[part 2 of 4: packages /BMW/SystemDescription/EcuInstances to /BMW/Boardnet/Clusters/CommunicationClusters]
AUTOSAR XML (schema 4-3-0)
package /BMW/SystemDescription/EcuInstances
  ecu instance EPS: associated-com-i-pdu-group=[EPS_IN_PduGroup, EPS_OUT_PduGroup, EPS_IN_PduGroup2, EPS_OUT_PduGroup2, EPS_IN_PduGroup3, EPS_IN_PduGroup4, EPS_IN_PduGroup5, EPS_IN_PduGroup6, EPS_IN_PduGroup7, EPS_IN_PduGroup8, EPS_IN_PduGroup9, EPS_OUT_PduGroup3, EPS_IN_PduGroup10], client-id-range={lower-limit=12288, upper-limit=12543}, diagnostic-address=48, sleep-mode-supported=false, wake-up-over-bus-supported=false  # Electrical Power - Assist - Steering | Achsparalleles EPS (electrical power-assist steering): System steuert unmittelbar Lenkschenkel an | MCV 0.94.5
    flexray communication controller contr_EPS_A_FlexRay:  # component: Electrical Power - Assist - Steering, bus: A-FlexRay / component: , bus: A-FlexRay
      accepted-startup-range=212
      allow-halt-due-to-clock=true
      allow-passive-to-active=0
      cluster-drift-damping=2
      decoding-correction=48
      delay-compensation-a=1
      delay-compensation-b=1
      extern-offset-correction=0
      extern-rate-correction=0
      key-slot-id=0
      key-slot-only-enabled=false
      key-slot-used-for-start-up=false
      key-slot-used-for-sync=false
      latest-tx=269
      listen-timeout=400242
      macro-initial-offset-a=3
      macro-initial-offset-b=3
      maximum-dynamic-payload-length=60
      micro-initial-offset-a=6
      micro-initial-offset-b=6
      micro-per-cycle=200000
      microtick-duration=2.5E-8
      offset-correction-out=126
      rate-correction-out=121
      samples-per-microtick=2
      wake-up-pattern=33
    flexray communication controller EPS_A_FlexRay:  # component: Electrical Power - Assist - Steering, bus: A-FlexRay / component: , bus: A-FlexRay
      accepted-startup-range=212
      allow-halt-due-to-clock=true
      allow-passive-to-active=0
      cluster-drift-damping=2
      decoding-correction=48
      delay-compensation-a=1
      delay-compensation-b=1
      extern-offset-correction=0
      extern-rate-correction=0
      key-slot-id=0
      key-slot-only-enabled=false
      key-slot-used-for-start-up=false
      key-slot-used-for-sync=false
      latest-tx=269
      listen-timeout=400242
      macro-initial-offset-a=3
      macro-initial-offset-b=3
      maximum-dynamic-payload-length=60
      micro-initial-offset-a=6
      micro-initial-offset-b=6
      micro-per-cycle=200000
      microtick-duration=2.5E-8
      offset-correction-out=126
      rate-correction-out=121
      samples-per-microtick=2
      wake-up-pattern=33
    flexray communication connector con_EPS_A_FlexRay: comm-controller=contr_EPS_A_FlexRay, wake-up-channel=true
    flexray communication connector con_EPS_FibexID_0b7e5e09c061465d913e8968ece3cded: comm-controller=EPS_A_FlexRay, wake-up-channel=true
package /BMW/SystemDescription/Units
  15 x unit:
    kilometer_per_hour: display-name=km/h
    meter_per_second_squared: display-name=m/s²
    kilonewton: display-name=kN
    kilowatt: display-name=kW
    degree_celsius: display-name=°C
    no_unit  # This unit fulfills the required AUTOSAR reference to a unit. No real unit is defined.
    radian_per_second: display-name=rad/s
    kilometer: display-name=km
    newton_meter: display-name=Nm
    liter: display-name=l
    ampere: display-name=A
    millisecond: display-name=ms
    percent: display-name=%
    degree_per_second: display-name=°/s
    second: display-name=s
package /BMW/SystemDescription/CompuMethods
  compu method TRANF_CC_EPS: phys=raw; unit s  # Sendeart_Checkcontrol_EPS / transmitting-form_check-control_EPS
  compu method AVL_PWR_EL: phys=raw*0.1-12; unit kW  # Ist_Leistung_Elektrisch / actual-value_power_electric
  compu method NO_VECH_1: identical  # Nummer_Fahrgestell_1 / number_vehicle-chassis_1
  compu method OFFS_QUAD_PINA_EPS: phys=raw-127  # Offset_Quadrant_Ritzelwinkel_EPS / offset_quadrant_pinion-angle_EPS
  compu method ST_UDP: 0=Kein Spannungseinbruch (ST_UDP_Kein_Spannungseinbruch) (kein Spannungseinbruch angekündigt oder aktiv), 1=Startspannungseinbruch bis maximal Spannungsschwelle 1 (ST_UDP_Startspannungseinbruch_bis_maximal_Spannungsschwelle_1) (Spannungseinbruch bis Schwelle 1 aktiv (z.B. Ankündigung vor Einbruch, bei Ansteuerung Startsystem, Nachlauf nach Abwurf Startsystem bis Normalisierung des BN-Niveaus) Siehe GS95024-2-1 (Kap. 4.11.2.2) Warmstart), 2=Startspannungseinbruch bis maximal Spannungsschwelle 2 (ST_UDP_Startspannungseinbruch_bis_maximal_Spannungsschwelle_2) (Spannungseinbruch bis Schwelle 2 aktiv (z.B. Ankündigung vor Einbruch, bei Ansteuerung Startsystem, Nachlauf nach Abwurf Startsystem bis Normalisierung des BN-Niveaus) Siehe GS95024-2-1 (Kap. 4.11.2.1) Kaltstart), 13=Funktionsschnittstelle_ist_nicht_verfuegbar (ST_UDP_Funktionsschnittstelle_ist_nicht_verfuegbar) (DME in der Initialisierung (z.B. nach Reset)), 14=Reserviert (ST_UDP_Reserviert) (Hinweis: Reserviert für funktionale Kennung Signal-Tag.), 15=Signal_unbefuellt (ST_UDP_Signal_unbefuellt) (Sendefunktion nicht in Betrieb)  # Status_Spannungseinbruch / status_voltage-drop
  compu method QU_FN_FDR: mask 3848: 512=Funktion verfügbar und bereit, nicht aktiv, Schlupfschwellen normal (QU_FN_FDR_Funktion_verfuegbar_und_bereit_nicht_aktiv_Schlupfschwellen_normal), mask 3848: 520=Funktion verfügbar und bereit, nicht aktiv, Schlupfschwellen aufgeweitet (QU_FN_FDR_Funktion_verfuegbar_und_bereit_nicht_aktiv_Schlupfschwellen_aufgeweitet), mask 3856: 2576=Funktion verfügbar und aktiv, FDR Regeleingriff VL (QU_FN_FDR_Funktion_verfuegbar_und_aktiv_FDR_Regeleingriff_VL), mask 3872: 2592=Funktion verfügbar und aktiv, FDR Regeleingriff VR (QU_FN_FDR_Funktion_verfuegbar_und_aktiv_FDR_Regeleingriff_VR), mask 3904: 2624=Funktion verfügbar und aktiv, FDR Regeleingriff HL (QU_FN_FDR_Funktion_verfuegbar_und_aktiv_FDR_Regeleingriff_HL), mask 3968: 2688=Funktion verfügbar und aktiv, FDR Regeleingriff HR (QU_FN_FDR_Funktion_verfuegbar_und_aktiv_FDR_Regeleingriff_HR), mask 3848: 2560=Funktion verfügbar und aktiv, Schlupfschwellen normal (QU_FN_FDR_Funktion_verfuegbar_und_aktiv_Schlupfschwellen_normal), mask 3848: 2568=Funktion verfügbar und aktiv, Schlupfschwellen aufgeweitet (QU_FN_FDR_Funktion_verfuegbar_und_aktiv_Schlupfschwellen_aufgeweitet), mask 3840: 1536=Funktion nicht verfügbar: Fehler (QU_FN_FDR_Funktion_nicht_verfuegbar_Fehler), mask 3840: 3584=Funktion nicht verfügbar: Ausgeschaltet (QU_FN_FDR_Funktion_nicht_verfuegbar_Ausgeschaltet) (Diese Codierung wird versendet wenn mind. eine dieser Bedingungen erfüllt ist: Initialisierungsphase des SG (Vorbefüllung), Zündung=aus, Motorstart, INITAusblendung aktiv, Funktion über DTC-Taster deaktiviert), mask 3840: 2048=reserviert (QU_FN_FDR_reserviert), mask 3840: 512=reserviert (QU_FN_FDR_reserviert_2), mask 3848: 768=reserviert (QU_FN_FDR_reserviert_3), mask 3848: 776=reserviert (QU_FN_FDR_reserviert_4), mask 4095: 4095=Signal ungültig (QU_FN_FDR_Signal_ungueltig) (Nutzung nur vom Gateway, nicht seitens Sender-SG)  # Qualifier_Funktion_FDR / Qualifier_function_FDR
  compu method TEMP_CPO_HET_MNG: phys=raw-48 for raw 0..252, 253=Reserviert (TEMP_CPO_HET_MNG_Reserviert) (Hinweis: Reserviert für funktionale Kennung Signal-Tag.), 254=Reserviert (TEMP_CPO_HET_MNG_Reserviert_2) (Hinweis: Reserviert für funktionale Kennung Signal-Tag.), 255=Signal_unbefuellt (TEMP_CPO_HET_MNG_Signal_unbefuellt) (Sendefunktion nicht in Betrieb); unit °C  # Temperatur_Komponente_Wärme_Management / temperature_component_heat_management
  compu method ST_ANO_MSA_ENG_STOP: 0=Kein Ankündigung (ST_ANO_MSA_ENG_STOP_Kein_Ankuendigung) (kein MSA-Motorstopp angekündigt oder aktiv), 1=Ankündigung MSA-Motorstopp (ST_ANO_MSA_ENG_STOP_Ankuendigung_MSA_Motorstopp) (MSA-Motorstopp angekündigt oder aktiv in Durchführung), 3=Signal ungültig (ST_ANO_MSA_ENG_STOP_Signal_ungueltig)  # Status_Ankündigung_MSA_Motor_Stop / status_announcement_MSA_engine_stop
  compu method STU_RESP: phys=raw  # Signatur_Response / signature_response
  compu method QU_ACLNY_COG: 8=Initialisierung (QU_ACLNY_COG_Initialisierung) (Tritt während der Initialisierungsphase auf bis Ist-Wert verfügbar (Vorbefüllung). Nutzsignal wird permanent mit Nutzwert 0 befüllt.), 1=Signalwert ist gültig und abgesichert und plausibilisiert (QU_ACLNY_COG_Signalwert_ist_gueltig_und_abgesichert_und_plausibilisiert) (Nutzsignal verfügbar, bereitgestellt aus zwei Sensoren (nur bei redundanter Sensorik) elektrische und Modellüberwachung i.O.), 9=Signalwert ist gültig und abgesichert, Zustand/Status temporär (QU_ACLNY_COG_Signalwert_ist_gueltig_und_abgesichert_Zustand_Status_temporaer) (Nutzsignal verfügbar; elektrische und Modellüberwachung i.O. Es liegt eine Signaltoleranz aufgrund nicht abgeschlossenen Offsetabgleichs an. FuSi : Bei sicherheitsrelevanten Funktionen ist die Fehleramplitude auszuwerten), 2=Signalwert ist gültig (QU_ACLNY_COG_Signalwert_ist_gueltig) (Nutzsignal verfügbar, bereitgestellt aus einem Sensor (Nur bei einfacher Sensorik) elektrische und Modellüberwachung i.O.), 10=Signalwert ist gültig, Zustand/Status temporär (QU_ACLNY_COG_Signalwert_ist_gueltig_Zustand_Status_temporaer) (Nutzsignal verfügbar, bereitgestellt aus einem Sensor elektrische und Modellüberwachung i.O. Es liegt eine Signaltoleranz aufgrund nicht abgeschlossenen Offsetabgleichs an. FuSi : Bei sicherheitsrelevanten Funktionen ist die Fehleramplitude auszuwerten), 3=Signalqualität bzw. Überwachung eingeschränkt (QU_ACLNY_COG_Signalqualitaet_bzw_Ueberwachung_eingeschraenkt) (keine Modellüberwachung, da Eingangsgrößen für Überwachung fehlen (zum Bsp. Gierrate), elektrische Überwachung i.O. Nutzsignal wird aus Sensorwert gebildet. FuSi: keine Verwendung für sicherheitsrelevante Funktionen), 11=Signalqualität bzw. Überwachung eingeschränkt, Zustand/Status temporär (QU_ACLNY_COG_Signalqualitaet_bzw_Ueberwachung_eingeschraenkt_Zustand_Status_temporaer) (keine Modellüberwachung, da Eingangsgrößen für Überwachung fehlen (zum Bsp. Gierrate), elektrische Überwachung i.O. Es liegt eine Signaltoleranz aufgrund nicht abgeschlossenen Offsetabgleichs an. Nutzsignal wird aus Sensorwert gebildet. FuSi: keine Verwendung für sicherheitsrelevante Funktionen), 4=Reserved (QU_ACLNY_COG_Reserved), 12=Ersatzwert ist im Nutzsignal gesetzt, Zustand/Status temporär (QU_ACLNY_COG_Ersatzwert_ist_im_Nutzsignal_gesetzt_Zustand_Status_temporaer) (elektrische Überwachung oder Modellüberwachung zeigt Fehler an, deshalb wird Ersatzwert aus Modell versendet FuSi: keine Verwendung für sicherheitsrelevante Funktionen), 6=Signalwert ist ungültig (QU_ACLNY_COG_Signalwert_ist_ungueltig) (Das zugehörige Nutzsignal wird permanent mit der Ungültigkeitskennung befüllt. elektrische Überwachung oder Modellüberwachung zeigt Fehler an, kein Ersatzwert verfügbar. Diese Codierung wird ab SP2015 nicht mehr bedient.), 14=Signalwert ist ungültig, Zustand/Status temporär (QU_ACLNY_COG_Signalwert_ist_ungueltig_Zustand_Status_temporaer) (Das zugehörige Nutzsignal wird permanent mit der Ungültigkeitskennung befüllt. elektrische Überwachung oder Modellüberwachung zeigt Fehler an, kein Ersatzwert verfügbar), 7=Reserved (QU_ACLNY_COG_Reserved_2), 15=Signal ungültig (QU_ACLNY_COG_Signal_ungueltig) (Kann nur vom Gateway gesetzt werden)  # Qualifier_Querbeschleunigung_Schwerpunkt / Qualifier_lateral-acceleration_centre-of-gravity
  compu method NO_CC_EPS: phys=raw  # Nummer_Checkcontrol_EPS / number_check-control_EPS
  compu method ID_FN_RQ_STG_EFAN: 1=AFS-Anforderung (ID_FN_RQ_STG_EFAN_AFS_Anforderung) (Diese Nachricht darf vom AFS ausschließlich zum Bauteilschutz im Notfall versandt werden! Anforderung wird vom E6x/PL2/PL4 AFS nicht mehr versendet.), 2=EPS-Anforderung (ID_FN_RQ_STG_EFAN_EPS_Anforderung) (Diese Nachricht darf vom EPS ausschließlich zum Bauteilschutz im Notfall versandt werden!), 3=DSC-Anforderung (ID_FN_RQ_STG_EFAN_DSC_Anforderung) (Diese Nachricht darf vom DSC ausschließlich zum Bauteilschutz im Notfall versandt werden!), 4=Servotronic-Anforderung (ID_FN_RQ_STG_EFAN_Servotronic_Anforderung) (Diese Kodierung wird _nicht_ in den Baureihen L1 bis L5 verwendet. Diese Nachricht darf ausschließlich zum Bauteilschutz im Notfall versandt werden!), 255=Signal ungültig (ID_FN_RQ_STG_EFAN_Signal_ungueltig)  # ID_Funktion_Anforderung_Stufe_Elektrolüfter / ID_function_request_stage_electric-fan
  compu method ST_CC_EPS: 0=Rücksetzen (ST_CC_EPS_Ruecksetzen) (Betreffende CC-message wird gelöscht), 1=Setzen (ST_CC_EPS_Setzen) (CC-message display), 3=Signal ungültig (ST_CC_EPS_Signal_ungueltig)  # Status_Checkcontrol_EPS / status_check-control_EPS
  compu method ST_DIAG_OBD_MUX_MAX: phys=raw  # Status_Diagnose_OBD_Multiplexer_Maximal / status_diagnosis_OBD_multiplexer_maximum
  compu method ALIV_COU_V: 0..14=Zählerstand 0..E (Nach dem Zählerstand 14 wird zyklisch bei 0 wieder begonnen. / After counter reading 14, the counter restarts at 0 again in cycles), 15=Signal ungültig (ALIV_COU_V_Signal_ungueltig)  # Alive_Zähler_Geschwindigkeit / alive_counter_speed
  compu method AVL_FORC_GRD: phys=raw*0.0084-17; unit kN  # Ist_Kraft_Zahnstange / actual-value_force_gear-rod
  compu method STMOM_QTA_DV: phys=raw*0.005-10; unit Nm  # Lenkmoment_Anteil_Fahrer / steering-moment_quota_driver
  compu method ALIV_4_BIT_UInt: phys=raw  # Alive_4_Bit_UInt / alive_4_bit_UInt
  compu method ST_DCSW: 0=Trennelement auf 24V (ST_DCSW_Trennelement_auf_24V) (Kein Fehler - Trennelement ist auf Position 24V. (bei 150W und 750W PCU)), 1=Trennelement wird auf 12V umgeschaltet werden (ST_DCSW_Trennelement_wird_auf_12V_umgeschaltet_werden) (Trennelement wird von Position 24V auf Position 12V umgeschaltet werden (bei 150W und 750W PCU)), 2=Trennelement auf 12V (ST_DCSW_Trennelement_auf_12V) (Trennelement ist auf Position 12V. (bei 150W und 750W PCU)), 3=Signal ungültig (ST_DCSW_Signal_ungueltig)  # Status_Trennschalter / status_disconnecting-switch
  compu method SECU_CHAL: phys=raw  # Sicher_Challenge / secure_challenge
  compu method STU_8_BYTE: phys=raw  # Signatur_8_Byte / signature_8_byte
  compu method ST_CULI_EST: 0=Keine_Strombegrenzung (ST_CULI_EST_Keine_Strombegrenzung) (Keine Strombegrenzung aktiv.), 1=Komfort_Strombegrenzung (ST_CULI_EST_Komfort_Strombegrenzung) (Strombegrenzung über ELMa aktiv.), 10=Maximale_Strombegrenzung (ST_CULI_EST_Maximale_Strombegrenzung) (Sicherheits-Strombegrenzung aktiv), 13=Reserviert_nicht_verfuegbar (ST_CULI_EST_Reserviert_nicht_verfuegbar) (Hinweis: Reserviert für funktionale Kennung Signal-Tag.), 14=Reserviert_Fehler (ST_CULI_EST_Reserviert_Fehler) (Hinweis: Reserviert für funktionale Kennung Signal-Tag.), 15=Signal_unbefuellt (ST_CULI_EST_Signal_unbefuellt) (Sendefunktion nicht in Betrieb)  # Status_Strombegrenzung_Elektrische-Lenkung / status_current-limitation_electrical-steering
  compu method FACT_CTRR_STMOM_FTAX: phys=raw/256+0.0078125  # Faktor_Zentrierung_Lenkmoment_Vorderachse / factor_centering_steering-moment_front-axle
  compu method DVCO_VEH: 0=Fahrzeug steht (DVCO_VEH_Fahrzeug_steht) (Siehe Signalbeschreibung / See above), 1=Fahrzeug fährt vorwärts (DVCO_VEH_Fahrzeug_faehrt_vorwaerts) (VL und VR vorwärts / FL and FR forwards), 2=Fahrzeug fährt rückwärts (DVCO_VEH_Fahrzeug_faehrt_rueckwaerts) (VL und VR rückwärts / FL and FR backwards), 3=Fahrzeug fährt (DVCO_VEH_Fahrzeug_faehrt) (Richtungserkennung noch nicht erfolgt oder nicht möglich z.B. Luftspalt zu groß / Direction recognition not possible, e.g. air gap too large), 4=Fahrzeug steht, Hinterachse auf Rollenprüfstand erkannt (DVCO_VEH_Fahrzeug_steht_Hinterachse_auf_Rollenpruefstand_erkannt) (Fahrzeug auf Hinterachs-Ein-Achs- Rollenprüfstand erkannt. Signalverhalten von Geschwindigkeit_Fahrzeug_Schwerpunkt siehe Signalbeschreibung DVCO_VEH), 5=Fahrzeug steht, Zwei-Achs-Rollenbetrieb gesetzt (DVCO_VEH_Fahrzeug_steht_Zwei_Achs_Rollenbetrieb_gesetzt) (Codierung wird beim CAS4 im F25 erst ab I400 richtig interpretiert. Signal Geschwindigkeit_Fahrzeug_Schwerpunkt entspricht der Rollengeschwindigkeit, Details siehe Signalbeschreibung), 6=Fahrzeug steht, Vorderachse auf Rollenprüfstand erkannt (DVCO_VEH_Fahrzeug_steht_Vorderachse_auf_Rollenpruefstand_erkannt) (Fahrzeug auf Vorderachs-Ein-Achs-Rollenprüfstand erkannt. (Bit kann erst ab SP2013 gesetzt werden) Signalverhalten von Geschwindigkeit_Fahrzeug_Schwerpunkt siehe Signalbeschreibung DVCO_VEH), 7=Signal ungültig (DVCO_VEH_Signal_ungueltig) (Wird beim Aufstarten gesetzt, solange kein gültiger Zustand ermittelt werden kann und beim Auftreten eines Kommunikationsfehlers.)  # Fahrzustand_Fahrzeug / driving-condition_vehicle
  compu method QU_TAR_FACT_STMOM_FTAX: 2=Sollwerte umsetzen (QU_TAR_FACT_STMOM_FTAX_Sollwerte_umsetzen) (Es wird ein Lenkmoment angefordert.), 7=Sollwerte nicht vorhanden (QU_TAR_FACT_STMOM_FTAX_Sollwerte_nicht_vorhanden) (Wird immer gesetzt wenn keine EPS verbaut ist.), 14=Standby: Sollwerte nicht umsetzen (QU_TAR_FACT_STMOM_FTAX_Standby_Sollwerte_nicht_umsetzen) (Es wird kein Moment angefordert. Wird auch im Fehlerfall gesetzt.), 15=Signal ungültig (QU_TAR_FACT_STMOM_FTAX_Signal_ungueltig) (Wird nicht aktiv gesetzt)  # Qualifier_Soll_Faktor_Lenkmoment_Vorderachse / Qualifier_target_factor_steering-moment_front-axle
  compu method VYAW_VEH: phys=raw*0.005-163.84; unit °/s  # Giergeschwindigkeit_Fahrzeug / yaw-velocity_vehicle
  compu method ALIV_4_BIT_Unsigned_Integer: phys=raw  # Alive_4_Bit_Unsigned_Integer / alive_4_bit_Unsigned_Integer
  compu method RQ_CULI: 0=Keine_Strombegrenzung (RQ_CULI_Keine_Strombegrenzung) (Keine Strombegrenzung angefordert.), 10=Maximale_Strombegrenzung (RQ_CULI_Maximale_Strombegrenzung) (Sicherheits-Strombegrenzung angefordert.), 13=Reserviert_nicht_verfuegbar (RQ_CULI_Reserviert_nicht_verfuegbar) (Hinweis: Reserviert für funktionale Kennung Signal-Tag.), 14=Reserviert_Fehler (RQ_CULI_Reserviert_Fehler) (Hinweis: Reserviert für funktionale Kennung Signal-Tag.), 15=Signal_unbefuellt (RQ_CULI_Signal_unbefuellt) (Sendefunktion nicht in Betrieb)  # Anforderung_Strombegrenzung / request_current-limitation
  compu method AVL_RPM_WHL: phys=raw/64-511.984375; unit rad/s  # Ist_Drehzahl_Rad / actual-value_RPM_wheel
  compu method MILE_KM: phys=raw; unit km  # Wegstrecke_Kilometer / mileage_kilometre
  compu method NO_VECH_7: identical  # Nummer_Fahrgestell_7 / number_vehicle-chassis_7
  compu method ST_MOT_DRV: 0=Kein E-Maschine verfügbar (ST_MOT_DRV_Kein_E_Maschine_verfuegbar) (Keine Traktions-E-Maschine verfügbar, oder Traktions-E-Maschine(n) nicht bereit, oder elektrische Fahrbereitschaft nicht zulässig.), 1=E-Maschine ist elektrisch fahrbereit oder bereits aktiv (ST_MOT_DRV_E_Maschine_ist_elektrisch_fahrbereit_oder_bereits_aktiv) (Hochvoltsystem ist aktiv, Traktions-E-Maschine(n) bereit und elektrische Fahrbereitschaft zulässig.), 3=Signal ungültig (ST_MOT_DRV_Signal_ungueltig)  # Status_E-Motor_Antrieb / status_motor_drive
  compu method ST_LDREL_GEN: 0=Keine Entlastungsfkt. Aktiv / Rücknahme (ST_LDREL_GEN_Keine_Entlastungsfkt_Aktiv_Ruecknahme), 1=iGR-High (ST_LDREL_GEN_iGR_High), 2=SULEV-Fkt (ST_LDREL_GEN_SULEV_Fkt), 3=Entlastung nach Motorstart (ST_LDREL_GEN_Entlastung_nach_Motorstart), 4=Rennstart mit oder ohne AGM Batterie (ST_LDREL_GEN_Rennstart_mit_oder_ohne_AGM_Batterie), 5=ELMOTENTL Hitze (ST_LDREL_GEN_ELMOTENTL_Hitze), 6=ELMOTENTL Kälte (ST_LDREL_GEN_ELMOTENTL_Kaelte), 7=Entlastung Anfahrschwäche wie P66,P85 (ST_LDREL_GEN_Entlastung_Anfahrschwaeche_wie_P66_P85), 8=Übertemperatur Generator (ST_LDREL_GEN_Uebertemperatur_Generator), 9=Entlastung aus Sicherheitsgründen (ST_LDREL_GEN_Entlastung_aus_Sicherheitsgruenden), 10=Entlastung Begrenzung Lagerkräfte (ST_LDREL_GEN_Entlastung_Begrenzung_Lagerkraefte), 11=Entlastung aus Komfortgründen (ST_LDREL_GEN_Entlastung_aus_Komfortgruenden), 12=Entlastung aus funktionalen Gründen (ST_LDREL_GEN_Entlastung_aus_funktionalen_Gruenden), 15=Signal ungültig (ST_LDREL_GEN_Signal_ungueltig)  # Status_Entlastung_Generator / status_load-relieving_generator
  compu method I_SPEC_ARS: phys=raw for raw 0..252, 253=Funktionsschnittstelle_ist_nicht_verfuegbar (I_SPEC_ARS_Funktionsschnittstelle_ist_nicht_verfuegbar) (Sendefunktion in Betrieb, Werte nicht verfügbar), 254=Funktion_meldet_Fehler (I_SPEC_ARS_Funktion_meldet_Fehler) (Nutzsignal kann nicht berechnet werden), 255=Signal_unbefuellt (I_SPEC_ARS_Signal_unbefuellt) (Sendefunktion nicht in Betrieb); unit A  # Strom_Vorgabe_ARS / current_specification_ARS
  compu method FACT_DMPNG_ADDON_STMOM_FTAX: phys=raw/64 for raw 0..128, 253=Reserviert (FACT_DMPNG_ADDON_STMOM_FTAX_Reserviert) (Hinweis: Reserviert für funktionale Kennung Signal-Tag.), 254=Reserviert (FACT_DMPNG_ADDON_STMOM_FTAX_Reserviert_2) (Hinweis: Reserviert für funktionale Kennung Signal-Tag.), 255=Signal_unbefuellt (FACT_DMPNG_ADDON_STMOM_FTAX_Signal_unbefuellt) (Sendefunktion nicht in Betrieb)  # Faktor_Dämpfung_Zusatz_Lenkmoment_Vorderachse / factor_damping_add-on_steering-moment_front-axle
  compu method ST_OBD_CYC: mask 9: 0=Warm-Up-Zyklus nicht aktiv (ST_OBD_CYC_Warm_Up_Zyklus_nicht_aktiv), mask 9: 1=Warm-Up-Zyklus aktiv (ST_OBD_CYC_Warm_Up_Zyklus_aktiv), mask 10: 0=Driving-Zyklus nicht aktiv (ST_OBD_CYC_Driving_Zyklus_nicht_aktiv), mask 10: 2=Driving-Zyklus aktiv (ST_OBD_CYC_Driving_Zyklus_aktiv), mask 44: 0=RBM-Zyklus nicht aktiv (ST_OBD_CYC_RBM_Zyklus_nicht_aktiv), mask 44: 4=RBM-Zyklus aktiv (ST_OBD_CYC_RBM_Zyklus_aktiv), mask 44: 32=RBM-Zyklus nicht erfüllbar (ST_OBD_CYC_RBM_Zyklus_nicht_erfuellbar), mask 24: 0=Kein PFC-Zyklus (ST_OBD_CYC_Kein_PFC_Zyklus), mask 24: 16=PFC-Zyklus erfüllt (ST_OBD_CYC_PFC_Zyklus_erfuellt), mask 63: 63=Signal ungültig (ST_OBD_CYC_Signal_ungueltig)  # Status_OBD_Zyklus / status_OBD_cycle
  compu method ACLNY_COG: phys=raw*0.002-65; unit m/s²  # Querbeschleunigung_Schwerpunkt / lateral-acceleration_centre-of-gravity
  compu method MIN_I_SPEC_ARS: phys=raw-252 for raw 0..252, 253=Funktionsschnittstelle_ist_nicht_verfuegbar (MIN_I_SPEC_ARS_Funktionsschnittstelle_ist_nicht_verfuegbar) (Sendefunktion in Betrieb, Werte nicht verfügbar), 254=Funktion_meldet_Fehler (MIN_I_SPEC_ARS_Funktion_meldet_Fehler) (Nutzsignal kann nicht berechnet werden), 255=Signal_unbefuellt (MIN_I_SPEC_ARS_Signal_unbefuellt) (Sendefunktion nicht in Betrieb); unit A  # Minimal_Strom_Vorgabe_ARS / minimum_current_specification_ARS
  compu method DBG_8Bit: phys=raw  # Debug_8Bit / debug_8Bit
  compu method UN_TOT_STR_EPS: 0=Ritzelschnittstelle (UN_TOT_STR_EPS_Ritzelschnittstelle) (Die Position wird in Grad übertragen), 1=Zahnstangenhubschnittstelle (UN_TOT_STR_EPS_Zahnstangenhubschnittstelle) (Die Position wird in Millimeter übertragen (Einheit: 0.2mm)), 3=Signal ungültig (UN_TOT_STR_EPS_Signal_ungueltig)  # Einheit_Gesamt_Lenkübersetzung_EPS / unit-of-measurement_total_steering-ratio_EPS
  compu method ALIV_COU_4: 0..14=Zählerstand 0..E (Nach dem Zählerstand 14 wird zyklisch bei 0 wieder begonnen. / After counter reading 14, the counter restarts at 0 again in cycles), 15=Signal ungültig (ALIV_COU_4_Signal_ungueltig)  # Alive_Zähler_4 / alive_counter_4
  compu method NO_VECH_6: identical  # Nummer_Fahrgestell_6 / number_vehicle-chassis_6
  compu method AVL_STEA_PNI_OFFS: phys=raw*0.021994-45 for raw 0..4092, 4093=Funktionsschnittstelle_ist_nicht_verfuegbar (AVL_STEA_PNI_OFFS_Funktionsschnittstelle_ist_nicht_verfuegbar) (Signal Tag - Schnittstelle ist nicht verfügbar), 4094=Funktion_meldet_Fehler (AVL_STEA_PNI_OFFS_Funktion_meldet_Fehler) (Signal Tag - Funktion meldet Fehler), 4095=Signal_unbefuellt (AVL_STEA_PNI_OFFS_Signal_unbefuellt) (Signal Tag - Signal ist unbefüllt)  # Ist_Lenkwinkel_Ritzel_Offset / actual-value_steering-angle_pinion_offset
  compu method ACTVN_FN_ESTP_VIRT_FTAX: 0=Funktion virtueller Endanschlag deaktivieren (ACTVN_FN_ESTP_VIRT_FTAX_Funktion_virtueller_Endanschlag_deaktivieren) (Funktion virtueller Endanschlag deaktivieren durch Fahrzeugführung), 1=Funktion virtueller Endanschlag aktivieren (ACTVN_FN_ESTP_VIRT_FTAX_Funktion_virtueller_Endanschlag_aktivieren) (Funktion virtueller Endanschlag aktivieren durch Fahrzeugführung), 13=Funktionsschnittstelle_ist_nicht_verfuegbar (ACTVN_FN_ESTP_VIRT_FTAX_Funktionsschnittstelle_ist_nicht_verfuegbar) (Sendefunktion in Betrieb, Werte nicht verfügbar), 14=Funktion_meldet_Fehler (ACTVN_FN_ESTP_VIRT_FTAX_Funktion_meldet_Fehler) (Sendefunktion in Betrieb, meldet Fehler), 15=Signal_unbefuellt (ACTVN_FN_ESTP_VIRT_FTAX_Signal_unbefuellt) (Sendefunktion nicht in Betrieb)  # Aktivierung_Funktion_Endanschlag_Virtuell_Vorderachse / activation_function_end-stop_virtual_front-axle
  compu method VYAW_VEH_ERR_AMP: phys=raw*0.0125; unit °/s  # Giergeschwindigkeit_Fahrzeug_Fehler_Amplitude / yaw-velocity_vehicle_error_amplidue
  compu method QU_TAR_STMOM_DV_ACT: 2=Sollwerte umsetzen (QU_TAR_STMOM_DV_ACT_Sollwerte_umsetzen) (Es wird ein Lenkmoment angefordert.), 7=Sollwerte nicht vorhanden (QU_TAR_STMOM_DV_ACT_Sollwerte_nicht_vorhanden) (Wird immer gesetzt wenn keine EPS verbaut ist), 14=Standby: Sollwerte nicht umsetzen (QU_TAR_STMOM_DV_ACT_Standby_Sollwerte_nicht_umsetzen) (Es wird kein Moment angefordert. Wird auch im Fehlerfall gesetzt.), 15=Signal ungültig (QU_TAR_STMOM_DV_ACT_Signal_ungueltig) (Wird nicht aktiv gesetzt)  # Qualifier_Soll_Lenkmoment_Fahrer_Stellglied / Qualifier_target_steering-moment_driver_actuator
  compu method RQ_CULI_EST_SFY: 0=Keine_Strombegrenzung (RQ_CULI_EST_SFY_Keine_Strombegrenzung) (Keine Strombegrenzung angefordert.), 1=Komfort_Strombegrenzung (RQ_CULI_EST_SFY_Komfort_Strombegrenzung) (Strombegrenzung über ELMa angefordert.), 10=Maximale_Strombegrenzung (RQ_CULI_EST_SFY_Maximale_Strombegrenzung) (Sicherheits-Strombegrenzung angefordert.), 13=Reserviert_nicht_verfuegbar (RQ_CULI_EST_SFY_Reserviert_nicht_verfuegbar) (Hinweis: Reserviert für funktionale Kennung Signal-Tag.), 14=Reserviert_Fehler (RQ_CULI_EST_SFY_Reserviert_Fehler) (Hinweis: Reserviert für funktionale Kennung Signal-Tag.), 15=Signal_unbefuellt (RQ_CULI_EST_SFY_Signal_unbefuellt) (Sendefunktion nicht in Betrieb)  # Anforderung_Strombegrenzung_Elektrische-Lenkung_Sicherheit / request_current-limitation_electrical-steering_safety
  compu method OFFS_GRD_MID_EPS: phys=raw*0.0439453125-89.95605469  # Offset_Zahnstange_Mitte_EPS / offset_gear-rod_middle_EPS
  compu method QU_SER_STMOM_STMOM_DV_ACT: 128=Schnittstelle wird initialisiert (QU_SER_STMOM_STMOM_DV_ACT_Schnittstelle_wird_initialisiert) (Wird beim Hochfahren des Steuergerätes gesetzt (Vorbefüllung).), 32=Schnittstelle verfügbar / funktionsbereit ohne Zusatzdämpfung (QU_SER_STMOM_STMOM_DV_ACT_Schnittstelle_verfuegbar_funktionsbereit_ohne_Zusatzdaempfung) (Schnittsstelle verfügbar/funktionsbereit.), 34=Schnittstelle verfügbar / funktionsbereit mit Zusatzdämpfung (QU_SER_STMOM_STMOM_DV_ACT_Schnittstelle_verfuegbar_funktionsbereit_mit_Zusatzdaempfung) (Wird bei EPS mit Dämpfungfunktion versendet.), 33=Schnittstelle aktiv - Zusatzdämpfung nicht verfügbar (QU_SER_STMOM_STMOM_DV_ACT_Schnittstelle_aktiv_Zusatzdaempfung_nicht_verfuegbar) (Schnittstelle aktiv (ohne Zusatzdämpfung)), 35=Schnittstelle aktiv - Zusatzdämpfung verfügbar (QU_SER_STMOM_STMOM_DV_ACT_Schnittstelle_aktiv_Zusatzdaempfung_verfuegbar) (Wird bei EPS mit Dämpfungfunktion versendet.), 96=Service nicht verfügbar - Fehler (QU_SER_STMOM_STMOM_DV_ACT_Service_nicht_verfuegbar_Fehler) (EPS Zustand = Fehler.), 224=Service nicht verfügbar - Standby - PMA (QU_SER_STMOM_STMOM_DV_ACT_Service_nicht_verfuegbar_Standby_PMA) (PMA aktiv deshalb Fahrdynamik Schnittstelle inaktiv.), 225=Service nicht verfügbar - Standby - EPS Status (QU_SER_STMOM_STMOM_DV_ACT_Service_nicht_verfuegbar_Standby_EPS_Status) (Wird verwendet für alle andere EPS Zustände als: -Verfügbar -Fehler Fahrdynamik Schnittstelle inaktiv.), 255=Signal ungültig (QU_SER_STMOM_STMOM_DV_ACT_Signal_ungueltig) (Wird Funktional nicht versendet.)  # Qualifier_Service_Lenkmoment_Lenkmoment_Fahrer_Stellglied / Qualifier_service_steering-moment_steering-moment_driver_actuator
  compu method ST_DIAG_OBD_MUX_IMME: phys=raw for raw 4..60, 1=Cal-ID (software calibration identification) (ST_DIAG_OBD_MUX_IMME_Cal_ID_software_calibration_identification_), 2=CVN (software calibration verification number) (ST_DIAG_OBD_MUX_IMME_CVN_software_calibration_verification_number_), 63=Ungültig (ST_DIAG_OBD_MUX_IMME_Ungueltig) (Wird funktional nicht bedient.)  # Status_Diagnose_OBD_Multiplexer_Aktuell / status_diagnosis_OBD_multiplexer_immediate
  compu method QU_VYAW_VEH: 8=Initialisierung (QU_VYAW_VEH_Initialisierung) (Tritt während der Initialisierungsphase auf bis Ist-Wert verfügbar (Vorbefüllung). Nutzsignal wird permanent mit Nutzwert 0 befüllt.), 1=Signalwert ist gültig und abgesichert und plausibilisiert (QU_VYAW_VEH_Signalwert_ist_gueltig_und_abgesichert_und_plausibilisiert) (Nutzsignal verfügbar, bereitgestellt aus zwei Sensoren (nur bei redundanter Sensorik) elektrische und Modellüberwachung i.O.), 9=Signalwert ist gültig und abgesichert, Zustand/Status temporär (QU_VYAW_VEH_Signalwert_ist_gueltig_und_abgesichert_Zustand_Status_temporaer) (Nutzsignal verfügbar, bereitgestellt aus zwei Sensoren (nur bei redundanter Sensorik) elektrische und Modellüberwachung i.O. Es liegt eine Signaltoleranz aufgrund nicht abgeschlossenen Offsetabgleichs an. FuSi : Bei sicherheitsrelevanten Funktionen ist die Fehleramplitude auszuwerten), 2=Signalwert ist gültig (QU_VYAW_VEH_Signalwert_ist_gueltig) (Nutzsignal verfügbar, bereitgestellt aus einem Sensor elektrische und Modellüberwachung i.O.), 10=Signalwert ist gültig, Zustand/Status temporär (QU_VYAW_VEH_Signalwert_ist_gueltig_Zustand_Status_temporaer) (Nutzsignal verfügbar, bereitgestellt aus einem Sensor elektrische und Modellüberwachung i.O. Es liegt eine Signaltoleranz aufgrund nicht abgeschlossenen Offsetabgleichs an. FuSi : Bei sicherheitsrelevanten Funktionen ist die Fehleramplitude auszuwerten.), 3=Signalqualität bzw. Überwachung eingeschränkt (QU_VYAW_VEH_Signalqualitaet_bzw_Ueberwachung_eingeschraenkt) (keine Modellüberwachung, da Eingangsgrößen für Überwachung fehlen (zum Bsp. Querbeschleunigung, Lenkwinkel, ...), elektrische Überwachung i.O Nutzsignal wird aus Sensorwert gebildet. FuSi: keine Verwendung für sicherheitsrelevante Funktionen), 11=Signalqualität bzw. Überwachung eingeschränkt, Zustand/Status temporär (QU_VYAW_VEH_Signalqualitaet_bzw_Ueberwachung_eingeschraenkt_Zustand_Status_temporaer) (keine Modellüberwachung, da Eingangsgrößen für Überwachung fehlen (zum Bsp. Querbeschleunigung, Lenkwinkel, ...), elektrische Überwachung i.O Es liegt eine Signaltoleranz aufgrund nicht abgeschlossenen Offsetabgleichs an. Nutzsignal wird aus Sensorwert gebildet. FuSi : Bei sicherheitsrelevanten Funktionen ist die Fehleramplitude auszuwerten), 4=Reserved (QU_VYAW_VEH_Reserved), 12=Ersatzwert: Abgleichwert ist im Nutzsignal gesetzt, Zustand/Status temporär (QU_VYAW_VEH_Ersatzwert_Abgleichwert_ist_im_Nutzsignal_gesetzt_Zustand_Status_temporaer) (elektrische Überwachung oder Modellüberwachung zeigt Fehler an, deshalb wird Ersatzwert aus Modell (Lenkwinkel) versendet FuSi: keine Verwendung für sicherheitsrelevante Funktionen), 6=Signalwert ist ungültig (QU_VYAW_VEH_Signalwert_ist_ungueltig) (elektrische Überwachung oder Modellüberwachung zeigt Fehler an, kein Ersatzwert verfügbar (Steuergerät interner Fehler). Das zugehörige Nutzsignal wird permanent mit der Ungültigkeitskennung befüllt. Diese Codierung wird ab SP2015 nicht mehr bedient.), 14=Signalwert ist ungültig, Zustand/Status temporär (QU_VYAW_VEH_Signalwert_ist_ungueltig_Zustand_Status_temporaer) (elektrische Überwachung oder Modellüberwachung zeigt Fehler an, kein Ersatzwert verfügbar (Eingangssignale Fehler). Das zugehörige Nutzsignal wird permanent mit der Ungültigkeitskennung befüllt.), 7=Reserved (QU_VYAW_VEH_Reserved_2), 15=Signal ungültig (QU_VYAW_VEH_Signal_ungueltig) (Kann nur vom Gateway gesetzt werden)  # Qualifier_Giergeschwindigkeit_Fahrzeug / Qualifier_yaw-velocity_vehicle
  compu method ST_ILK_ERRM_FZM: 0=Fehlerspeicherfreigabe (ST_ILK_ERRM_FZM_Fehlerspeicherfreigabe) (Eintrag von Fehlern uneingeschränkt), 1=Fehlerspeichersperre (ST_ILK_ERRM_FZM_Fehlerspeichersperre) (Bereich Netzwerkfehler ist zu sperren), 2=Reserve (ST_ILK_ERRM_FZM_Reserve) (reserviert für zukünftige Erweiterungen), 3=Signal ungültig (ST_ILK_ERRM_FZM_Signal_ungueltig)  # Status_Sperre_Fehlerspeicher_FZM / status_interlock_error-memory_FZM
  compu method CRC_V_VEH: phys=raw  # CRC_Geschwindigkeit_Fahrzeug / CRC_speed_vehicle
  compu method QU_FN_VIB_EPS: 1=Funktion_verfuegbar_nicht_aktiv (QU_FN_VIB_EPS_Funktion_verfuegbar_nicht_aktiv) (Funktion EPS-Lenkradvibration ist verfügbar, Vibration ist aber nicht aktiv.), 9=Funktion_verfuegbar_aktiv (QU_FN_VIB_EPS_Funktion_verfuegbar_aktiv) (Funktion EPS-Lenkradvibration ist verfügbar und Vibration ist aktiv), 14=Funktion_nicht_verfuegbar (QU_FN_VIB_EPS_Funktion_nicht_verfuegbar) (Funktion EPS-Lenkradvibration ist temporär nicht verfügbar Dieser Zustand stellt sich dann ein, wenn die Funktion aufgrund eines EPS-internen Fehlers oder einer Degradation vorübergehend nicht zur Verfügung gestellt werden kann.), 6=Fehler (QU_FN_VIB_EPS_Fehler) (Funktion EPS-Lenkradvibration ist dauerhaft nicht verfügbar Dieser Zustand stellt sich dann ein, wenn die Funktion aufgrund eines EPS-internen Fehlers oder einer Degradation in dem aktuellen Klemme15-Zyklus nicht mehr zur Verfügung gestellt werden kann.), 15=Signal_unbefuellt (QU_FN_VIB_EPS_Signal_unbefuellt) (Sendefunktion nicht in Betrieb)  # Qualifier_Funktion_Vibration_EPS / Qualifier_function_vibration_EPS
  compu method QU_AVL_STMOM_DV_ACT: 8=Initialisierung (QU_AVL_STMOM_DV_ACT_Initialisierung) (Tritt während der Initialisierungsphase auf (Vorbefüllung). Nutzsignal wird permanent mit Nutzwert 0 befüllt.), 1=Signalwert ist gültig und abgesichert und plausibilisiert (QU_AVL_STMOM_DV_ACT_Signalwert_ist_gueltig_und_abgesichert_und_plausibilisiert) (The TSU works properly and the two torque signals are close enough to be plausible), 14=Signalwert ist ungültig, Zustand/Status temporär (QU_AVL_STMOM_DV_ACT_Signalwert_ist_ungueltig_Zustand_Status_temporaer) (Das zugehörige Nutzsignal wird permanent mit der Ungültigkeitskennung befüllt. The communication with the TSU or the TSU itself is wrong or because of some other reason the TSU signals are not good Wird in der L6 nicht verwendet), 6=Signalwert ist ungültig (QU_AVL_STMOM_DV_ACT_Signalwert_ist_ungueltig) (Wird in der L6 verwendet für die Ungültigkeitskennung des Signalwert Das zugehörige Nutzsignal wird permanent mit der Ungültigkeitskennung befüllt.), 15=Signal ungültig (QU_AVL_STMOM_DV_ACT_Signal_ungueltig) (Wird funktional nicht versendet)  # Qualifier_Ist_Lenkmoment_Fahrer_Stellglied / Qualifier_actual-value_steering-moment_driver_actuator
  compu method FACT_MO_STE_SO_DXP: phys=raw*0.02 for raw 0..250, 253=Funktionsschnittstelle_ist_nicht_verfuegbar (FACT_MO_STE_SO_DXP_Funktionsschnittstelle_ist_nicht_verfuegbar) (Sendefunktion in Betrieb, Werte nicht verfügbar), 254=Funktion_meldet_Fehler (FACT_MO_STE_SO_DXP_Funktion_meldet_Fehler) (Sendefunktion in Betrieb, meldet Fehler), 255=Signal_unbefuellt (FACT_MO_STE_SO_DXP_Signal_unbefuellt) (Sendefunktion nicht in Betrieb)  # Faktor_Modifikation_Lenkung_Servo_Fahrerlebnis / factor_modification_steering_servo_driving-experience
  compu method CTR_BS_PRTNT: 0=Keine Kommunikation (CTR_BS_PRTNT_Keine_Kommunikation), 1=Kom_Parken_BN_niO (CTR_BS_PRTNT_Kom_Parken_BN_niO), 2=Kom_Parken_BN_iO (CTR_BS_PRTNT_Kom_Parken_BN_iO), 3=Kom_Standfunktionen_Kunde_nicht_im_FZG (CTR_BS_PRTNT_Kom_Standfunktionen_Kunde_nicht_im_FZG), 4=reserviert (CTR_BS_PRTNT_reserviert), 5=Kom_Wohnen (CTR_BS_PRTNT_Kom_Wohnen), 6=reserviert (CTR_BS_PRTNT_reserviert_2), 7=Kom_Pruefen_Analyse_Diagnose (CTR_BS_PRTNT_Kom_Pruefen_Analyse_Diagnose), 8=Kom_Fahrbereitschaft_herstellen (CTR_BS_PRTNT_Kom_Fahrbereitschaft_herstellen), 9=reserviert (CTR_BS_PRTNT_reserviert_3), 10=Kom_Fahren (CTR_BS_PRTNT_Kom_Fahren), 11=reserviert (CTR_BS_PRTNT_reserviert_4), 12=Kom_Fahrbereitschaft_beenden (CTR_BS_PRTNT_Kom_Fahrbereitschaft_beenden), 13=reserviert (CTR_BS_PRTNT_reserviert_5) (Hinweis: Reserviert für funktionale Kennung Signal-Tag.), 14=reserviert (CTR_BS_PRTNT_reserviert_6) (Hinweis: Reserviert für funktionale Kennung Signal-Tag.), 15=Signal_unbefuellt (CTR_BS_PRTNT_Signal_unbefuellt)  # Steuerung_Basis_Teilnetze / control_base_partial-networks
  compu method ST_ENERG_FZM: 0=ENSTATE_GOOD (ST_ENERG_FZM_ENSTATE_GOOD), 1=ENSTATE_OK (ST_ENERG_FZM_ENSTATE_OK), 2=ENSTATE_SHORTAGE (ST_ENERG_FZM_ENSTATE_SHORTAGE), 3=ENSTATE_SEVERE_SHORTAGE (ST_ENERG_FZM_ENSTATE_SEVERE_SHORTAGE), 15=Signal ungültig (ST_ENERG_FZM_Signal_ungueltig)  # Status_Energie_FZM / status_Energy_FZM
  compu method CTR_ERRM_BN_U: mask 33: 0=Keine Unterspannung Normalbetrieb (CTR_ERRM_BN_U_Keine_Unterspannung_Normalbetrieb) (Unterspannungsschwelle für Normalbetrieb nicht erreicht.), mask 33: 1=Unterspannung Normalbetrieb (CTR_ERRM_BN_U_Unterspannung_Normalbetrieb) (Unterspannungsschwelle für Normalbetrieb unterschritten.), mask 34: 0=Keine Unterspannung MSA-Start (CTR_ERRM_BN_U_Keine_Unterspannung_MSA_Start) (Unterspannungsschwelle für MSA-Start Festigkeit nicht erreicht.), mask 34: 2=Unterspannung MSA-Start (CTR_ERRM_BN_U_Unterspannung_MSA_Start) (Unterspannungsschwelle für MSA-Start Festigkeit unterschritten.), mask 36: 0=Keine Überspannung (CTR_ERRM_BN_U_Keine_Ueberspannung) (Überspannungsschwelle nicht erreicht.), mask 36: 4=Überspannung (CTR_ERRM_BN_U_Ueberspannung) (Überspannungsschwelle überschritten.), mask 63: 61=Funktionsschnittstelle_ist_nicht_verfuegbar (CTR_ERRM_BN_U_Funktionsschnittstelle_ist_nicht_verfuegbar) (Sendefunktion in Betrieb, Werte nicht verfügbar), mask 63: 62=Funktion_meldet_Fehler (CTR_ERRM_BN_U_Funktion_meldet_Fehler) (Sendefunktion in Betrieb, meldet Fehler), mask 63: 63=Signal_unbefuellt (CTR_ERRM_BN_U_Signal_unbefuellt) (Sendefunktion nicht in Betrieb)  # Steuerung_Fehlerspeicher_Bordnetz_Spannung / control_error-memory_Bordnetz_voltage
  compu method TAR_STMOM_DV_ACT: phys=raw*0.006-12; unit Nm  # Soll_Lenkmoment_Fahrer_Stellglied / target_steering-moment_driver_actuator
  compu method ENERG_AVAI_ARS: phys=raw for raw 0..100, 253=Funktionsschnittstelle_ist_nicht_verfuegbar (ENERG_AVAI_ARS_Funktionsschnittstelle_ist_nicht_verfuegbar) (Sendefunktion in Betrieb, Werte nicht verfügbar), 254=Funktion_meldet_Fehler (ENERG_AVAI_ARS_Funktion_meldet_Fehler) (Nutzsignal kann nicht berechnet werden), 255=Signal_unbefuellt (ENERG_AVAI_ARS_Signal_unbefuellt) (Sendefunktion nicht in Betrieb); unit %  # Energie_Verfügbarkeit_ARS / Energy_availibility_ARS
  compu method UN_PO_EPS: 0=Ritzelschnittstelle (UN_PO_EPS_Ritzelschnittstelle) (Die Position wird in Grad übertragen.), 1=Zahnstangenhubschnittstelle (UN_PO_EPS_Zahnstangenhubschnittstelle) (Die Position wird in Millimeter übertragen (Einheit=0.2mm).), 3=Signal ungültig (UN_PO_EPS_Signal_ungueltig)  # Einheit_Position_EPS / unit-of-measurement_position_EPS
  compu method ST_CENG_DRV: 0=Motor steht (ST_CENG_DRV_Motor_steht) (Motorstillstand anhand interner Bedingungen erkannt (z.B. Kurbelwellendrehzahl < Schwelle für bestimmte Zeit)), 1=Motor startet (ST_CENG_DRV_Motor_startet) (Startroutinen aktiv, Motor in Vorsteuerung), 2=Motor läuft (ST_CENG_DRV_Motor_laeuft) (Motor im geregelten Betrieb, Motorlauf ohne Startsystemeingriff gewährleistet), 3=Motor im Auslauf (ST_CENG_DRV_Motor_im_Auslauf) (Anforderung zum Motorabstellen (z.B. über MSA-Anforderung, Anforderung Fahrbereitschaft beenden, etc.)), 13=Funktionsschnittstelle_ist_nicht_verfuegbar (ST_CENG_DRV_Funktionsschnittstelle_ist_nicht_verfuegbar) (DME in der Initialisierung (z.B. nach Reset)), 14=Reserviert (ST_CENG_DRV_Reserviert) (Hinweis: Reserviert für funktionale Kennung Signal-Tag.), 15=Signal_unbefuellt (ST_CENG_DRV_Signal_unbefuellt) (Sendefunktion nicht in Betrieb)  # Status_Verbrennungsmotor_Antrieb / status_combustion-engine_drive
  compu method ACLNY_COG_ERR_AMP: phys=raw*0.005; unit m/s²  # Querbeschleunigung_Schwerpunkt_Fehler_Amplitude / lateral-acceleration_centre-of-gravity_error_amplidue
  compu method QU_SUM_AVL_I_DRDY_SFY: 1=Wert_gueltig_abgesichert (QU_SUM_AVL_I_DRDY_SFY_Wert_gueltig_abgesichert) (Stromwert gueltig und abgesichert), 3=Wert_gueltig_eingeschraenkt (QU_SUM_AVL_I_DRDY_SFY_Wert_gueltig_eingeschraenkt) (Stromwert nicht abgesichert), 6=Wert_nicht_verfuegbar_Fehler (QU_SUM_AVL_I_DRDY_SFY_Wert_nicht_verfuegbar_Fehler) (Sendefunktion in Betrieb, Werte nicht verfügbar), 14=Wert_nicht_verfuegbar (QU_SUM_AVL_I_DRDY_SFY_Wert_nicht_verfuegbar) (Sendefunktion in Betrieb, meldet Fehler), 15=Signal_unbefuellt (QU_SUM_AVL_I_DRDY_SFY_Signal_unbefuellt) (Sendefunktion nicht in Betrieb)  # Qualifier_Summe_Ist_Strom_Fahrdynamik_Sicherheit / Qualifier_sum_actual-value_current_driving-dynamics_safety
  compu method TOT_STR_EPS: phys=raw*0.012213  # Gesamt_Lenkübersetzung_EPS / total_steering-ratio_EPS
  compu method NO_VECH_3: identical  # Nummer_Fahrgestell_3 / number_vehicle-chassis_3
  compu method QU_ST_CON_VEH: 2=Signalwert gültig (QU_ST_CON_VEH_Signalwert_gueltig), 3=Signalwert eingeschränkt gültig (QU_ST_CON_VEH_Signalwert_eingeschraenkt_gueltig), 6=Reserviert für die nicht umgesetzte Kennung "Fehler" (QU_ST_CON_VEH_Reserviert_fuer_die_nicht_umgesetzte_Kennung_Fehler_) (Codierung wird nicht befüllt), 14=Wert_nicht_verfuegbar (QU_ST_CON_VEH_Wert_nicht_verfuegbar) (Siehe Signalbeschreibung), 15=Signal unbefüllt (QU_ST_CON_VEH_Signal_unbefuellt)  # Qualifier_Status_Zustand_Fahrzeug / Qualifier_status_condition_vehicle
  compu method QU_FN_ENSU_SFY: mask 240: 144=Sichere_Energieversorgung_aktiv (QU_FN_ENSU_SFY_Sichere_Energieversorgung_aktiv) (Zustand der sicheren Energieversorgung: Die sichere Energieversorgung ist aktiv, es liegt kein Fehler oder Vorwarnung vor.), mask 240: 176=Sichere_Energieversorgung_aktiv_Vorwarnung (QU_FN_ENSU_SFY_Sichere_Energieversorgung_aktiv_Vorwarnung) (Zustand der sicheren Energieversorgung: Die sichere Energieversorgung ist aktiv, es liegt eine Vorwarnung vor. Der Zustand kann wieder in _aktiv zurückwechseln oder in _nicht_verfügbar_Fehler wechseln.), mask 15: 0=Sichere_Energieversorgung_Klasse_0 (QU_FN_ENSU_SFY_Sichere_Energieversorgung_Klasse_0) (Zusätzlich zum Zustand die Klasse der sicheren Energieversorgung: Es ist keine spezielle Ausprägung der sicheren Energieversorgung angefordert und umgesetzt. Die Klassen sind weder pauschal disjunkt noch pauschal überschneidend oder pauschal inkludierend.), mask 15: 1=Sichere_Energieversorgung_Klasse_1 (QU_FN_ENSU_SFY_Sichere_Energieversorgung_Klasse_1) (Zusätzlich zum Zustand die Klasse der sicheren Energieversorgung: Es ist eine spezielle Ausprägung der sicheren Energieversorgung angefordert und umgesetzt. Die Klassen sind weder pauschal disjunkt noch pauschal überschneidend oder pauschal inkludierend.), mask 15: 2=Sichere_Energieversorgung_Klasse_2 (QU_FN_ENSU_SFY_Sichere_Energieversorgung_Klasse_2) (Zusätzlich zum Zustand die Klasse der sicheren Energieversorgung: Es ist eine spezielle Ausprägung der sicheren Energieversorgung angefordert und umgesetzt. Die Klassen sind weder pauschal disjunkt noch pauschal überschneidend oder pauschal inkludierend.), mask 15: 3=Sichere_Energieversorgung_Klasse_3 (QU_FN_ENSU_SFY_Sichere_Energieversorgung_Klasse_3) (Zusätzlich zum Zustand die Klasse der sicheren Energieversorgung: Es ist eine spezielle Ausprägung der sicheren Energieversorgung angefordert und umgesetzt. Die Klassen sind weder pauschal disjunkt noch pauschal überschneidend oder pauschal inkludierend.), mask 15: 4=Sichere_Energieversorgung_Klasse_4 (QU_FN_ENSU_SFY_Sichere_Energieversorgung_Klasse_4) (Zusätzlich zum Zustand die Klasse der sicheren Energieversorgung: Es ist eine spezielle Ausprägung der sicheren Energieversorgung angefordert und umgesetzt. Die Klassen sind weder pauschal disjunkt noch pauschal überschneidend oder pauschal inkludierend.), mask 15: 5=Sichere_Energieversorgung_Klasse_5 (QU_FN_ENSU_SFY_Sichere_Energieversorgung_Klasse_5) (Zusätzlich zum Zustand die Klasse der sicheren Energieversorgung: Es ist eine spezielle Ausprägung der sicheren Energieversorgung angefordert und umgesetzt. Die Klassen sind weder pauschal disjunkt noch pauschal überschneidend oder pauschal inkludierend.), mask 240: 96=Sichere_Energieversorgung_nicht_verfuegbar_Fehler (QU_FN_ENSU_SFY_Sichere_Energieversorgung_nicht_verfuegbar_Fehler) (Zustand der sicheren Energieversorgung: Die sichere Energieversorgung ist nicht verfügbar, weil ein Fehler vorliegt.), mask 255: 254=Funktion_meldet_Fehler (QU_FN_ENSU_SFY_Funktion_meldet_Fehler) (Sendefunktion in Betrieb, meldet Fehler), mask 255: 255=Signal_unbefuellt (QU_FN_ENSU_SFY_Signal_unbefuellt) (Sendefunktion nicht in Betrieb)  # Qualifier_Funktion_Energieversorgung_Sicherheit / Qualifier_function_energy-supply_safety
  compu method NO_VECH_2: identical  # Nummer_Fahrgestell_2 / number_vehicle-chassis_2
  compu method SSS_IDENT: 0=ZGW VIN (SSS_IDENT_ZGW_VIN), 255=Signal ungültig (SSS_IDENT_Signal_ungueltig)  # SSS_Identifikation / SSS_identification
  compu method QU_AVL_RPM_WHL: 8=Initialisierung (QU_AVL_RPM_WHL_Initialisierung) (Wird gelegt solange aufgrund des Aufstartvorgangs (und der dazu gehörenden Sensorprüfung) für den zugehörigen Raddrehzahlsensor kein Wert ermittelt werden kann. Nutzsignal wird permanent mit der Ungültigkeitskennung befüllt.), 1=Signalwert ist gültig und abgesichert und plausibilisiert (QU_AVL_RPM_WHL_Signalwert_ist_gueltig_und_abgesichert_und_plausibilisiert) (Ist der zugehörige Raddrehzahlsensor i.O. geprüft, so wird der Qualifier auf diesem Zustand gesetzt.), 9=Reserved (QU_AVL_RPM_WHL_Reserved), 2=Reserved (QU_AVL_RPM_WHL_Reserved_2), 10=Reserved (QU_AVL_RPM_WHL_Reserved_3), 3=Reserved (QU_AVL_RPM_WHL_Reserved_4), 11=Signalqualität bzw. Überwachung eingeschränkt, Zustand/Status temporär (QU_AVL_RPM_WHL_Signalqualitaet_bzw_Ueberwachung_eingeschraenkt_Zustand_Status_temporaer) (Implementierungsinfo des DSC-8 Bosch-Systems: Wird gelegt, wenn bei gesetzter Rollenerkennung des ICM-Q/L die Anfahrüberwachung des DSC zuschlägt.), 4=Ersatzwert ist im Nutzsignal gesetzt (QU_AVL_RPM_WHL_Ersatzwert_ist_im_Nutzsignal_gesetzt) (Wird gelegt, solange keine gültige Drehrichtung erkannt wurde. (z.B. Stillstand) Kann nur bei Sensoren mit Drehrichtungserkennung gesetzt werden.), 12=Ersatzwert ist im Nutzsignal gesetzt Zustand / Status Temporär (QU_AVL_RPM_WHL_Ersatzwert_ist_im_Nutzsignal_gesetzt_Zustand_Status_Temporaer) (Nutzsignal liefert das aktuelle Rohsignal mit eingeschränkter Qualität (es kann zu Abweichungen kommen). Der Übergang zum "Signalwert ist gültig" (0001) erfolgt über eine Einschwingphase (ca. 300ms) Kann auftreten während bzw. nach Unterspannung am Raddrehzahlsensor (DSC) In der PL6 wird dieser Code nicht verwendet.), 6=Wert_nicht_verfuegbar_Fehler_elektrisch (QU_AVL_RPM_WHL_Wert_nicht_verfuegbar_Fehler_elektrisch) (Im Fehlerfall wird abhängig von der Ursache entweder 0110 (Schwerpunkt: elektrische Fehler mit Reparaturbedarf) oder 1110 (Schwerpunkt: Plausibilitätsfehler ohne Reparaturbedarf) gesendet. Die Umsetzung ist produktlinienspezifisch unterschiedlich. Nutzsignal wird permanent mit der Ungültigkeitskennung befüllt.), 14=Wert_nicht_verfuegbar_Plausibilitaetsfehler (QU_AVL_RPM_WHL_Wert_nicht_verfuegbar_Plausibilitaetsfehler) (Im Fehlerfall wird abhängig von der Ursache entweder 0110 (Schwerpunkt: elektrische Fehler mit Reparaturbedarf) oder 1110 (Schwerpunkt: Plausibilitätsfehler ohne Reparaturbedarf) gesendet. Die Umsetzung ist produktlinienspezifisch unterschiedlich. Nutzsignal wird permanent mit der Ungültigkeitskennung befüllt.), 7=Reserved (QU_AVL_RPM_WHL_Reserved_5), 15=Signal ungültig (QU_AVL_RPM_WHL_Signal_ungueltig) (Kann nur vom Gateway gesetzt werden)  # Qualifier_Ist_Drehzahl_Rad / Qualifier_actual-value_RPM_wheel
  compu method FACT_ASS_STMOM_FTAX: phys=raw/256+1  # Faktor_Unterstützung_Lenkmoment_Vorderachse / factor_assistance_steering-moment_front-axle
  compu method QU_AVL_PINA_EPS: 8=Initialisierung (QU_AVL_PINA_EPS_Initialisierung) (Nach jedem Reset und Aufstarten des EPS-Steuergeräts. Nutzsignal wird permanent mit Nutzwert 0 befüllt.), 1=Signalwert ist gültig und abgesichert und plausibilisiert (QU_AVL_PINA_EPS_Signalwert_ist_gueltig_und_abgesichert_und_plausibilisiert) (Position ist aufgesetzt und offsetkompensiert. Sensorwert gültig und elektrische Überwachung i.O. und EPS intern plausibilisiert), 2=Signalwert ist gültig (QU_AVL_PINA_EPS_Signalwert_ist_gueltig) (Position ist aufgesetzt und offsetkompensiert Sensorwert gültig und elektrische Überwachung i.O.), 4=Ersatzwert ist im Nutzsignal gesetzt (QU_AVL_PINA_EPS_Ersatzwert_ist_im_Nutzsignal_gesetzt) (Signalwert rein aus dem Sensor, d.h. die Position ist aufintegriert (Relativ) Sensorwert gültig und elektrische Überwachung i.O. FUSI: keine Verwendung für sicherheitsrelevante Funktionen.), 9=Signalwert ist gültig, Zustand/Status temporär (mittlere Signalqualität) (QU_AVL_PINA_EPS_Signalwert_ist_gueltig_Zustand_Status_temporaer_mittlere_Signalqualitaet_) (Wird erst ab SP2015 unterstützt: Position ist aufgesetzt. Die minimale Signaltoleranz ist allerdings noch nicht erreicht. Sensorwert gültig und elektrische Überwachung i.O.), 10=Signalwert ist gültig, Zustand/Status temporär (geringe Signalqualität) (QU_AVL_PINA_EPS_Signalwert_ist_gueltig_Zustand_Status_temporaer_geringe_Signalqualitaet_) (Position ist aufgesetzt, es liegt aber noch eine Signaltoleranz bis etwa 30° Lenkradwinkel vor. Sensorwert gültig und elektrische Überwachung i.O. Wird erst ab SP2013 (außer F15-F16, 444) unterstützt.), 12=Abgleichwert ist im Nutzsignal gesetzt, Zustand/Status temporär (QU_AVL_PINA_EPS_Abgleichwert_ist_im_Nutzsignal_gesetzt_Zustand_Status_temporaer) (Nicht vertrauenswürdige aufgesetzte und offsetkompensierte Position, die in diesem Zustand korrigiert wird (durch Aufsetzalgorithmus im ICM). Dieser Zustand bleibt mindestens 50ms bestehen. FUSI: keine Verwendung für sicherheitsrelevante Funktionen.), 14=Signalwert ist ungültig, Zustand/Status temporär (QU_AVL_PINA_EPS_Signalwert_ist_ungueltig_Zustand_Status_temporaer) (Das zugehörige Nutzsignal wird permanent mit der Ungültigkeitskennung befüllt. Wird gesetzt bei internen EPS Fehler (Sensor Fehler, Interner Kommunikationsfehler,...) Dieser Zustand bleibt mindestens 20ms bestehen.), 15=Signal ungültig (QU_AVL_PINA_EPS_Signal_ungueltig)  # Qualifier_Ist_Ritzelwinkel_EPS / Qualifier_actual-value_pinion-angle_EPS
  compu method QU_V_VEH_COG: 8=Initialisierung (QU_V_VEH_COG_Initialisierung) (Tritt während der Initialisierungsphase auf bis Ist-Wert verfügbar (Vorbefüllung). Nutzsignal wird permanent mit Nutzwert 0 befüllt.), 1=Signalwert ist gültig und abgesichert und plausibilisiert (QU_V_VEH_COG_Signalwert_ist_gueltig_und_abgesichert_und_plausibilisiert), 9=Reserved (QU_V_VEH_COG_Reserved), 2=Reserved (QU_V_VEH_COG_Reserved_2), 10=Signalwert ist gültig, Zustand/Status temporär (QU_V_VEH_COG_Signalwert_ist_gueltig_Zustand_Status_temporaer) (FUSI: Eine für die Berechnung der Geschwindigkeit notwendige Größe fehlt (z.B. Längsbeschleunigung, Raddrehzahl,...). Signalqualität bei instabiler Fahrt eingeschränkt. (Für sicherheitsrelevante Funktionen Anwendbarkeit des Signals prüfen.)), 3=Reserved (QU_V_VEH_COG_Reserved_3), 11=Signalqualität bzw. Überwachung eingeschränkt, Zustand/Status temporär (QU_V_VEH_COG_Signalqualitaet_bzw_Ueberwachung_eingeschraenkt_Zustand_Status_temporaer) (FUSI: Mehr als eine für die Berechnung der Geschwindigkeit notwendige Größe fehlt (z.B. Längsbeschleunigung, Raddrehzahl,...). Signalqualität bei instabiler Fahrt eingeschränkt. (Für sicherheitsrelevante Funktionen Anwendbarkeit des Signals prüfen.)), 4=Reserved (QU_V_VEH_COG_Reserved_4), 12=Reserved (QU_V_VEH_COG_Reserved_5), 6=Reserved (QU_V_VEH_COG_Reserved_6), 14=Signalwert ist ungültig, Zustand/Status temporär (QU_V_VEH_COG_Signalwert_ist_ungueltig_Zustand_Status_temporaer) (Keine Raddrehzahlen verfügbar, Berechnung der Geschwindigkeit nicht möglich. Das zugehörige Nutzsignal wird permanent mit der Ungültigkeitskennung befüllt.), 7=Reserved (QU_V_VEH_COG_Reserved_7), 15=Signal ungültig (QU_V_VEH_COG_Signal_ungueltig) (Kann nur vom Gateway gesetzt werden)  # Qualifier_Geschwindigkeit_Fahrzeug_Schwerpunkt / Qualifier_speed_vehicle_centre-of-gravity
  compu method CTR_DEAC_EPS_FNS: mask 15: 0=Keine_Deaktivierung_EPS_Funktionen (CTR_DEAC_EPS_FNS_Keine_Deaktivierung_EPS_Funktionen) (Es besteht keine Anforderung zur Deaktivierung von Funktionen auf der EPS.), mask 9: 1=Deaktivierung_EPS_Funktionen_ Funktionsgruppe_1 (CTR_DEAC_EPS_FNS_Deaktivierung_EPS_Funktionen_Funktionsgruppe_1) (Anforderung zur Deaktivierung einer spezifizierten Funktionsgruppe 1 auf der EPS. Die detaillierte Spezifikation der Funktionsgruppe 1 erfolgt im Entwicklungsprozess mit den Lieferanten.), mask 10: 2=Deaktivierung_EPS_Funktionen_ Funktionsgruppe_2 (CTR_DEAC_EPS_FNS_Deaktivierung_EPS_Funktionen_Funktionsgruppe_2) (Anforderung zur Deaktivierung einer spezifizierten Funktionsgruppe 2 auf der EPS. Die detaillierte Spezifikation der Funktionsgruppe 2 erfolgt im Entwicklungsprozess mit den Lieferanten.), mask 15: 13=Funktionsschnittstelle_ist_nicht_verfuegbar (CTR_DEAC_EPS_FNS_Funktionsschnittstelle_ist_nicht_verfuegbar) (Sendefunktion in Betrieb, Werte nicht verfügbar), mask 15: 14=Funktion_meldet_Fehler (CTR_DEAC_EPS_FNS_Funktion_meldet_Fehler) (Sendefunktion in Betrieb, meldet Fehler), mask 15: 15=Signal_unbefuellt (CTR_DEAC_EPS_FNS_Signal_unbefuellt) (Wird nicht aktiv gesetzt)  # Steuerung_Deaktivierung_EPS_Funktionen / control_deactivation_EPS_functions
  compu method QU_DGR_AISP_ENERG: 0=Degradationsstufe 0 (QU_DGR_AISP_ENERG_Degradationsstufe_0) (Keine Anlaufverzögerung oder Anlaufunterbrechung des Kompressors Incl. Default- und Aufstartwert), 1=Degradationsstufe 1 (QU_DGR_AISP_ENERG_Degradationsstufe_1) (Geringe Anlaufverzögerung (Geringe Aufweitung der Anregelschwellen, keine Anlaufsperre oder -unterbrechung)), 2=Degradationsstufe 2 (QU_DGR_AISP_ENERG_Degradationsstufe_2) (Mittlere Anlaufverzögerung (Mittlere Aufweitung der Anregelschwellen, keine Anlaufsperre oder -unterbrechung)), 3=Degradationsstufe 3 (QU_DGR_AISP_ENERG_Degradationsstufe_3) (Maximale Anlaufverzögerung (Maximale Aufweitung der Anregelschwellen, keine Anlaufsperre oder -unterbrechung)), 4=Degradationsstufe 4 (QU_DGR_AISP_ENERG_Degradationsstufe_4) (Anlaufsperre für definierte Zeitspanne oder Anlaufunterbrechung), 15=Signal ungültig (QU_DGR_AISP_ENERG_Signal_ungueltig)  # Qualifier_Degradation_Luftfeder_Energie / Qualifier_degradation_air-spring_Energy
  compu method TRGG_ENGTORQ_EPS: phys=raw*0.01-10 for raw 0..2000, 4093=Funktionsschnittstelle_ist_nicht_verfuegbar (TRGG_ENGTORQ_EPS_Funktionsschnittstelle_ist_nicht_verfuegbar) (Sendefunktion in Betrieb, Werte nicht verfügbar), 4094=Funktion_meldet_Fehler (TRGG_ENGTORQ_EPS_Funktion_meldet_Fehler) (Sendefunktion in Betrieb, meldet Fehler), 4095=Signal_unbefuellt (TRGG_ENGTORQ_EPS_Signal_unbefuellt) (Sendefunktion nicht in Betrieb); unit Nm  # Ansteuerung_Motormoment_EPS / triggering_engine-torque_EPS
  compu method IDX_TORQ_SEN: 0=Initialisierung (IDX_TORQ_SEN_Initialisierung), 1=Keine Index Flanke (IDX_TORQ_SEN_Keine_Index_Flanke) (FUSI: Verwendung im Funktionsrahmen zu prüfen.), 2=Index Flanke (IDX_TORQ_SEN_Index_Flanke) (Gilt für steigende und fallende Flanken FUSI: Verwendung im Funktionsrahmen zu prüfen.), 3=Signal ungültig (IDX_TORQ_SEN_Signal_ungueltig)  # Index_Drehmoment_Sensor / index_torque_sensor
  compu method CTR_WARN_DIR_VIB_EPS: 0=Keine_Richtung (CTR_WARN_DIR_VIB_EPS_Keine_Richtung) (Ungerichteter Impuls Diese Codierung wird auch versendet, wenn keine haptische Warnung erfolgt.), 1=Richtung_links (CTR_WARN_DIR_VIB_EPS_Richtung_links) (Impuls Richtung links), 2=Richtung_rechts (CTR_WARN_DIR_VIB_EPS_Richtung_rechts) (Impuls Richtung rechts), 3=Signal_unbefuellt (CTR_WARN_DIR_VIB_EPS_Signal_unbefuellt) (Sendefunktion nicht in Betrieb)  # Steuerung_Warnung_Richtung_Vibration_EPS / control_warning_direction_vibration_EPS
  compu method COU_BS_RESP: phys=raw  # Zähler_Basis_Response / counter_base_response
  compu method V_VEH_COG: phys=raw/64; unit km/h  # Geschwindigkeit_Fahrzeug_Schwerpunkt / speed_vehicle_centre-of-gravity
  compu method SSV_IDENT: 0=REF_BAC4CAN_VIN (SSV_IDENT_REF_BAC4CAN_VIN), 1=DME1 VIN (SSV_IDENT_DME1_VIN), 2=DME2 VIN (SSV_IDENT_DME2_VIN), 3=RSE VIN (SSV_IDENT_RSE_VIN) (Vorhalt), 4=KAFAS, VIN (SSV_IDENT_KAFAS_VIN) (Vorhalt), 5=DSC_Modul VIN (SSV_IDENT_DSC_Modul_VIN) (Vorhalt), 6=VDP VIN (SSV_IDENT_VDP_VIN) (Vorhalt), 7=SAS VIN (SSV_IDENT_SAS_VIN) (Vorhalt), 8=NiVi VIN (SSV_IDENT_NiVi_VIN) (Vorhalt), 9=HU_VIN (SSV_IDENT_HU_VIN) (Alle HUs), 10=EPS_VIN (SSV_IDENT_EPS_VIN) (Vorhalt), 11=REF_BAC4_FR_VIN (SSV_IDENT_REF_BAC4_FR_VIN), 19=MRR_VIN (SSV_IDENT_MRR_VIN), 20=ATM2_VIN (SSV_IDENT_ATM2_VIN), 21=Kombi_VIN (SSV_IDENT_Kombi_VIN), 255=Signal ungültig (SSV_IDENT_Signal_ungueltig)  # SSV_Identifikation / SSV_identification
  compu method ST_ENERG_SUPY: mask 255: 0=Kein Spannungseinbruch (ST_ENERG_SUPY_Kein_Spannungseinbruch), mask 129: 1=Startspannungseinbruch auf Versorgungszweig 1 (ST_ENERG_SUPY_Startspannungseinbruch_auf_Versorgungszweig_1) (Auf Versorgungszweig 1 ist bei MSA2.3 der Starter. Bei MSA2.5 kann beim Kaltstart Versorgungszweig 1 und Versorgungszweig 2 über ein Relais verbunden werden.), mask 130: 2=Startspannungseinbruch auf Versorgungszweig 2 (ST_ENERG_SUPY_Startspannungseinbruch_auf_Versorgungszweig_2) (Auf Versorgungszweig 2 ist bei MSA2.5 der Starter. Bei den Hybriden ist die Zustarteinrichtung ebenfalls auf Versorgungszweig 2.), mask 132: 4=Spannungsversorgung 48 Volt (ST_ENERG_SUPY_Spannungsversorgung_48_Volt), mask 255: 253=Reserviert (ST_ENERG_SUPY_Reserviert) (Hinweis: Reserviert für funktionale Kennung Signal-Tag), mask 255: 254=Reserviert (ST_ENERG_SUPY_Reserviert_2) (Hinweis: Reserviert für funktionale Kennung Signal-Tag), mask 255: 255=Signal_unbefuellt (ST_ENERG_SUPY_Signal_unbefuellt) (Sendefunktion nicht in Betrieb)  # Status_Energie_Versorgung / status_Energy_supply
  compu method ST_V_VEH_NSS: 12=Fahrzeug im stillstandsnahen Bereich (ST_V_VEH_NSS_Fahrzeug_im_stillstandsnahen_Bereich) (Dieser Zustand wird eingenommen wenn sowohl die Fahrzeuggeschwindigkeit (V_VEH_COG) als auch die 4 Einzelradgeschwindigkeit 10 kmh unterschreiten.), 13=Fahrzeug nicht im stillstandsnahen Bereich (ST_V_VEH_NSS_Fahrzeug_nicht_im_stillstandsnahen_Bereich) (Dieser Zustand wird eingenommen wenn das Fahrzeug sich nicht sicher im stillstandsnahen Bereich befindet. Mindestens eine der 5 Geschwindigkeiten, Fahrzeuggeschwindigkeit (V_VEH_COG) oder Einzelradgeschwindigkeiten, überschreitet die Schwelle von 10 kmh. Das heißt das Fahrzeug kann eine beliebige Geschwindigkeit aufweisen, auch unter 10 kmh. Es bedeutet nicht zwangsläufig dass das Fahrzeug schneller als 10kmh fährt.), 15=Signal ungültig (ST_V_VEH_NSS_Signal_ungueltig) (Dieser Zustand wird beim Aufstarten des Steuergeräts gesetzt bis ein gültiger Wert bereit gestellt werden kann. Während des laufenden Betriebs kann dieser Zustand eingenommen werden, wenn die Raddrehzahlen nicht zur Verfügung stehen.)  # Status_Geschwindigkeit_Fahrzeug_Stillstandsnah / status_speed_vehicle_near-standstill
  compu method QU_FN_EST: 128=Initialisierung (QU_FN_EST_Initialisierung) (EPS Initialisierungszustand), 160=Funktion verfügbar - Aktiv, 12V EPS (QU_FN_EST_Funktion_verfuegbar_Aktiv_12V_EPS) (12V EPS / EPS im Normalzustand), 164=Funktion verfügbar - Aktiv, 12V EAS (QU_FN_EST_Funktion_verfuegbar_Aktiv_12V_EAS) (12V EAS / EPS im Normalzustand.), 168=Funktion verfügbar - Aktiv, 24V EAS (QU_FN_EST_Funktion_verfuegbar_Aktiv_24V_EAS) (24V EAS / EPS im Normalzustand), 162=Funktion verfügbar - Aktiv, Notfallfunktion Umwelteinflüsse - Aktiv (QU_FN_EST_Funktion_verfuegbar_Aktiv_Notfallfunktion_Umwelteinfluesse_Aktiv) (Diese Codierung wird ab SP2015 verwendet: Notfallfunktion zur Reduzierung Liegenbleiber aufgrund von Umwelteinflüssen aktiv), 49=Funktion in Rückfallebene (QU_FN_EST_Funktion_in_Rueckfallebene) (24V EAS / Kl.30 Abfall von 24V -> 12V Ritzelwinkelschnittstelle soll nicht zur Verfügung stehen => Service nicht verfügbar, Fahrdynamikschnittstelle verfügbar Heilung im aktuellen Zündungszyklus nicht möglich), 51=Funktion in Rückfallebene, Notfallfunktion Umwelteinflüsse- Aktiv (QU_FN_EST_Funktion_in_Rueckfallebene_Notfallfunktion_Umwelteinfluesse_Aktiv) (Diese Codierung wird ab SP2015 verwendet: 24V EAS / Kl.30 Abfall von 24V -> 12V Zusätzlich ist die Notfallfunktion zur Reduzierung Liegenbleiber aufgrund von Umwelteinflüssen aktiv. Ritzelwinkelschnittstelle soll nicht zur Verfügung stehen => Service nicht verfügbar, Fahrdynamikschnittstelle verfügbar Heilung im aktuellen Zündungszyklus nicht möglich), 176=Funktion temporär in Rückfallebene (QU_FN_EST_Funktion_temporaer_in_Rueckfallebene) (Unterstützungslevel < Schwellwert (z.B. 70%) Heilung im aktuellen Zündungszyklus möglich), 178=Funktion temporär in Rückfallebene, Notfallfunktion Umwelteinflüsse- Aktiv (QU_FN_EST_Funktion_temporaer_in_Rueckfallebene_Notfallfunktion_Umwelteinfluesse_Aktiv) (Diese Codierung wird ab SP2015 verwendet: Unterstützungslevel < Schwellwert (z.B. 70%) Zusätzlich ist die Notfallfunktion zur Reduzierung Liegenbleiber aufgrund von Umwelteinflüssen aktiv. Heilung im aktuellen Zündungszyklus möglich), 96=Funktion nicht verfügbar - Fehler (QU_FN_EST_Funktion_nicht_verfuegbar_Fehler) (EPS Zustand = Fehler Heilung im aktuellen Zündungszyklus nicht möglich), 224=Funktion nicht verfügbar - ausgeschaltet (QU_FN_EST_Funktion_nicht_verfuegbar_ausgeschaltet) (Wird gesetzt zum Beispiel kurzfristig nach dem Zustand "Initialisierung", im KL.15N Nachlauf, im Werkmodus,...), 255=Signal ungültig (QU_FN_EST_Signal_ungueltig) (Wird Funktional nicht versendet.)  # Qualifier_Funktion_Elektrische-Lenkung / Qualifier_function_electrical-steering
  compu method AVL_PINA_IDX_ICM: phys=raw*0.0439453125-1439.956055  # Ist_Ritzelwinkel_Index_ICM / actual-value_pinion-angle_index_ICM
  compu method CTR_WARN_PTRN_VIB_EPS: 0=Keine_haptische_Warnung (CTR_WARN_PTRN_VIB_EPS_Keine_haptische_Warnung), 1=Muster_1 (CTR_WARN_PTRN_VIB_EPS_Muster_1), 2=Muster_2 (CTR_WARN_PTRN_VIB_EPS_Muster_2), 3=Muster_3 (CTR_WARN_PTRN_VIB_EPS_Muster_3), 4=Muster_4 (CTR_WARN_PTRN_VIB_EPS_Muster_4), 5=Muster_5 (CTR_WARN_PTRN_VIB_EPS_Muster_5), 6=Muster_6 (CTR_WARN_PTRN_VIB_EPS_Muster_6), 7=Muster_7 (CTR_WARN_PTRN_VIB_EPS_Muster_7), 8=Muster_8 (CTR_WARN_PTRN_VIB_EPS_Muster_8), 9=Muster_9 (CTR_WARN_PTRN_VIB_EPS_Muster_9), 10=Muster_10 (CTR_WARN_PTRN_VIB_EPS_Muster_10), 13=Funktionsschnittstelle_ist_nicht_verfuegbar (CTR_WARN_PTRN_VIB_EPS_Funktionsschnittstelle_ist_nicht_verfuegbar) (Sendefunktion in Betrieb, Werte nicht verfügbar), 14=Funktion_meldet_Fehler (CTR_WARN_PTRN_VIB_EPS_Funktion_meldet_Fehler) (Sendefunktion in Betrieb, meldet Fehler), 15=Signal_unbefuellt (CTR_WARN_PTRN_VIB_EPS_Signal_unbefuellt) (Sendefunktion nicht in Betrieb)  # Steuerung_Warnung_Muster_Vibration_EPS / control_warning_pattern_vibration_EPS
  compu method QU_TAR_QTA_STMOM_DV: 2=Sollwerte umsetzen (QU_TAR_QTA_STMOM_DV_Sollwerte_umsetzen) (Es wird ein Lenkmoment angefordert.), 7=Sollwerte nicht vorhanden (QU_TAR_QTA_STMOM_DV_Sollwerte_nicht_vorhanden) (Wird gesendet, wenn die Funktion auscodiert ist. Wird immer gesetzt wenn keine EPS verbaut ist.), 14=Sollwerte nicht umsetzen - Standby (QU_TAR_QTA_STMOM_DV_Sollwerte_nicht_umsetzen_Standby) (Es wird kein Moment angefordert.), 15=Signal ungültig (QU_TAR_QTA_STMOM_DV_Signal_ungueltig) (Wird nicht aktiv gesetzt)  # Qualifier_Soll_Anteil_Lenkmoment_Fahrer / Qualifier_target_quota_steering-moment_driver
  compu method ID_FN_INQY: 41216=Bedienung Tasten Entertainment (ID_FN_INQY_Bedienung_Tasten_Entertainment), 62976=Steuerung Außenspiegel (ID_FN_INQY_Steuerung_Aussenspiegel), 57857=Sicher Fahrgestellnummer (ID_FN_INQY_Sicher_Fahrgestellnummer), 9730=Regensensor-Wischergeschwindigkeit (ID_FN_INQY_Regensensor_Wischergeschwindigkeit), 14850=Status Funkschlüssel (ID_FN_INQY_Status_Funkschluessel), 26370=Bedienung Tastgeber Bedienelement Front (ID_FN_INQY_Bedienung_Tastgeber_Bedienelement_Front), 32258=Status Verdeck Cabrio (ID_FN_INQY_Status_Verdeck_Cabrio) (Wird ab BN2020 nur noch von HMI verwendet), 36866=Status Schlüssel Suche (ID_FN_INQY_Status_Schluessel_Suche), 58882=Status Klima Luftverteilung FA (ID_FN_INQY_Status_Klima_Luftverteilung_FA), 59906=Status Klima Luftverteilung BF (ID_FN_INQY_Status_Klima_Luftverteilung_BF), 60418=Status Klima SH/ZH Zusatzwasserpumpe (ID_FN_INQY_Status_Klima_SH_ZH_Zusatzwasserpumpe), 60930=Status Klima Zusatzprogramme (ID_FN_INQY_Status_Klima_Zusatzprogramme) (Wird ab BN2020 nur noch von HMI verwendet), 61442=Status Klima Standfunktionen (ID_FN_INQY_Status_Klima_Standfunktionen), 63234=Einheiten BN2020 (ID_FN_INQY_Einheiten_BN2020), 63490=Uhrzeit/Datum (ID_FN_INQY_Uhrzeit_Datum), 3843=Status Service Call TeleX (ID_FN_INQY_Status_Service_Call_TeleX), 4867=Status Service Call Teleservice (ID_FN_INQY_Status_Service_Call_Teleservice), 12803=Verbrauch Information Daten (ID_FN_INQY_Verbrauch_Information_Daten), 13827=Anzeige Checkcontrol-Meldung (Rolle) (ID_FN_INQY_Anzeige_Checkcontrol_Meldung_Rolle_), 14851=Status Monitor Front (ID_FN_INQY_Status_Monitor_Front) ((E60, RR01) Wird ab BN2020 nur noch von HMI verwendet / (E60, RR01)), 16643=Status Kartendaten (ID_FN_INQY_Status_Kartendaten), 23555=Status Bordcomputer BN2020 (ID_FN_INQY_Status_Bordcomputer_BN2020) ((E60)), 24579=Daten Bordcomputer (Fahrtbeginn) (ID_FN_INQY_Daten_Bordcomputer_Fahrtbeginn_) ((E60)), 32771=Fahrgestellnummer (ID_FN_INQY_Fahrgestellnummer), 33027=Elektronischer Motorölmessstab (ID_FN_INQY_Elektronischer_Motoroelmessstab), 34819=Fahrzeugtyp (ID_FN_INQY_Fahrzeugtyp), 38147=Codierung Powermanagement (ID_FN_INQY_Codierung_Powermanagement), 40451=Bedienung_Uhrzeit_Datum (ID_FN_INQY_Bedienung_Uhrzeit_Datum), 43523=Bedienung_Uhrzeit_Datum_UTC (ID_FN_INQY_Bedienung_Uhrzeit_Datum_UTC), 43779=Bedienung_Datum_Winterzeit_Sommerzeit (ID_FN_INQY_Bedienung_Datum_Winterzeit_Sommerzeit), 46595=Position Fensterheber FAT (ID_FN_INQY_Position_Fensterheber_FAT) (ACHTUNG: Hier wird der CAN-Identifier der Nachricht angegeben, auch wenn die Nachricht beim E60 vom SI-Bus kommt. Die E60-Türelektronik FAT am SI-Bus müssen auf diese Codierung reagieren und die Nachricht Position Fensterheber FAT auf Anfrage raussenden. / ATTENTION:The CAN identifier of the message cannot be given here, even if the message comes from the SI bus with E60. The E60 door electronics DRD on the SI bus must react to this coding and send out the position of window regulator DRD message on request.), 46851=Position Fensterheber FATH (ID_FN_INQY_Position_Fensterheber_FATH), 47107=Position Fensterheber BFT (ID_FN_INQY_Position_Fensterheber_BFT) (ACHTUNG: Hier wird der CAN-Identifier der Nachricht angegeben, auch wenn die Nachricht beim E60 vom SI-Bus kommt. Die E60-Türelektronik BFT am SI-Bus müssen auf diese Codierung reagieren und die Nachricht Position Fensterheber BFT auf Anfrage raussenden. / ATTENTION:The CAN identifier of the message is given here, even if the message comes from the SI bus with E60. The E60 door electronics PSD on the SI bus must react to this coding and send out the position of electric windows PSD message on request.), 47363=Position Fensterheber BFTH (ID_FN_INQY_Position_Fensterheber_BFTH), 47619=Position SHD (ID_FN_INQY_Position_SHD), 48131=Position Fensterheber Sicherheitsfahrzeug (ID_FN_INQY_Position_Fensterheber_Sicherheitsfahrzeug), 48899=Position Fensterheber Heckscheibe (ID_FN_INQY_Position_Fensterheber_Heckscheibe), 49155=Konfiguration FAS (ID_FN_INQY_Konfiguration_FAS), 49411=Konfiguration BFS (ID_FN_INQY_Konfiguration_BFS), 49667=Konfiguration FASH (ID_FN_INQY_Konfiguration_FASH), 49923=Konfiguration BFSH (ID_FN_INQY_Konfiguration_BFSH), 53251=Status Spurverlassenswarnsystem CKM (ID_FN_INQY_Status_Spurverlassenswarnsystem_CKM), 54531=Status Zentralverriegelung CKM (ID_FN_INQY_Status_Zentralverriegelung_CKM), 55043=Status DWA CKM (ID_FN_INQY_Status_DWA_CKM), 56067=Status Memorypositionen CKM (ID_FN_INQY_Status_Memorypositionen_CKM), 56579=Status Licht CKM (ID_FN_INQY_Status_Licht_CKM), 57603=Status ALC CKM (ID_FN_INQY_Status_ALC_CKM), 58115=Status Heckklappe CKM (ID_FN_INQY_Status_Heckklappe_CKM), 60163=Grenzwerte Schwenk Links (ID_FN_INQY_Grenzwerte_Schwenk_Links), 60419=Grenzwerte Schwenk Rechts (ID_FN_INQY_Grenzwerte_Schwenk_Rechts), 61699=Status Licht Erweitert CKM (ID_FN_INQY_Status_Licht_Erweitert_CKM), 9731=Wirkungsgrad Information Data (ID_FN_INQY_Wirkungsgrad_Information_Data), 10243=Relativzeit BN2020 (ID_FN_INQY_Relativzeit_BN2020), 3588=GPS_Datum_CAN (ID_FN_INQY_GPS_Datum_CAN), 3844=GPS_Uhrzeit_CAN (ID_FN_INQY_GPS_Uhrzeit_CAN), 6660=Status Konfiguration Kombi 4 (ID_FN_INQY_Status_Konfiguration_Kombi_4), 9220=Status Konfiguration Kombi (ID_FN_INQY_Status_Konfiguration_Kombi), 9988=Konfiguration DSC (ID_FN_INQY_Konfiguration_DSC), 11780=Status M-Drive 2 (ID_FN_INQY_Status_M_Drive_2), 13316=Konfiguration EPS (ID_FN_INQY_Konfiguration_EPS), 13572=Messung Motoröl (ID_FN_INQY_Messung_Motoroel), 16132=Identifikationsnummer Sensorcluster (ID_FN_INQY_Identifikationsnummer_Sensorcluster), 16642=Status_Hindernis_Tuer (ID_FN_INQY_Status_Hindernis_Tuer), 65535=Signal_unbefuellt (ID_FN_INQY_Signal_unbefuellt), 65533=Reserviert_nicht_verfuegbar (ID_FN_INQY_Reserviert_nicht_verfuegbar) (Hinweis: Reserviert für funktionale Kennung Signal-Tag "Funktionsschnittstelle_ist_nicht_verfuegbar"), 65534=Reserviert_Fehler (ID_FN_INQY_Reserviert_Fehler) (Hinweis: Reserviert für funktionale Kennung Signal-Tag "Funktion_meldet_Fehler")  # ID_Funktion_Anfrage / ID_function_inquiry
  compu method NO_VECH_5: identical  # Nummer_Fahrgestell_5 / number_vehicle-chassis_5
  compu method ST_IDC_CC_EPS: 0=Kein Blinken (ST_IDC_CC_EPS_Kein_Blinken), 1=Langsames Blinken (ST_IDC_CC_EPS_Langsames_Blinken) (Langsamer Takt = 1 Hz), 2=Schnelles Blinken (ST_IDC_CC_EPS_Schnelles_Blinken) (Schneller Takt = 3 Hz), 3=Signal ungültig (ST_IDC_CC_EPS_Signal_ungueltig)  # Status_Blinken_Checkcontrol_EPS / status_indicate-direction_check-control_EPS
  compu method QU_TAR_DMPNG_ADDON_STMOM_FTAX: 1=Sollwert Zusatzdämpfung nicht umsetzen (QU_TAR_DMPNG_ADDON_STMOM_FTAX_Sollwert_Zusatzdaempfung_nicht_umsetzen), 2=Sollwert Zusatzdämpfung umsetzen (QU_TAR_DMPNG_ADDON_STMOM_FTAX_Sollwert_Zusatzdaempfung_umsetzen), 15=Signal unbefüllt (QU_TAR_DMPNG_ADDON_STMOM_FTAX_Signal_unbefuellt) (Wird nicht aktiv gesetzt)  # Qualifier_Soll_Dämpfung_Zusatz_Lenkmoment_Vorderachse / Qualifier_target_damping_add-on_steering-moment_front-axle
  compu method ST_CON_VEH: 0=reserviert (ST_CON_VEH_reserviert), 1=Parken_BN_niO (ST_CON_VEH_Parken_BN_niO), 2=Parken_BN_iO (ST_CON_VEH_Parken_BN_iO), 3=Standfunktionen_Kunde_nicht_im_FZG (ST_CON_VEH_Standfunktionen_Kunde_nicht_im_FZG), 5=Wohnen (ST_CON_VEH_Wohnen), 7=Pruefen_Analyse_Diagnose (ST_CON_VEH_Pruefen_Analyse_Diagnose), 8=Fahrbereitschaft_herstellen (ST_CON_VEH_Fahrbereitschaft_herstellen), 10=Fahren (ST_CON_VEH_Fahren), 12=Fahrbereitschaft_beenden (ST_CON_VEH_Fahrbereitschaft_beenden), 13=reserviert (ST_CON_VEH_reserviert_2) (Hinweis: Reserviert für funktionale Kennung Signal-Tag.), 14=reserviert (ST_CON_VEH_reserviert_3) (Hinweis: Reserviert für funktionale Kennung Signal-Tag.), 15=Signal_unbefuellt (ST_CON_VEH_Signal_unbefuellt)  # Status_Zustand_Fahrzeug / status_condition_vehicle
  compu method FKTN_PRTNT: mask 2147483649: 0=Konfiguration aus (FKTN_PRTNT_Konfiguration_aus), mask 2147483649: 1=Konfiguration ein (FKTN_PRTNT_Konfiguration_ein), mask 2147483650: 0=Ethernet Infrastruktur aus (FKTN_PRTNT_Ethernet_Infrastruktur_aus), mask 2147483650: 2=Ethernet Infrastruktur ein (FKTN_PRTNT_Ethernet_Infrastruktur_ein), mask 2147483652: 0=Datenkommunikation_aus (FKTN_PRTNT_Datenkommunikation_aus) (Gilt ab SP2018), mask 2147483652: 4=Datenkommunikation_ein (FKTN_PRTNT_Datenkommunikation_ein) (Gilt ab SP2018), mask 2147483904: 0=Klimabetrieb aus (FKTN_PRTNT_Klimabetrieb_aus), mask 2147483904: 256=Klimabetrieb ein (FKTN_PRTNT_Klimabetrieb_ein), mask 2147484160: 0=Entertainmentbetrieb aus (FKTN_PRTNT_Entertainmentbetrieb_aus), mask 2147484160: 512=Entertainmentbetrieb ein (FKTN_PRTNT_Entertainmentbetrieb_ein), mask 2147484672: 0=Externe_Kommunikation aus (FKTN_PRTNT_Externe_Kommunikation_aus), mask 2147484672: 1024=Externe_Kommunikation ein (FKTN_PRTNT_Externe_Kommunikation_ein), mask 2147485696: 0=Entertainmentbetrieb_Fond_aus (FKTN_PRTNT_Entertainmentbetrieb_Fond_aus) (Gilt ab SP2018), mask 2147485696: 2048=Entertainmentbetrieb_Fond_ein (FKTN_PRTNT_Entertainmentbetrieb_Fond_ein) (Gilt ab SP2018), mask 2147487744: 0=Assistenz_Parken_high aus (FKTN_PRTNT_Assistenz_Parken_high_aus), mask 2147487744: 4096=Assistenz_Parken_high ein (FKTN_PRTNT_Assistenz_Parken_high_ein), mask 2147516416: 0=Laden aus (FKTN_PRTNT_Laden_aus), mask 2147516416: 32768=Laden ein (FKTN_PRTNT_Laden_ein), mask 2147549184: 0=Fahrzeug Infrastruktur aus (FKTN_PRTNT_Fahrzeug_Infrastruktur_aus), mask 2147549184: 65536=Fahrzeug Infrastruktur ein (FKTN_PRTNT_Fahrzeug_Infrastruktur_ein), mask 2148007936: 0=Licht_aus (FKTN_PRTNT_Licht_aus) (Gilt ab SP2018), mask 2148007936: 524288=Licht_ein (FKTN_PRTNT_Licht_ein) (Gilt ab SP2018), mask 2148532224: 0=TN_48V_aus (FKTN_PRTNT_TN_48V_aus), mask 2148532224: 1048576=TN_48V_ein (FKTN_PRTNT_TN_48V_ein), mask 4294967295: 4294967295=Signal_unbefuellt (FKTN_PRTNT_Signal_unbefuellt)  # Funktionale_Teilnetze / functional_partial-networks
  compu method DIAG_ST_OBD: identical  # Diagnose_Status_OBD / diagnosis_status_OBD
  compu method UI_8_noIniVal_noDflVal_255_0_50s_MI_40_noEnc_hasRng: phys=raw*0.5-40; unit °C  # UI_8_noIniVal_noDflVal_255_0.50s_Minus_40_noEnc_hasRng / UI_8_noIniVal_noDflVal_255_0.50s_minus_40_noEnc_hasRng
  compu method NO_VECH_4: identical  # Nummer_Fahrgestell_4 / number_vehicle-chassis_4
  compu method ST_OFFS_QUAD_PINA_EPS: 0=Algorithmus (Funktion) im Sleep-Modus (ST_OFFS_QUAD_PINA_EPS_Algorithmus_Funktion_im_Sleep_Modus) (Die Funktion ist bereit aber zur Zeit nicht aktiv), 1=Offset wird ermittelt (ST_OFFS_QUAD_PINA_EPS_Offset_wird_ermittelt), 2=Offset übernehmen, Aufsetzen über Index (ST_OFFS_QUAD_PINA_EPS_Offset_uebernehmen_Aufsetzen_ueber_Index) (Kann nur gesendet werden wenn Qualifier_Ist_Position_EPS = Ersatzwert oder ab SP2013 (außer F15-F16, 444) "Signalwert ist gültig, Zustand/Status temporär"), 3=Offset übernehmen, Aufsetzen über Modelvergleich (ST_OFFS_QUAD_PINA_EPS_Offset_uebernehmen_Aufsetzen_ueber_Modelvergleich) (Kann nur gesendet werden wenn Qualifier_Ist_Position_EPS = Ersatzwert oder ab SP2013 (außer F15-F16, 444) "Signalwert ist gültig, Zustand/Status temporär"), 4=Offset übernehmen, Aufsetzen über Anschlag-Anschlag (ST_OFFS_QUAD_PINA_EPS_Offset_uebernehmen_Aufsetzen_ueber_Anschlag_Anschlag) (Kann nur gesendet werden wenn Qualifier_Ist_Position_EPS = Ersatzwert oder ab SP2013 (außer F15-F16, 444) "Signalwert ist gültig, Zustand/Status temporär"), 5=Offset übernehmen, Aufsetzen über Summenlenkwinkel (im AFS-Fall) (ST_OFFS_QUAD_PINA_EPS_Offset_uebernehmen_Aufsetzen_ueber_Summenlenkwinkel_im_AFS_Fall_) (Kann nur gesendet werden wenn Qualifier_Ist_Position_EPS = Ersatzwert oder ab SP2013 (außer F15-F16, 444) "Signalwert ist gültig, Zustand/Status temporär" Wird zurzeit nicht verwendet.), 6=Offset in Prüfung (ST_OFFS_QUAD_PINA_EPS_Offset_in_Pruefung) (Wird gesetzt nach Offset übernehmen (nicht nach Groboffset!) bzw. sofern die EPS sich selbst aufsetzen konnte und nach Offset korrigieren, während der Bestätigungsphase.), 7=Offset korrigieren (ST_OFFS_QUAD_PINA_EPS_Offset_korrigieren) (Kann nur gesendet werden wenn Qualifier_Ist_Position_EPS = "Gültig" oder "Gültig und Abgesichert"), 8=Initialisierung (ST_OFFS_QUAD_PINA_EPS_Initialisierung) (wird im aller ersten Rechenzyklus gesetzt (10ms)), 9=Restoffset wird ermittelt (ST_OFFS_QUAD_PINA_EPS_Restoffset_wird_ermittelt) (Wird gesetzt, nachdem im Zustand "Offset wird ermittelt" erstmals nur ein Groboffset bestimmt und an die EPS gesendet werden konnte. Wird erst ab SP2013 (außer F15-F16, 444) unterstützt.), 11=Offset übernehmen, Groboffset über Modell (ST_OFFS_QUAD_PINA_EPS_Offset_uebernehmen_Groboffset_ueber_Modell) (Kann nur gesendet werden wenn Qualifier_Ist_Position_EPS = Ersatzwert Wird erst ab SP2013 (außer F15-F16, 444) unterstützt.), 15=Signal ungültig (ST_OFFS_QUAD_PINA_EPS_Signal_ungueltig) (Kann Funktional nicht gesetzt werden)  # Status_Offset_Quadrant_Ritzelwinkel_EPS / status_offset_quadrant_pinion-angle_EPS
  compu method QU_AVL_FORC_GRD: 8=Initialisierung (QU_AVL_FORC_GRD_Initialisierung) (At the startup of the TSU driver. Nutzsignal wird permanent mit 0,0016 befüllt.), 2=Signalwert ist gültig (QU_AVL_FORC_GRD_Signalwert_ist_gueltig) (The signal is valid since every input signal is valid FUSI: Do not use for safety critical functions), 14=Signalwert ist ungültig, Zustand/Status temporär (QU_AVL_FORC_GRD_Signalwert_ist_ungueltig_Zustand_Status_temporaer) (The signal is invalid since one of the input signals is invalid. Das zugehörige Nutzsignal wird permanent mit der Ungültigkeitskennung befüllt.), 15=Signal ungültig (QU_AVL_FORC_GRD_Signal_ungueltig) (Kann Funktional nicht gesetzt werden)  # Qualifier_Ist_Kraft_Zahnstange / Qualifier_actual-value_force_gear-rod
  compu method RQ_RST_OBD_DIAG: 0=Keine Anforderung Reset OBD_Diagnose (RQ_RST_OBD_DIAG_Keine_Anforderung_Reset_OBD_Diagnose), 2=Anforderung Reset OBD_Diagnose (RQ_RST_OBD_DIAG_Anforderung_Reset_OBD_Diagnose), 3=Signal ungültig (RQ_RST_OBD_DIAG_Signal_ungueltig)  # Anforderung_Reset_OBD_Diagnose / request_reset_OBD_diagnosis
  compu method CTR_WARN_ILVL_VIB_EPS: 0=Intensitaetsstufe_0 (CTR_WARN_ILVL_VIB_EPS_Intensitaetsstufe_0) (Diese Codierung wird auch verwendet, wenn keine haptische Warnung erfolgt.), 1=Intensitaetsstufe_1 (CTR_WARN_ILVL_VIB_EPS_Intensitaetsstufe_1), 2=Intensitaetsstufe_2 (CTR_WARN_ILVL_VIB_EPS_Intensitaetsstufe_2), 3=Intensitaetsstufe_3 (CTR_WARN_ILVL_VIB_EPS_Intensitaetsstufe_3), 4=Intensitaetsstufe_4 (CTR_WARN_ILVL_VIB_EPS_Intensitaetsstufe_4), 5=Intensitaetsstufe_5 (CTR_WARN_ILVL_VIB_EPS_Intensitaetsstufe_5), 6=Intensitaetsstufe_6 (CTR_WARN_ILVL_VIB_EPS_Intensitaetsstufe_6), 7=Intensitaetsstufe_7 (CTR_WARN_ILVL_VIB_EPS_Intensitaetsstufe_7), 8=Intensitaetsstufe_8 (CTR_WARN_ILVL_VIB_EPS_Intensitaetsstufe_8), 9=Intensitaetsstufe_9 (CTR_WARN_ILVL_VIB_EPS_Intensitaetsstufe_9), 10=Intensitaetsstufe_10 (CTR_WARN_ILVL_VIB_EPS_Intensitaetsstufe_10), 11=Intensitaetsstufe_11 (CTR_WARN_ILVL_VIB_EPS_Intensitaetsstufe_11), 12=Intensitaetsstufe_12 (CTR_WARN_ILVL_VIB_EPS_Intensitaetsstufe_12), 13=Reserviert (CTR_WARN_ILVL_VIB_EPS_Reserviert) (Hinweis: Reserviert für funktionale Kennung Signal-Tag.), 14=Reserviert (CTR_WARN_ILVL_VIB_EPS_Reserviert_2) (Hinweis: Reserviert für funktionale Kennung Signal-Tag.), 15=Signal_unbefuellt (CTR_WARN_ILVL_VIB_EPS_Signal_unbefuellt) (Sendefunktion nicht in Betrieb)  # Steuerung_Warnung_Intensitätsstufe_Vibration_EPS / control_warning_intensity-level_vibration_EPS
  compu method SU_CLU_STMOM_SFE_DXP: 1=Ultrahart (SU_CLU_STMOM_SFE_DXP_Ultrahart), 2=Sportlich ausgewogen (SU_CLU_STMOM_SFE_DXP_Sportlich_ausgewogen), 3=Ausgewogen (SU_CLU_STMOM_SFE_DXP_Ausgewogen), 4=Weich (SU_CLU_STMOM_SFE_DXP_Weich), 13=Funktionsschnittstelle_ist_nicht_verfuegbar (SU_CLU_STMOM_SFE_DXP_Funktionsschnittstelle_ist_nicht_verfuegbar) (Sendefunktion in Betrieb, Werte nicht verfügbar), 14=Funktion_meldet_Fehler (SU_CLU_STMOM_SFE_DXP_Funktion_meldet_Fehler) (Sendefunktion in Betrieb, meldet Fehler), 15=Signal_unbefuellt (SU_CLU_STMOM_SFE_DXP_Signal_unbefuellt) (Sendefunktion nicht in Betrieb)  # Konfiguration_Cluster_Lenkmoment_Lenkgefühl_Fahrerlebnis / setup_cluster_steering-moment_steering-feel_driving-experience
  compu method RQ_STG_EFAN: 0=AUS (RQ_STG_EFAN_AUS), 1..14=Stufe, 15=Signal ungültig (RQ_STG_EFAN_Signal_ungueltig)  # Anforderung_Stufe_Elektrolüfter / request_stage_electric-fan
  compu method AVL_PINA_EPS: phys=raw*0.0439453125-1439.956055  # Ist_Ritzelwinkel_EPS / actual-value_pinion-angle_EPS
  compu method ID_TEMP_CPO_HET_MNG: 1=EPS-Motortemperatur (ID_TEMP_CPO_HET_MNG_EPS_Motortemperatur), 13=Reserviert (ID_TEMP_CPO_HET_MNG_Reserviert) (Hinweis: Reserviert für funktionale Kennung Signal-Tag.), 14=Reserviert (ID_TEMP_CPO_HET_MNG_Reserviert_2) (Hinweis: Reserviert für funktionale Kennung Signal-Tag.), 15=Signal_unbefuellt (ID_TEMP_CPO_HET_MNG_Signal_unbefuellt) (Sendefunktion nicht in Betrieb)  # ID_Temperatur_Komponente_Wärme_Management / ID_temperature_component_heat_management
package /BMW/SystemDescription/DataConstrs
  data constr TRANF_CC_EPS: data-constr-rule{phys-constrs={lower-limit=0, upper-limit=14, unit=s}, internal-constrs={lower-limit=0, upper-limit=15, scale-constr{lower-limit=15, upper-limit=15}}}  # Sendeart_Checkcontrol_EPS / transmitting-form_check-control_EPS
  data constr AVL_PWR_EL: data-constr-rule{phys-constrs={lower-limit=-12, upper-limit=12, unit=kW}, internal-constrs={lower-limit=0, upper-limit=255, scale-constr{lower-limit=255, upper-limit=255}}}  # Ist_Leistung_Elektrisch / actual-value_power_electric
  data constr NO_VECH_1: data-constr-rule=internal-constrs={lower-limit=0, upper-limit=255, scale-constr{lower-limit=255, upper-limit=255}}  # Nummer_Fahrgestell_1 / number_vehicle-chassis_1
  data constr OFFS_QUAD_PINA_EPS: data-constr-rule{phys-constrs={lower-limit=-127, upper-limit=127, unit=no_unit}, internal-constrs={lower-limit=0, upper-limit=255, scale-constr{lower-limit=255, upper-limit=255}}}  # Offset_Quadrant_Ritzelwinkel_EPS / offset_quadrant_pinion-angle_EPS
  data constr ST_UDP: data-constr-rule=internal-constrs={lower-limit=0, upper-limit=15, scale-constr{lower-limit=15, upper-limit=15}}  # Status_Spannungseinbruch / status_voltage-drop
  data constr QU_FN_FDR: data-constr-rule=internal-constrs={lower-limit=0, upper-limit=4095, scale-constr{lower-limit=4095, upper-limit=4095}}  # Qualifier_Funktion_FDR / Qualifier_function_FDR
  data constr TEMP_CPO_HET_MNG: data-constr-rule{phys-constrs={lower-limit=-48, upper-limit=204, unit=°C}, internal-constrs={lower-limit=0, upper-limit=255, scale-constr{lower-limit=255, upper-limit=255}}}  # Temperatur_Komponente_Wärme_Management / temperature_component_heat_management
  data constr ST_ANO_MSA_ENG_STOP: data-constr-rule=internal-constrs={lower-limit=0, upper-limit=3, scale-constr{lower-limit=3, upper-limit=3}}  # Status_Ankündigung_MSA_Motor_Stop / status_announcement_MSA_engine_stop
  data constr STU_RESP: data-constr-rule=internal-constrs={lower-limit=0, upper-limit=16777215, scale-constr{lower-limit=16777215, upper-limit=16777215}}  # Signatur_Response / signature_response
  data constr QU_ACLNY_COG: data-constr-rule=internal-constrs={lower-limit=0, upper-limit=15, scale-constr{lower-limit=15, upper-limit=15}}  # Qualifier_Querbeschleunigung_Schwerpunkt / Qualifier_lateral-acceleration_centre-of-gravity
  data constr NO_CC_EPS: data-constr-rule{phys-constrs={lower-limit=0, upper-limit=65534, unit=no_unit}, internal-constrs={lower-limit=0, upper-limit=65535, scale-constr{lower-limit=65535, upper-limit=65535}}}  # Nummer_Checkcontrol_EPS / number_check-control_EPS
  data constr CHL_4_UInt: data-constr-rule{phys-constrs={lower-limit=0, upper-limit=14, unit=no_unit}, internal-constrs={lower-limit=0, upper-limit=15, scale-constr{lower-limit=15, upper-limit=15}}}
  data constr ID_FN_RQ_STG_EFAN: data-constr-rule=internal-constrs={lower-limit=0, upper-limit=255, scale-constr{lower-limit=255, upper-limit=255}}  # ID_Funktion_Anforderung_Stufe_Elektrolüfter / ID_function_request_stage_electric-fan
  data constr ST_CC_EPS: data-constr-rule=internal-constrs={lower-limit=0, upper-limit=3, scale-constr{lower-limit=3, upper-limit=3}}  # Status_Checkcontrol_EPS / status_check-control_EPS
  data constr ST_DIAG_OBD_MUX_MAX: data-constr-rule{phys-constrs={lower-limit=4, upper-limit=60, unit=no_unit}, internal-constrs={lower-limit=0, upper-limit=63, scale-constr{lower-limit=63, upper-limit=63}}}  # Status_Diagnose_OBD_Multiplexer_Maximal / status_diagnosis_OBD_multiplexer_maximum
  data constr ALIV_COU_V: data-constr-rule=internal-constrs={lower-limit=0, upper-limit=15, scale-constr{lower-limit=15, upper-limit=15}}  # Alive_Zähler_Geschwindigkeit / alive_counter_speed
  data constr AVL_FORC_GRD: data-constr-rule{phys-constrs={lower-limit=-17, upper-limit=17, unit=kN}, internal-constrs={lower-limit=0, upper-limit=4095, scale-constr{lower-limit=4095, upper-limit=4095}}}  # Ist_Kraft_Zahnstange / actual-value_force_gear-rod
  data constr STMOM_QTA_DV: data-constr-rule{phys-constrs={lower-limit=-10, upper-limit=10, unit=Nm}, internal-constrs={lower-limit=0, upper-limit=4095, scale-constr{lower-limit=4095, upper-limit=4095}}}  # Lenkmoment_Anteil_Fahrer / steering-moment_quota_driver
  data constr ALIV_4_BIT_UInt: data-constr-rule{phys-constrs={lower-limit=0, upper-limit=14, unit=no_unit}, internal-constrs={lower-limit=0, upper-limit=15, scale-constr{lower-limit=15, upper-limit=15}}}  # Alive_4_Bit_UInt / alive_4_bit_UInt
  data constr ST_DCSW: data-constr-rule=internal-constrs={lower-limit=0, upper-limit=3, scale-constr{lower-limit=3, upper-limit=3}}  # Status_Trennschalter / status_disconnecting-switch
  data constr SECU_CHAL: data-constr-rule=internal-constrs={lower-limit=0, upper-limit=1099511627775, scale-constr{lower-limit=1099511627775, upper-limit=1099511627775}}  # Sicher_Challenge / secure_challenge
  data constr STU_8_BYTE: data-constr-rule=internal-constrs={lower-limit=0, upper-limit=18446744073709551615, scale-constr{lower-limit=18446744073709551615, upper-limit=18446744073709551615}}  # Signatur_8_Byte / signature_8_byte
  data constr ST_CULI_EST: data-constr-rule=internal-constrs={lower-limit=0, upper-limit=15, scale-constr{lower-limit=15, upper-limit=15}}  # Status_Strombegrenzung_Elektrische-Lenkung / status_current-limitation_electrical-steering
  data constr FACT_CTRR_STMOM_FTAX: data-constr-rule{phys-constrs={lower-limit=0.0078125, upper-limit=1, unit=no_unit}, internal-constrs={lower-limit=0, upper-limit=255, scale-constr{lower-limit=255, upper-limit=255}}}  # Faktor_Zentrierung_Lenkmoment_Vorderachse / factor_centering_steering-moment_front-axle
  data constr DVCO_VEH: data-constr-rule=internal-constrs={lower-limit=0, upper-limit=7, scale-constr{lower-limit=7, upper-limit=7}}  # Fahrzustand_Fahrzeug / driving-condition_vehicle
  data constr QU_TAR_FACT_STMOM_FTAX: data-constr-rule=internal-constrs={lower-limit=0, upper-limit=15, scale-constr{lower-limit=15, upper-limit=15}}  # Qualifier_Soll_Faktor_Lenkmoment_Vorderachse / Qualifier_target_factor_steering-moment_front-axle
  data constr VYAW_VEH: data-constr-rule{phys-constrs={lower-limit=-163.84, upper-limit=163.83, unit=°/s}, internal-constrs={lower-limit=0, upper-limit=65535, scale-constr{lower-limit=65535, upper-limit=65535}}}  # Giergeschwindigkeit_Fahrzeug / yaw-velocity_vehicle
  data constr ALIV_4_BIT_Unsigned_Integer: data-constr-rule{phys-constrs={lower-limit=0, upper-limit=14, unit=no_unit}, internal-constrs={lower-limit=0, upper-limit=15, scale-constr{lower-limit=15, upper-limit=15}}}  # Alive_4_Bit_Unsigned_Integer / alive_4_bit_Unsigned_Integer
  data constr RQ_CULI: data-constr-rule=internal-constrs={lower-limit=0, upper-limit=15, scale-constr{lower-limit=15, upper-limit=15}}  # Anforderung_Strombegrenzung / request_current-limitation
  data constr AVL_RPM_WHL: data-constr-rule{phys-constrs={lower-limit=-400.0, upper-limit=400.0, unit=rad/s}, internal-constrs={lower-limit=0, upper-limit=65535, scale-constr{lower-limit=65535, upper-limit=65535}}}  # Ist_Drehzahl_Rad / actual-value_RPM_wheel
  data constr MILE_KM: data-constr-rule{phys-constrs={lower-limit=0, upper-limit=16777214, unit=km}, internal-constrs={lower-limit=0, upper-limit=16777215, scale-constr{lower-limit=16777215, upper-limit=16777215}}}  # Wegstrecke_Kilometer / mileage_kilometre
  data constr NO_VECH_7: data-constr-rule=internal-constrs={lower-limit=0, upper-limit=255, scale-constr{lower-limit=255, upper-limit=255}}  # Nummer_Fahrgestell_7 / number_vehicle-chassis_7
  data constr ST_MOT_DRV: data-constr-rule=internal-constrs={lower-limit=0, upper-limit=3, scale-constr{lower-limit=3, upper-limit=3}}  # Status_E-Motor_Antrieb / status_motor_drive
  data constr ST_LDREL_GEN: data-constr-rule=internal-constrs={lower-limit=0, upper-limit=15, scale-constr{lower-limit=15, upper-limit=15}}  # Status_Entlastung_Generator / status_load-relieving_generator
  data constr I_SPEC_ARS: data-constr-rule{phys-constrs={lower-limit=0, upper-limit=252, unit=A}, internal-constrs={lower-limit=0, upper-limit=255, scale-constr{lower-limit=255, upper-limit=255}}}  # Strom_Vorgabe_ARS / current_specification_ARS
  data constr FACT_DMPNG_ADDON_STMOM_FTAX: data-constr-rule{phys-constrs={lower-limit=0, upper-limit=2, unit=no_unit}, internal-constrs={lower-limit=0, upper-limit=255, scale-constr{lower-limit=255, upper-limit=255}}}  # Faktor_Dämpfung_Zusatz_Lenkmoment_Vorderachse / factor_damping_add-on_steering-moment_front-axle
  data constr ST_OBD_CYC: data-constr-rule=internal-constrs={lower-limit=0, upper-limit=63, scale-constr{lower-limit=63, upper-limit=63}}  # Status_OBD_Zyklus / status_OBD_cycle
  data constr ACLNY_COG: data-constr-rule{phys-constrs={lower-limit=-65, upper-limit=65, unit=m/s²}, internal-constrs={lower-limit=0, upper-limit=65535, scale-constr{lower-limit=65535, upper-limit=65535}}}  # Querbeschleunigung_Schwerpunkt / lateral-acceleration_centre-of-gravity
  data constr MIN_I_SPEC_ARS: data-constr-rule{phys-constrs={lower-limit=-252, upper-limit=0, unit=A}, internal-constrs={lower-limit=0, upper-limit=255, scale-constr{lower-limit=255, upper-limit=255}}}  # Minimal_Strom_Vorgabe_ARS / minimum_current_specification_ARS
  range DBG_8Bit: raw 0..255  # Debug_8Bit / debug_8Bit
  data constr UN_TOT_STR_EPS: data-constr-rule=internal-constrs={lower-limit=0, upper-limit=3, scale-constr{lower-limit=3, upper-limit=3}}  # Einheit_Gesamt_Lenkübersetzung_EPS / unit-of-measurement_total_steering-ratio_EPS
  data constr ALIV_COU_4: data-constr-rule=internal-constrs={lower-limit=0, upper-limit=15, scale-constr{lower-limit=15, upper-limit=15}}  # Alive_Zähler_4 / alive_counter_4
  data constr NO_VECH_6: data-constr-rule=internal-constrs={lower-limit=0, upper-limit=255, scale-constr{lower-limit=255, upper-limit=255}}  # Nummer_Fahrgestell_6 / number_vehicle-chassis_6
  data constr AVL_STEA_PNI_OFFS: data-constr-rule{phys-constrs={lower-limit=-45, upper-limit=45, unit=no_unit}, internal-constrs={lower-limit=0, upper-limit=4095, scale-constr{lower-limit=4095, upper-limit=4095}}}  # Ist_Lenkwinkel_Ritzel_Offset / actual-value_steering-angle_pinion_offset
  data constr ACTVN_FN_ESTP_VIRT_FTAX: data-constr-rule=internal-constrs={lower-limit=0, upper-limit=15, scale-constr{lower-limit=15, upper-limit=15}}  # Aktivierung_Funktion_Endanschlag_Virtuell_Vorderachse / activation_function_end-stop_virtual_front-axle
  data constr VYAW_VEH_ERR_AMP: data-constr-rule{phys-constrs={lower-limit=0, upper-limit=50, unit=°/s}, internal-constrs={lower-limit=0, upper-limit=4095, scale-constr{lower-limit=4095, upper-limit=4095}}}  # Giergeschwindigkeit_Fahrzeug_Fehler_Amplitude / yaw-velocity_vehicle_error_amplidue
  data constr QU_TAR_STMOM_DV_ACT: data-constr-rule=internal-constrs={lower-limit=0, upper-limit=15, scale-constr{lower-limit=15, upper-limit=15}}  # Qualifier_Soll_Lenkmoment_Fahrer_Stellglied / Qualifier_target_steering-moment_driver_actuator
  data constr RQ_CULI_EST_SFY: data-constr-rule=internal-constrs={lower-limit=0, upper-limit=15, scale-constr{lower-limit=15, upper-limit=15}}  # Anforderung_Strombegrenzung_Elektrische-Lenkung_Sicherheit / request_current-limitation_electrical-steering_safety
  data constr OFFS_GRD_MID_EPS: data-constr-rule{phys-constrs={lower-limit=-89.9560546875, upper-limit=89.9560546875, unit=no_unit}, internal-constrs={lower-limit=0, upper-limit=4095, scale-constr{lower-limit=4095, upper-limit=4095}}}  # Offset_Zahnstange_Mitte_EPS / offset_gear-rod_middle_EPS
  data constr QU_SER_STMOM_STMOM_DV_ACT: data-constr-rule=internal-constrs={lower-limit=0, upper-limit=255, scale-constr{lower-limit=255, upper-limit=255}}  # Qualifier_Service_Lenkmoment_Lenkmoment_Fahrer_Stellglied / Qualifier_service_steering-moment_steering-moment_driver_actuator
  data constr ST_DIAG_OBD_MUX_IMME: data-constr-rule{phys-constrs={lower-limit=4, upper-limit=60, unit=no_unit}, internal-constrs={lower-limit=0, upper-limit=63, scale-constr{lower-limit=63, upper-limit=63}}}  # Status_Diagnose_OBD_Multiplexer_Aktuell / status_diagnosis_OBD_multiplexer_immediate
  data constr QU_VYAW_VEH: data-constr-rule=internal-constrs={lower-limit=0, upper-limit=15, scale-constr{lower-limit=15, upper-limit=15}}  # Qualifier_Giergeschwindigkeit_Fahrzeug / Qualifier_yaw-velocity_vehicle
  data constr ST_ILK_ERRM_FZM: data-constr-rule=internal-constrs={lower-limit=0, upper-limit=3, scale-constr{lower-limit=3, upper-limit=3}}  # Status_Sperre_Fehlerspeicher_FZM / status_interlock_error-memory_FZM
  range CRC_V_VEH: phys 0..255, raw 0..255  # CRC_Geschwindigkeit_Fahrzeug / CRC_speed_vehicle
  data constr QU_FN_VIB_EPS: data-constr-rule=internal-constrs={lower-limit=0, upper-limit=15, scale-constr{lower-limit=15, upper-limit=15}}  # Qualifier_Funktion_Vibration_EPS / Qualifier_function_vibration_EPS
  data constr QU_AVL_STMOM_DV_ACT: data-constr-rule=internal-constrs={lower-limit=0, upper-limit=15, scale-constr{lower-limit=15, upper-limit=15}}  # Qualifier_Ist_Lenkmoment_Fahrer_Stellglied / Qualifier_actual-value_steering-moment_driver_actuator
  data constr FACT_MO_STE_SO_DXP: data-constr-rule{phys-constrs={lower-limit=0, upper-limit=5, unit=no_unit}, internal-constrs={lower-limit=0, upper-limit=255, scale-constr{lower-limit=255, upper-limit=255}}}  # Faktor_Modifikation_Lenkung_Servo_Fahrerlebnis / factor_modification_steering_servo_driving-experience
  data constr CTR_BS_PRTNT: data-constr-rule=internal-constrs={lower-limit=0, upper-limit=15, scale-constr{lower-limit=15, upper-limit=15}}  # Steuerung_Basis_Teilnetze / control_base_partial-networks
  data constr ST_ENERG_FZM: data-constr-rule=internal-constrs={lower-limit=0, upper-limit=15, scale-constr{lower-limit=15, upper-limit=15}}  # Status_Energie_FZM / status_Energy_FZM
  data constr CTR_ERRM_BN_U: data-constr-rule=internal-constrs={lower-limit=0, upper-limit=63, scale-constr{lower-limit=63, upper-limit=63}}  # Steuerung_Fehlerspeicher_Bordnetz_Spannung / control_error-memory_Bordnetz_voltage
  data constr TAR_STMOM_DV_ACT: data-constr-rule{phys-constrs={lower-limit=-12, upper-limit=12, unit=Nm}, internal-constrs={lower-limit=0, upper-limit=4095, scale-constr{lower-limit=4095, upper-limit=4095}}}  # Soll_Lenkmoment_Fahrer_Stellglied / target_steering-moment_driver_actuator
  data constr ENERG_AVAI_ARS: data-constr-rule{phys-constrs={lower-limit=0, upper-limit=100, unit=%}, internal-constrs={lower-limit=0, upper-limit=255, scale-constr{lower-limit=255, upper-limit=255}}}  # Energie_Verfügbarkeit_ARS / Energy_availibility_ARS
  data constr UN_PO_EPS: data-constr-rule=internal-constrs={lower-limit=0, upper-limit=3, scale-constr{lower-limit=3, upper-limit=3}}  # Einheit_Position_EPS / unit-of-measurement_position_EPS
  data constr ST_CENG_DRV: data-constr-rule=internal-constrs={lower-limit=0, upper-limit=15, scale-constr{lower-limit=15, upper-limit=15}}  # Status_Verbrennungsmotor_Antrieb / status_combustion-engine_drive
  data constr ACLNY_COG_ERR_AMP: data-constr-rule{phys-constrs={lower-limit=0, upper-limit=20, unit=m/s²}, internal-constrs={lower-limit=0, upper-limit=4095, scale-constr{lower-limit=4095, upper-limit=4095}}}  # Querbeschleunigung_Schwerpunkt_Fehler_Amplitude / lateral-acceleration_centre-of-gravity_error_amplidue
  data constr QU_SUM_AVL_I_DRDY_SFY: data-constr-rule=internal-constrs={lower-limit=0, upper-limit=15, scale-constr{lower-limit=15, upper-limit=15}}  # Qualifier_Summe_Ist_Strom_Fahrdynamik_Sicherheit / Qualifier_sum_actual-value_current_driving-dynamics_safety
  data constr TOT_STR_EPS: data-constr-rule{phys-constrs={lower-limit=0, upper-limit=50, unit=no_unit}, internal-constrs={lower-limit=0, upper-limit=4095, scale-constr{lower-limit=4095, upper-limit=4095}}}  # Gesamt_Lenkübersetzung_EPS / total_steering-ratio_EPS
  data constr NO_VECH_3: data-constr-rule=internal-constrs={lower-limit=0, upper-limit=255, scale-constr{lower-limit=255, upper-limit=255}}  # Nummer_Fahrgestell_3 / number_vehicle-chassis_3
  data constr QU_ST_CON_VEH: data-constr-rule=internal-constrs={lower-limit=0, upper-limit=15, scale-constr{lower-limit=15, upper-limit=15}}  # Qualifier_Status_Zustand_Fahrzeug / Qualifier_status_condition_vehicle
  data constr QU_FN_ENSU_SFY: data-constr-rule=internal-constrs={lower-limit=0, upper-limit=255, scale-constr{lower-limit=255, upper-limit=255}}  # Qualifier_Funktion_Energieversorgung_Sicherheit / Qualifier_function_energy-supply_safety
  data constr NO_VECH_2: data-constr-rule=internal-constrs={lower-limit=0, upper-limit=255, scale-constr{lower-limit=255, upper-limit=255}}  # Nummer_Fahrgestell_2 / number_vehicle-chassis_2
  data constr SSS_IDENT: data-constr-rule=internal-constrs={lower-limit=0, upper-limit=255, scale-constr{lower-limit=255, upper-limit=255}}  # SSS_Identifikation / SSS_identification
  data constr QU_AVL_RPM_WHL: data-constr-rule=internal-constrs={lower-limit=0, upper-limit=15, scale-constr{lower-limit=15, upper-limit=15}}  # Qualifier_Ist_Drehzahl_Rad / Qualifier_actual-value_RPM_wheel
  data constr FACT_ASS_STMOM_FTAX: data-constr-rule{phys-constrs={lower-limit=1, upper-limit=1.9921875, unit=no_unit}, internal-constrs={lower-limit=0, upper-limit=255, scale-constr{lower-limit=255, upper-limit=255}}}  # Faktor_Unterstützung_Lenkmoment_Vorderachse / factor_assistance_steering-moment_front-axle
  data constr QU_AVL_PINA_EPS: data-constr-rule=internal-constrs={lower-limit=0, upper-limit=15, scale-constr{lower-limit=15, upper-limit=15}}  # Qualifier_Ist_Ritzelwinkel_EPS / Qualifier_actual-value_pinion-angle_EPS
  data constr QU_V_VEH_COG: data-constr-rule=internal-constrs={lower-limit=0, upper-limit=15, scale-constr{lower-limit=15, upper-limit=15}}  # Qualifier_Geschwindigkeit_Fahrzeug_Schwerpunkt / Qualifier_speed_vehicle_centre-of-gravity
  data constr CTR_DEAC_EPS_FNS: data-constr-rule=internal-constrs={lower-limit=0, upper-limit=15, scale-constr{lower-limit=15, upper-limit=15}}  # Steuerung_Deaktivierung_EPS_Funktionen / control_deactivation_EPS_functions
  data constr QU_DGR_AISP_ENERG: data-constr-rule=internal-constrs={lower-limit=0, upper-limit=15, scale-constr{lower-limit=15, upper-limit=15}}  # Qualifier_Degradation_Luftfeder_Energie / Qualifier_degradation_air-spring_Energy
  data constr TRGG_ENGTORQ_EPS: data-constr-rule{phys-constrs={lower-limit=-10, upper-limit=10, unit=Nm}, internal-constrs={lower-limit=0, upper-limit=4095, scale-constr{lower-limit=4095, upper-limit=4095}}}  # Ansteuerung_Motormoment_EPS / triggering_engine-torque_EPS
  data constr IDX_TORQ_SEN: data-constr-rule=internal-constrs={lower-limit=0, upper-limit=3, scale-constr{lower-limit=3, upper-limit=3}}  # Index_Drehmoment_Sensor / index_torque_sensor
  data constr UI_32_noIniVal_noDflVal_4294967295_1_0_noEnc_hasRng: data-constr-rule{phys-constrs={lower-limit=0, upper-limit=4294967294, unit=s}, internal-constrs={lower-limit=0, upper-limit=4294967295, scale-constr{lower-limit=4294967295, upper-limit=4294967295}}}
  data constr CTR_WARN_DIR_VIB_EPS: data-constr-rule=internal-constrs={lower-limit=0, upper-limit=3, scale-constr{lower-limit=3, upper-limit=3}}  # Steuerung_Warnung_Richtung_Vibration_EPS / control_warning_direction_vibration_EPS
  data constr COU_BS_RESP: data-constr-rule{phys-constrs={lower-limit=0, upper-limit=16777214, unit=no_unit}, internal-constrs={lower-limit=0, upper-limit=16777215, scale-constr{lower-limit=16777215, upper-limit=16777215}}}  # Zähler_Basis_Response / counter_base_response
  data constr V_VEH_COG: data-constr-rule{phys-constrs={lower-limit=0, upper-limit=350, unit=km/h}, internal-constrs={lower-limit=0, upper-limit=65535, scale-constr{lower-limit=65535, upper-limit=65535}}}  # Geschwindigkeit_Fahrzeug_Schwerpunkt / speed_vehicle_centre-of-gravity
  data constr SSV_IDENT: data-constr-rule=internal-constrs={lower-limit=0, upper-limit=255, scale-constr{lower-limit=255, upper-limit=255}}  # SSV_Identifikation / SSV_identification
  data constr ST_ENERG_SUPY: data-constr-rule=internal-constrs={lower-limit=0, upper-limit=255, scale-constr{lower-limit=255, upper-limit=255}}  # Status_Energie_Versorgung / status_Energy_supply
  data constr ST_V_VEH_NSS: data-constr-rule=internal-constrs={lower-limit=0, upper-limit=15, scale-constr{lower-limit=15, upper-limit=15}}  # Status_Geschwindigkeit_Fahrzeug_Stillstandsnah / status_speed_vehicle_near-standstill
  data constr QU_FN_EST: data-constr-rule=internal-constrs={lower-limit=0, upper-limit=255, scale-constr{lower-limit=255, upper-limit=255}}  # Qualifier_Funktion_Elektrische-Lenkung / Qualifier_function_electrical-steering
  data constr AVL_PINA_IDX_ICM: data-constr-rule{phys-constrs={lower-limit=-1439.9560546875, upper-limit=1439.9560546875, unit=no_unit}, internal-constrs={lower-limit=0, upper-limit=65535, scale-constr{lower-limit=65535, upper-limit=65535}}}  # Ist_Ritzelwinkel_Index_ICM / actual-value_pinion-angle_index_ICM
  data constr CTR_WARN_PTRN_VIB_EPS: data-constr-rule=internal-constrs={lower-limit=0, upper-limit=15, scale-constr{lower-limit=15, upper-limit=15}}  # Steuerung_Warnung_Muster_Vibration_EPS / control_warning_pattern_vibration_EPS
  data constr QU_TAR_QTA_STMOM_DV: data-constr-rule=internal-constrs={lower-limit=0, upper-limit=15, scale-constr{lower-limit=15, upper-limit=15}}  # Qualifier_Soll_Anteil_Lenkmoment_Fahrer / Qualifier_target_quota_steering-moment_driver
  data constr ID_FN_INQY: data-constr-rule=internal-constrs={lower-limit=0, upper-limit=65535, scale-constr{lower-limit=65535, upper-limit=65535}}  # ID_Funktion_Anfrage / ID_function_inquiry
  data constr NO_VECH_5: data-constr-rule=internal-constrs={lower-limit=0, upper-limit=255, scale-constr{lower-limit=255, upper-limit=255}}  # Nummer_Fahrgestell_5 / number_vehicle-chassis_5
  data constr ST_IDC_CC_EPS: data-constr-rule=internal-constrs={lower-limit=0, upper-limit=3, scale-constr{lower-limit=3, upper-limit=3}}  # Status_Blinken_Checkcontrol_EPS / status_indicate-direction_check-control_EPS
  data constr QU_TAR_DMPNG_ADDON_STMOM_FTAX: data-constr-rule=internal-constrs={lower-limit=0, upper-limit=15, scale-constr{lower-limit=15, upper-limit=15}}  # Qualifier_Soll_Dämpfung_Zusatz_Lenkmoment_Vorderachse / Qualifier_target_damping_add-on_steering-moment_front-axle
  data constr ST_CON_VEH: data-constr-rule=internal-constrs={lower-limit=0, upper-limit=15, scale-constr{lower-limit=15, upper-limit=15}}  # Status_Zustand_Fahrzeug / status_condition_vehicle
  data constr FKTN_PRTNT: data-constr-rule=internal-constrs={lower-limit=0, upper-limit=4294967295, scale-constr{lower-limit=4294967295, upper-limit=4294967295}}  # Funktionale_Teilnetze / functional_partial-networks
  data constr DIAG_ST_OBD: data-constr-rule=internal-constrs={lower-limit=0, upper-limit=63, scale-constr{lower-limit=63, upper-limit=63}}  # Diagnose_Status_OBD / diagnosis_status_OBD
  data constr UI_8_noIniVal_noDflVal_255_0_50s_MI_40_noEnc_hasRng: data-constr-rule{phys-constrs={lower-limit=-40, upper-limit=85, unit=°C}, internal-constrs={lower-limit=0, upper-limit=255, scale-constr{lower-limit=255, upper-limit=255}}}  # UI_8_noIniVal_noDflVal_255_0.50s_Minus_40_noEnc_hasRng / UI_8_noIniVal_noDflVal_255_0.50s_minus_40_noEnc_hasRng
  data constr NO_VECH_4: data-constr-rule=internal-constrs={lower-limit=0, upper-limit=255, scale-constr{lower-limit=255, upper-limit=255}}  # Nummer_Fahrgestell_4 / number_vehicle-chassis_4
  data constr ST_OFFS_QUAD_PINA_EPS: data-constr-rule=internal-constrs={lower-limit=0, upper-limit=15, scale-constr{lower-limit=15, upper-limit=15}}  # Status_Offset_Quadrant_Ritzelwinkel_EPS / status_offset_quadrant_pinion-angle_EPS
  data constr QU_AVL_FORC_GRD: data-constr-rule=internal-constrs={lower-limit=0, upper-limit=15, scale-constr{lower-limit=15, upper-limit=15}}  # Qualifier_Ist_Kraft_Zahnstange / Qualifier_actual-value_force_gear-rod
  data constr RQ_RST_OBD_DIAG: data-constr-rule=internal-constrs={lower-limit=0, upper-limit=3, scale-constr{lower-limit=3, upper-limit=3}}  # Anforderung_Reset_OBD_Diagnose / request_reset_OBD_diagnosis
  data constr CTR_WARN_ILVL_VIB_EPS: data-constr-rule=internal-constrs={lower-limit=0, upper-limit=15, scale-constr{lower-limit=15, upper-limit=15}}  # Steuerung_Warnung_Intensitätsstufe_Vibration_EPS / control_warning_intensity-level_vibration_EPS
  data constr SU_CLU_STMOM_SFE_DXP: data-constr-rule=internal-constrs={lower-limit=0, upper-limit=15, scale-constr{lower-limit=15, upper-limit=15}}  # Konfiguration_Cluster_Lenkmoment_Lenkgefühl_Fahrerlebnis / setup_cluster_steering-moment_steering-feel_driving-experience
  data constr RQ_STG_EFAN: data-constr-rule=internal-constrs={lower-limit=0, upper-limit=15, scale-constr{lower-limit=15, upper-limit=15}}  # Anforderung_Stufe_Elektrolüfter / request_stage_electric-fan
  data constr AVL_PINA_EPS: data-constr-rule{phys-constrs={lower-limit=-1439.9560546875, upper-limit=1439.9560546875, unit=no_unit}, internal-constrs={lower-limit=0, upper-limit=65535, scale-constr{lower-limit=65535, upper-limit=65535}}}  # Ist_Ritzelwinkel_EPS / actual-value_pinion-angle_EPS
  data constr ID_TEMP_CPO_HET_MNG: data-constr-rule=internal-constrs={lower-limit=0, upper-limit=15, scale-constr{lower-limit=15, upper-limit=15}}  # ID_Temperatur_Komponente_Wärme_Management / ID_temperature_component_heat_management
package /BMW/SystemDescription/Pdus
  pdu ANFRAGE: length=8, minimum-delay=0.5, transmission-mode-true-timing=event-controlled-timing=number-of-repetitions=0, unused-bit-pattern=255  # Anfrage / Inquiry | Diese PDU löst die bis einschließlich SP2015 gültige Version der gleichnamigen PDU ab. Ab SP2018 darf nur noch diese Version der PDU verwendet werden. Mit dem Anfrage-Dienst kann eine Nachricht, die als anfragbar definiert ist, angefragt werden.
    signal ANFRAGE_ID2: start 0, 8 bit, little-endian, init-value=SWITCH_CODE:1, base-type=uint8, transfer-property=PENDING, to EPS
    signal ID_FN_INQY: start 8, 16 bit, little-endian, base-type=uint16, compu-method=CompuMethods/ID_FN_INQY, data-constr=ID_FN_INQY, invalid-value=65535, to EPS  # ID_Funktion_Anfrage / ID_function_inquiry | LogicalInterface:BMW.INFRASTRUCTURE.COMMUNICATION.InquiryService[external]@Infrastruktur; Dieses Signal löst die bis einschließlich SP2015 gültige Version des gleichnamigen Signales ab. Ab SP2018 darf nur noch diese Version des Signals verwendet werden. Damit wird die in der alten Signalversion existierende Ausnahme bezüglich der Byteorder aufgelöst. Die Darstellung der Signal-Inhalte auf dem Bus wird dadurch jedoch nicht verändert – um dies zu erreichen wurden High-Byte und Low-Byte der Kodierungen vertauscht. Achtung: Sollte es sich sender- oder empfängerseitig um ein reines SP2015-Gleichteil handeln, das demnach die Versendung oder den Empfang des Signals ID_Funktion_Anfrage unverändert zu SP2015 umsetzt, so ist die hier spezifizierte Version des Signals ungültig! Für diese Gleichteile ist die für SP2015 spezifizierte Version dieses Signals gültig. Dieses Signal enthält in der Regel den 11-Bit CAN-Identifier der angefragten Nachricht. Es kann allerdings Abweichungen von dieser Regel geben, z.B. - im Fall von Zuordnungen mehrerer anfragbarer Frames zu einer CAN-ID - im Fall busspezifischer unterschiedlicher CAN-IDs des angefragten Frames - im Fall von Anfragen auf Nicht-CAN Bussen (z.B. FlexRay) - im Fall von 29-Bit CAN-IDs der angefragten Frames Es sind nur die Codierungen erlaubt, zu denen anfragbare PDUs definiert sind. / This signal contains the identifier of the message inquired. Only the identifiers are allowed which are defined as addressable messages. N.B. As regards byte orderings, this signal constitutes an exception because the inquired identifier must be transmitted in Engineola format. In the definite case this means that Byte 1 contains the high byte and Byte 2 the low byte of the desired identifiers [Byte 1, Bit 0: 2^8, Byte 1, Bit 7: 2^15 (= MSEC.B) and Byte 2, Bit 0: 2^0 (= LSB), Byte 2, Bit 7: 2^7]
  pdu DBG_EPS_BS_MOD_58_BYTE: length=58, transmission-mode-true-timing=cyclic-timing=time-period={tolerance=absolute-tolerance=0.002, value=0.02}, unused-bit-pattern=255  # Debug EPS Modus Basis 58 Byte | Diese PDU enthält die 57-Byte langen Debug Information. Die Signale in dieser PDU können durch den Fachbereich eigenständig angepasst werden.
    signal DBG_EPS_BS_MOD_58_BYTE_CHOV_DBG_MOD_EPS: start 0, 8 bit, little-endian, init-value=SWITCH_CODE:1, base-type=uint8, transfer-property=PENDING
    signal DBG_EPS_MOD_BS_58_BYTE: start 8, 8 bit, little-endian, base-type=uint8, compu-method=CompuMethods/DBG_8Bit, data-constr=DataConstrs/DBG_8Bit  # Debug_EPS_Modus_Basis_58_Byte / debug_EPS_mode_base_58_byte | LogicalInterface:BMW.INFRASTRUCTURE.DIAGNOSIS.Debug[internal]@Infrastruktur; Dummy-Signal. Kann beliebig geändert werden.
  pdu DBG_EPS_MOD_EXT_120_BYTE: length=58, transmission-mode-true-timing=cyclic-timing=time-period={tolerance=absolute-tolerance=0.0005, value=0.005}, unused-bit-pattern=255  # Debug EPS Modus Erweitert 120 Byte | Diese PDU enthält die 119-Byte langen Debug Information. Bei Verwendung dieses Modes muss die Frame Länge vom Fachbereich auf 120-Bytes angepasst werden. Die Signale in dieser PDU können durch den Fachbereich eigenständig angepasst werden.
    signal DBG_EPS_MOD_EXT_120_BYTE_CHOV_DBG_MOD_EPS: start 0, 8 bit, little-endian, init-value=SWITCH_CODE:2, base-type=uint8, transfer-property=PENDING
    signal DBG_EPS_MOD_EXT_120_BYTE: start 8, 8 bit, little-endian, base-type=uint8, compu-method=CompuMethods/DBG_8Bit, data-constr=DataConstrs/DBG_8Bit  # Debug_EPS_Modus_Erweitert_120_Byte / debug_EPS_mode_extended_120_byte | LogicalInterface:BMW.INFRASTRUCTURE.DIAGNOSIS.Debug[internal]@Infrastruktur; Dummy-Signal. Kann beliebig geändert werden.
  pdu RQ_STG_EFAN:  # Anforderung Wärmemanagement / Request Stage Electric-Fan
    length=8
    transmission-mode-true-timing=cyclic-timing={time-period={tolerance=absolute-tolerance=0.1, value=1}, "Um sicherzustellen, dass das Ende der zyklischen Versendung erkannt wird, muss die Versendung der Stoppnachricht (Signal Anforderung_Steuerung_Elektrolüfter = 0) insgesamt 3-mal mit einem Wiederholzyklus von t=160 ms erfolgen (Details in der Spezifikation: Erweiterung der ereignisgesteuerten Auslösebedingungen). Zusätzlich erfolgt eine zyklische Versendung der Nachricht, wenn die Signale Temperatur_Komponente_Wärmemanagement und ID_Temperatur_Komponente_Wärmemanagement befüllt sind."}
    unused-bit-pattern=255
    signal RQ_STG_EFAN_ID2: start 0, 8 bit, little-endian, init-value=SWITCH_CODE:21, base-type=uint8, transfer-property=PENDING
    signal ID_FN_RQ_STG_EFAN: start 8, 8 bit, little-endian, base-type=uint8, compu-method=CompuMethods/ID_FN_RQ_STG_EFAN, data-constr=ID_FN_RQ_STG_EFAN, invalid-value=255  # ID_Funktion_Anforderung_Stufe_Elektrolüfter / ID_function_request_stage_electric-fan | LogicalInterface:BMW.POWERTRAIN.ENGINE.COMBUSTION.HeatManagement[internal]@Fahren; Dieses Signal gibt den Anforderer der gewünschten Elektrolüfterstufe an.
    signal RQ_STG_EFAN: start 16, 4 bit, little-endian, base-type=uint8, compu-method=CompuMethods/RQ_STG_EFAN, data-constr=RQ_STG_EFAN, invalid-value=15  # Anforderung_Stufe_Elektrolüfter / request_stage_electric-fan | LogicalInterface:BMW.POWERTRAIN.ENGINE.COMBUSTION.HeatManagement[internal]@Fahren; Die Stufen werden als Luftmassenstrom interpretiert. Die Stufe 14 entspricht der maximalen Luftmassenstromanforderung.
    signal ID_TEMP_CPO_HET_MNG: start 20, 4 bit, little-endian, base-type=uint8, compu-method=CompuMethods/ID_TEMP_CPO_HET_MNG, data-constr=ID_TEMP_CPO_HET_MNG, invalid-value=15  # ID_Temperatur_Komponente_Wärme_Management / ID_temperature_component_heat_management | LogicalInterface:BMW.POWERTRAIN.ENGINE.COMBUSTION.HeatManagement[internal]@Fahren; Dieses Signal gibt die Komponente für das Temperatursignal für das Motorwärmemanagement an. Dieses Signal wird in 444, F15-F16, F25 und F25_ab_PU12-07 nicht ausgewertet.
    signal TEMP_CPO_HET_MNG: start 24, 8 bit, little-endian, base-type=uint8, compu-method=CompuMethods/TEMP_CPO_HET_MNG, data-constr=DataConstrs/TEMP_CPO_HET_MNG, invalid-value=255  # Temperatur_Komponente_Wärme_Management / temperature_component_heat_management | LogicalInterface:BMW.POWERTRAIN.ENGINE.COMBUSTION.HeatManagement[internal]@Fahren; Komponententemperatur für das Motorwärmemanagement Dieses Signal wird in 444, F15-F16, F25 und F25_ab_PU12-07 nicht ausgewertet.
  pdu SECU_CHAL: length=8, minimum-delay=0.05, transmission-mode-true-timing=event-controlled-timing=number-of-repetitions=0, unused-bit-pattern=255  # Sicher Challenge | $(AUTOSAR; SIGNALGROUP)
    signal SECU_CHAL_ID2: start 0, 8 bit, little-endian, init-value=SWITCH_CODE:248, base-type=uint8, transfer-property=PENDING
    signal SSV_IDENT_CHAL: start 8, 8 bit, little-endian, base-type=uint8, compu-method=CompuMethods/SSV_IDENT, data-constr=SSV_IDENT, invalid-value=255  # SSV_Identifikation_Challenge / SSV_identification_challenge | LogicalInterface:BMW.INFRASTRUCTURE.COMMUNICATION.SecureChallengeResponse[internal]@Infrastruktur;
    signal SSS_IDENT_CHAL: start 16, 8 bit, little-endian, base-type=uint8, compu-method=CompuMethods/SSS_IDENT, data-constr=SSS_IDENT, invalid-value=255  # SSS_Identifikation_Challenge / SSS_identification_challenge | LogicalInterface:BMW.INFRASTRUCTURE.COMMUNICATION.SecureChallengeResponse[internal]@Infrastruktur;
    signal SECU_CHAL: start 24, 40 bit, little-endian, base-type=uint64, compu-method=CompuMethods/SECU_CHAL, data-constr=DataConstrs/SECU_CHAL, invalid-value=1099511627775  # Sicher_Challenge / secure_challenge | LogicalInterface:BMW.INFRASTRUCTURE.COMMUNICATION.SecureChallengeResponse[internal]@Infrastruktur;
    mapping signalGrp_SECU_CHAL_grpMap: i-signal-group=signalGrp_SECU_CHAL
  pdu SECU_RESP: length=8, minimum-delay=0.05, transmission-mode-true-timing=event-controlled-timing=number-of-repetitions=0, unused-bit-pattern=255  # Sicher Response | $(AUTOSAR; SIGNALGROUP)
    signal SECU_RESP_ID2: start 0, 8 bit, little-endian, init-value=SWITCH_CODE:247, base-type=uint8, transfer-property=PENDING, to EPS
    signal SSV_IDENT_RESP: start 8, 8 bit, little-endian, base-type=uint8, compu-method=CompuMethods/SSV_IDENT, data-constr=SSV_IDENT, invalid-value=255  # SSV_Identifikation_Response / SSV_identification_response | LogicalInterface:BMW.INFRASTRUCTURE.COMMUNICATION.SecureChallengeResponse[internal]@Infrastruktur;
    signal COU_BS_RESP: start 16, 24 bit, little-endian, base-type=uint32, compu-method=CompuMethods/COU_BS_RESP, data-constr=DataConstrs/COU_BS_RESP, invalid-value=16777215  # Zähler_Basis_Response / counter_base_response | LogicalInterface:BMW.INFRASTRUCTURE.COMMUNICATION.SecureChallengeResponse[internal]@Infrastruktur;
    signal STU_RESP: start 40, 24 bit, little-endian, base-type=uint32, compu-method=CompuMethods/STU_RESP, data-constr=DataConstrs/STU_RESP, invalid-value=16777215  # Signatur_Response / signature_response | LogicalInterface:BMW.INFRASTRUCTURE.COMMUNICATION.SecureChallengeResponse[internal]@Infrastruktur;
    mapping signalGrp_SECU_RESP_grpMap: i-signal-group=signalGrp_SECU_RESP
package /BMW/SystemDescription/ISignalGroups
  23 x i signal group:
    e2eGrp_ACLNY_MASSCNTR: i-signal=[ISignals/CRC_ACLNY_COG, ISignals/ALIV_ACLNY_COG, ISignals/ACLNY_MASSCNTR_dummy_12_15, ISignals/ACLNY_COG, ISignals/ACLNY_COG_ERR_AMP, ISignals/QU_ACLNY_COG], system-signal-group=e2eGrp_ACLNY_MASSCNTR
    e2eGrp_AVL_FORC_GRD: i-signal=[ISignals/CRC_AVL_FORC_GRD, ISignals/ALIV_AVL_FORC_GRD, ISignals/AVL_FORC_GRD_dummy_12_15, ISignals/AVL_FORC_GRD, ISignals/QU_AVL_FORC_GRD, ISignals/AVL_PWR_EL_EPS_COOD], system-signal-group=e2eGrp_AVL_FORC_GRD
    e2eGrp_AVL_PO_EPS: i-signal=[ISignals/CRC_AVL_PO_EPS, ISignals/ALIV_AVL_PO_EPS, ISignals/QU_AVL_PO_EPS, ISignals/AVL_PO_EPS, ISignals/AVL_PO_IDX_EPS, ISignals/OFFS_GRD_MID_EPS, ISignals/IDX_TORQ_SEN, ISignals/UN_PO_EPS], system-signal-group=e2eGrp_AVL_PO_EPS
    e2eGrp_AVL_RPM_WHL: i-signal=[ISignals/CRC_AVL_RPM_WHL, ISignals/ALIV_AVL_RPM_WHL, ISignals/AVL_RPM_WHL_dummy_12_15, ISignals/AVL_RPM_WHL_RLH, ISignals/AVL_RPM_WHL_RRH, ISignals/AVL_RPM_WHL_FLH, ISignals/AVL_RPM_WHL_FRH, ISignals/QU_AVL_RPM_WHL_RLH, ISignals/QU_AVL_RPM_WHL_RRH, ISignals/QU_AVL_RPM_WHL_FLH, ISignals/QU_AVL_RPM_WHL_FRH], system-signal-group=e2eGrp_AVL_RPM_WHL
    e2eGrp_AVL_STMOM_DV_ACT: i-signal=[ISignals/CRC_AVL_STMOM_DV_ACT, ISignals/ALIV_AVL_STMOM_DV_ACT, ISignals/AVL_STMOM_DV_ACT_dummy_12_15, ISignals/AVL_STMOM_DV_ACT, ISignals/QU_AVL_STMOM_DV_ACT], system-signal-group=e2eGrp_AVL_STMOM_DV_ACT
    e2eGrp_CON_VEH: i-signal=[ISignals/CRC_CON_VEH, ISignals/ALIV_CON_VEH, ISignals/CTR_BS_PRTNT, ISignals/CTR_FKTN_PRTNT, ISignals/ST_CON_VEH, ISignals/QU_ST_CON_VEH, ISignals/CON_VEH_dummy_56_63], system-signal-group=e2eGrp_CON_VEH
    e2eGrp_DISP_CC_EPS: i-signal=[ISignals/CRC_DISP_CC_EPS, ISignals/ALIV_DISP_CC_EPS, ISignals/CHL_DISP_CC_EPS, ISignals/NO_CC_EPS, ISignals/ST_CC_EPS, ISignals/TRANF_CC_EPS, ISignals/ST_IDC_CC_EPS], system-signal-group=e2eGrp_DISP_CC_EPS
    e2eGrp_DT_EST: i-signal=[ISignals/CRC_DT_EST, ISignals/ALIV_DT_EST, ISignals/DT_EST_dummy_12_15, ISignals/DT_EST_dummy_16_47, ISignals/AVL_I_ACT_EST, ISignals/ST_CULI_EST, ISignals/QU_AVL_I_ACT_EST, ISignals/DT_EST_dummy_64_95, ISignals/DT_EST_dummy_96_127], system-signal-group=e2eGrp_DT_EST
    e2eGrp_ENERG_DGR_DRDY: i-signal=[ISignals/MAX_I_SPEC_EPS, ISignals/RQ_CULI_EST_SFY, ENERG_DGR_DRDY_dummy_12_15, MAX_I_SPEC_BAX_STE, MAX_I_LD_SPEC_ARS, MAX_I_RECUP_SPEC_ARS, ENERG_AVAI_ARS, QU_DGR_AISP_ENERG, ALIV_ENERG_DGR_DRDY, CRC_ENERG_DGR_DRDY], system-signal-group=e2eGrp_ENERG_DGR_DRDY
    e2eGrp_ENSU_SFY: i-signal=[ISignals/CRC_ENSU_SFY, ISignals/ALIV_ENSU_SFY, ISignals/CHL_ENSU_SFY, ISignals/QU_FN_ENSU_SFY, ISignals/RQ_CULI, ISignals/ENSU_SFY_dummy_28_31, ISignals/ENSU_SFY_dummy_32_63], system-signal-group=e2eGrp_ENSU_SFY
    signalGrp_FAHRGESTELLNUMMER: i-signal=[ISignals/NO_VECH_1, ISignals/NO_VECH_2, ISignals/NO_VECH_3, ISignals/NO_VECH_4, ISignals/NO_VECH_5, ISignals/NO_VECH_6, ISignals/NO_VECH_7], system-signal-group=signalGrp_FAHRGESTELLNUMMER
    e2eGrp_OFFS_QUAD_EPS: i-signal=[ISignals/CRC_OFFS_QUAD_EPS, ISignals/ALIV_OFFS_QUAD_EPS, ISignals/ST_OFFS_QUAD_EPS, ISignals/OFFS_QUAD_RTR_EPS, ISignals/AVL_PO_IDX_ICM], system-signal-group=e2eGrp_OFFS_QUAD_EPS
    signalGrp_SECU_CHAL: i-signal=[ISignals/SSV_IDENT_CHAL, ISignals/SSS_IDENT_CHAL, ISignals/SECU_CHAL], system-signal-group=signalGrp_SECU_CHAL
    signalGrp_SECU_FAHRGESTELLNUMMER: i-signal=ISignals/STU_8_BYTE, system-signal-group=signalGrp_SECU_FAHRGESTELLNUMMER
    signalGrp_SECU_RESP: i-signal=[ISignals/SSV_IDENT_RESP, ISignals/COU_BS_RESP, ISignals/STU_RESP], system-signal-group=signalGrp_SECU_RESP
    signalGrp_ST_DIAG_OBD_3_DRDY: i-signal=[ISignals/ALIV_ST_DIAG_OBD_3_DRDY, ISignals/ST_DIAG_OBD_3_DRDY_MAX_MUX, ISignals/ST_DIAG_OBD_3_DRDY_IMME_MUX, ISignals/DIAG_ST_OBD_3_DRDY_1, ISignals/DIAG_ST_OBD_3_DRDY_2, ISignals/DIAG_ST_OBD_3_DRDY_3, ISignals/DIAG_ST_OBD_3_DRDY_4, ISignals/DIAG_ST_OBD_3_DRDY_5, ISignals/DIAG_ST_OBD_3_DRDY_6, ISignals/DIAG_ST_OBD_3_DRDY_7, ISignals/DIAG_ST_OBD_3_DRDY_8], system-signal-group=signalGrp_ST_DIAG_OBD_3_DRDY
    e2eGrp_ST_EST: i-signal=[ISignals/CRC_ST_EST_FTAX, ISignals/ALIV_ST_EST_FTAX, ISignals/QU_FN_VIB_EPS, ISignals/ST_EST_dummy_16_23, ISignals/QU_SER_STMOM_DV_ACT, ISignals/QU_FN_EST], system-signal-group=e2eGrp_ST_EST
    e2eGrp_SU_EPS: i-signal=[ISignals/TOT_STR_EPS, ISignals/UN_TOT_STR_EPS, ISignals/SU_EPS_dummy_14_19, ISignals/SU_EPS_dummy_20_51, ISignals/ALIV_SU_EPS, ISignals/CRC_SU_EPS], system-signal-group=e2eGrp_SU_EPS
    e2eGrp_TAR_ESTP_VIRT_FTAX: i-signal=[ISignals/CRC_TAR_ESTP_VIRT_FTAX, ISignals/ALIV_TAR_ESTP_VIRT_FTAX, ISignals/TAR_ESTP_VIRT_FTAX_dummy_12_31, ISignals/ACTVN_FN_ESTP_VIRT_FTAX, ISignals/TAR_ESTP_VIRT_FTAX_dummy_36_63], system-signal-group=e2eGrp_TAR_ESTP_VIRT_FTAX
    e2eGrp_TAR_QTA_STRMOM_DV: i-signal=[ISignals/CRC_TAR_QTA_STMOM_DV, ISignals/ALIV_TAR_QTA_STMOM_DV, ISignals/TAR_QTA_STRMOM_DV_dummy_12_15, ISignals/TAR_QTA_STMOM_DV, ISignals/QU_TAR_QTA_STMOM_DV, ISignals/FACT_CTRR_STMOM_FTAX, ISignals/FACT_DMPNG_STMOM_FTAX, ISignals/FACT_ASS_STMOM_FTAX, ISignals/QU_TAR_FACT_STMOM_FTAX, ISignals/CTR_DEAC_EPS_FNS], system-signal-group=e2eGrp_TAR_QTA_STRMOM_DV
    e2eGrp_TAR_STMOM_DV_ACT: i-signal=[ISignals/CRC_TAR_STMOM_DV_ACT, ISignals/ALIV_TAR_STMOM_DV_ACT, ISignals/TAR_STMOM_DV_ACT_dummy_12_15, ISignals/TAR_STMOM_DV_ACT, ISignals/QU_TAR_STMOM_DV_ACT, ISignals/TAR_STMOM_DV_ACT_dummy_32_51, ISignals/QU_TAR_DMPNG_ADDON_STMOM_FTAX, ISignals/FACT_DMPNG_ADDON_STMOM_FTAX], system-signal-group=e2eGrp_TAR_STMOM_DV_ACT
    e2eGrp_VYAW_VEH: i-signal=[ISignals/CRC_VYAW_VEH, ISignals/ALIV_VYAW_VEH, ISignals/VYAW_VEH_dummy_12_15, ISignals/VYAW_VEH, ISignals/VYAW_VEH_ERR_AMP, ISignals/QU_VYAW_VEH], system-signal-group=e2eGrp_VYAW_VEH
    e2eGrp_V_VEH: i-signal=[ISignals/CRC_V_VEH, ISignals/ALIV_V_VEH, ISignals/ST_V_VEH_NSS, ISignals/V_VEH_COG, ISignals/QU_V_VEH_COG, ISignals/DVCO_VEH, ISignals/V_VEH_dummy_39_39], system-signal-group=e2eGrp_V_VEH
package /BMW/SystemDescription/EndtoEndProtections
  end to end protection set EndToEndProtectionSet
    18 x end to end protection:
      e2e_ACLNY_MASSCNTR: end-to-end-profile={category=PROFILE_01, data-ids=31, data-id-mode=0, data-length=48, max-delta-counter-init=14, crc-offset=0, counter-offset=8}, end-to-end-protection-i-signal-i-pdu{data-offset=0, i-signal-group=e2eGrp_ACLNY_MASSCNTR, i-signal-i-pdu=Pdus/ACLNY_MASSCNTR}
      e2e_AVL_FORC_GRD: end-to-end-profile={category=PROFILE_01, data-ids=190, data-id-mode=0, data-length=40, max-delta-counter-init=14, crc-offset=0, counter-offset=8}, end-to-end-protection-i-signal-i-pdu{data-offset=0, i-signal-group=e2eGrp_AVL_FORC_GRD, i-signal-i-pdu=Pdus/AVL_FORC_GRD}
      e2e_AVL_PO_EPS: end-to-end-profile={category=PROFILE_01, data-ids=186, data-id-mode=0, data-length=64, max-delta-counter-init=14, crc-offset=0, counter-offset=8}, end-to-end-protection-i-signal-i-pdu{data-offset=0, i-signal-group=e2eGrp_AVL_PO_EPS, i-signal-i-pdu=Pdus/AVL_PO_EPS}
      e2e_AVL_RPM_WHL: end-to-end-profile={category=PROFILE_01, data-ids=17, data-id-mode=0, data-length=96, max-delta-counter-init=14, crc-offset=0, counter-offset=8}, end-to-end-protection-i-signal-i-pdu{data-offset=0, i-signal-group=e2eGrp_AVL_RPM_WHL, i-signal-i-pdu=Pdus/AVL_RPM_WHL}
      e2e_AVL_STMOM_DV_ACT: end-to-end-profile={category=PROFILE_01, data-ids=108, data-id-mode=0, data-length=32, max-delta-counter-init=14, crc-offset=0, counter-offset=8}, end-to-end-protection-i-signal-i-pdu{data-offset=0, i-signal-group=e2eGrp_AVL_STMOM_DV_ACT, i-signal-i-pdu=Pdus/AVL_STMOM_DV_ACT}
      e2e_CON_VEH: end-to-end-profile={category=PROFILE_01, data-ids=197, data-id-mode=0, data-length=64, max-delta-counter-init=14, crc-offset=0, counter-offset=8}, end-to-end-protection-i-signal-i-pdu{data-offset=0, i-signal-group=e2eGrp_CON_VEH, i-signal-i-pdu=Pdus/CON_VEH}
      e2e_DISP_CC_EPS: end-to-end-profile={category=PROFILE_01, data-ids=3148, data-id-mode=3, data-length=40, max-delta-counter-init=14, crc-offset=0, counter-offset=8, data-id-nibble-offset=12}, end-to-end-protection-i-signal-i-pdu{data-offset=0, i-signal-group=e2eGrp_DISP_CC_EPS, i-signal-i-pdu=Pdus/DISP_CC_EPS}
      e2e_DT_EST: end-to-end-profile={category=PROFILE_01, data-ids=230, data-id-mode=0, data-length=128, max-delta-counter-init=14, crc-offset=0, counter-offset=8}, end-to-end-protection-i-signal-i-pdu{data-offset=0, i-signal-group=e2eGrp_DT_EST, i-signal-i-pdu=Pdus/DT_EST}
      e2e_ENERG_DGR_DRDY: end-to-end-profile={category=PROFILE_01, data-ids=56, data-id-mode=0, data-length=64, max-delta-counter-init=14, crc-offset=56, counter-offset=52}, end-to-end-protection-i-signal-i-pdu{data-offset=0, i-signal-group=e2eGrp_ENERG_DGR_DRDY, i-signal-i-pdu=Pdus/ENERG_DGR_DRDY}
      e2e_ENSU_SFY: end-to-end-profile={category=PROFILE_01, data-ids=628, data-id-mode=3, data-length=64, max-delta-counter-init=14, crc-offset=0, counter-offset=8, data-id-nibble-offset=12}, end-to-end-protection-i-signal-i-pdu{data-offset=0, i-signal-group=e2eGrp_ENSU_SFY, i-signal-i-pdu=Pdus/ENSU_SFY}
      e2e_OFFS_QUAD_EPS: end-to-end-profile={category=PROFILE_01, data-ids=229, data-id-mode=0, data-length=40, max-delta-counter-init=14, crc-offset=0, counter-offset=8}, end-to-end-protection-i-signal-i-pdu{data-offset=0, i-signal-group=e2eGrp_OFFS_QUAD_EPS, i-signal-i-pdu=Pdus/OFFS_QUAD_EPS}
      e2e_ST_EST: end-to-end-profile={category=PROFILE_01, data-ids=112, data-id-mode=0, data-length=40, max-delta-counter-init=14, crc-offset=0, counter-offset=8}, end-to-end-protection-i-signal-i-pdu{data-offset=0, i-signal-group=e2eGrp_ST_EST, i-signal-i-pdu=Pdus/ST_EST}
      e2e_SU_EPS: end-to-end-profile={category=PROFILE_01, data-ids=131, data-id-mode=0, data-length=64, max-delta-counter-init=14, crc-offset=56, counter-offset=52}, end-to-end-protection-i-signal-i-pdu{data-offset=0, i-signal-group=e2eGrp_SU_EPS, i-signal-i-pdu=Pdus/SU_EPS}
      e2e_TAR_ESTP_VIRT_FTAX: end-to-end-profile={category=PROFILE_01, data-ids=52, data-id-mode=0, data-length=64, max-delta-counter-init=14, crc-offset=0, counter-offset=8}, end-to-end-protection-i-signal-i-pdu{data-offset=0, i-signal-group=e2eGrp_TAR_ESTP_VIRT_FTAX, i-signal-i-pdu=Pdus/TAR_ESTP_VIRT_FTAX}
      e2e_TAR_QTA_STRMOM_DV: end-to-end-profile={category=PROFILE_01, data-ids=109, data-id-mode=0, data-length=64, max-delta-counter-init=14, crc-offset=0, counter-offset=8}, end-to-end-protection-i-signal-i-pdu{data-offset=0, i-signal-group=e2eGrp_TAR_QTA_STRMOM_DV, i-signal-i-pdu=Pdus/TAR_QTA_STRMOM_DV}
      e2e_TAR_STMOM_DV_ACT: end-to-end-profile={category=PROFILE_01, data-ids=179, data-id-mode=0, data-length=64, max-delta-counter-init=14, crc-offset=0, counter-offset=8}, end-to-end-protection-i-signal-i-pdu{data-offset=0, i-signal-group=e2eGrp_TAR_STMOM_DV_ACT, i-signal-i-pdu=Pdus/TAR_STMOM_DV_ACT}
      e2e_VYAW_VEH: end-to-end-profile={category=PROFILE_01, data-ids=14, data-id-mode=0, data-length=48, max-delta-counter-init=14, crc-offset=0, counter-offset=8}, end-to-end-protection-i-signal-i-pdu{data-offset=0, i-signal-group=e2eGrp_VYAW_VEH, i-signal-i-pdu=Pdus/VYAW_VEH}
      e2e_V_VEH: end-to-end-profile={category=PROFILE_01, data-ids=12, data-id-mode=0, data-length=40, max-delta-counter-init=14, crc-offset=0, counter-offset=8}, end-to-end-protection-i-signal-i-pdu{data-offset=0, i-signal-group=e2eGrp_V_VEH, i-signal-i-pdu=Pdus/V_VEH}
package /BMW/SystemDescription/ISignalIPduGroups
  13 x i signal i pdu group:
    EPS_IN_PduGroup: communication-direction=IN, communication-mode=KOM_FAHRBEREITSCHAFT_BEENDEN_ON, KOM_FAHRBEREITSCHAFT_HERSTELLEN_ON, KOM_FAHREN_ON, KOM_PRUEFEN_ANALYSE_DIAGNOSE_ON, KOM_STANDFUNKTIONEN_KUNDE_NICHT_IM_FZG_ON, KOM_WOHNEN_ON, i-signal-i-pdus=[Pdus/ACLNY_MASSCNTR, Pdus/STEA_OFFS, Pdus/ST_ENERG_GEN]
    EPS_IN_PduGroup10: communication-direction=IN, communication-mode=KOM_FAHRBEREITSCHAFT_BEENDEN_ON, KOM_FAHRBEREITSCHAFT_HERSTELLEN_ON, KOM_FAHREN_ON, KOM_PRUEFEN_ANALYSE_DIAGNOSE_ON, KOM_STANDFUNKTIONEN_KUNDE_NICHT_IM_FZG_ON, KOM_WOHNEN_ON, ENTERTAINMENTBETRIEB_ON, i-signal-i-pdus=Pdus/ST_CENG
    EPS_IN_PduGroup2: communication-direction=IN, communication-mode=KOM_FAHRBEREITSCHAFT_BEENDEN_ON, KOM_FAHRBEREITSCHAFT_HERSTELLEN_ON, KOM_FAHREN_ON, KOM_PARKEN_BN_IO_ON, KOM_PARKEN_BN_NIO_ON, KOM_PRUEFEN_ANALYSE_DIAGNOSE_ON, KOM_STANDFUNKTIONEN_KUNDE_NICHT_IM_FZG_ON, KOM_WOHNEN_ON, ASSISTENZ_PARKEN_HIGH_ON, ENTERTAINMENTBETRIEB_ON, i-signal-i-pdus=Pdus/ANFRAGE
    EPS_IN_PduGroup3: communication-direction=IN, communication-mode=KOM_FAHRBEREITSCHAFT_BEENDEN_ON, KOM_FAHRBEREITSCHAFT_HERSTELLEN_ON, KOM_FAHREN_ON, KOM_PARKEN_BN_IO_ON, KOM_PARKEN_BN_NIO_ON, KOM_PRUEFEN_ANALYSE_DIAGNOSE_ON, KOM_STANDFUNKTIONEN_KUNDE_NICHT_IM_FZG_ON, KOM_WOHNEN_ON
      i-signal-i-pdus:
        Pdus/AVL_RPM_WHL
        Pdus/FAHRGESTELLNUMMER
        Pdus/OFFS_QUAD_EPS
        Pdus/SECU_FAHRGESTELLNUMMER
        Pdus/ST_STAB_DSC
        Pdus/SU_CLE_DRDY_DXP
        Pdus/TAR_ESTP_VIRT_FTAX
        Pdus/TAR_QTA_STRMOM_DV
        Pdus/TAR_STMOM_DV_ACT
        Pdus/VYAW_VEH
        Pdus/V_VEH
    EPS_IN_PduGroup4: communication-direction=IN, communication-mode=KOM_FAHRBEREITSCHAFT_BEENDEN_ON, KOM_FAHRBEREITSCHAFT_HERSTELLEN_ON, KOM_FAHREN_ON, KOM_PARKEN_BN_IO_ON, KOM_PARKEN_BN_NIO_ON, KOM_PRUEFEN_ANALYSE_DIAGNOSE_ON, KOM_STANDFUNKTIONEN_KUNDE_NICHT_IM_FZG_ON, KOM_WOHNEN_ON, ENTERTAINMENTBETRIEB_ON, i-signal-i-pdus=[Pdus/A_TEMP, Pdus/FZZSTD, Pdus/KILOMETERSTAND, Pdus/RELATIVZEIT, Pdus/SECU_RESP]
    EPS_IN_PduGroup5: communication-direction=IN, communication-mode=KOM_FAHRBEREITSCHAFT_BEENDEN_ON, KOM_FAHRBEREITSCHAFT_HERSTELLEN_ON, KOM_FAHREN_ON, KOM_PARKEN_BN_IO_ON, KOM_PARKEN_BN_NIO_ON, KOM_PRUEFEN_ANALYSE_DIAGNOSE_ON, KOM_STANDFUNKTIONEN_KUNDE_NICHT_IM_FZG_ON, KOM_WOHNEN_ON, ASSISTENZ_PARKEN_HIGH_ON, ENTERTAINMENTBETRIEB_ON, LICHT_ON, i-signal-i-pdus=Pdus/CON_VEH
    EPS_IN_PduGroup6: communication-direction=IN, communication-mode=KOM_FAHRBEREITSCHAFT_BEENDEN_ON, KOM_FAHRBEREITSCHAFT_HERSTELLEN_ON, KOM_FAHREN_ON, KOM_PRUEFEN_ANALYSE_DIAGNOSE_ON, i-signal-i-pdus=[Pdus/CTR_DIAG_OBD_DRDY, Pdus/CTR_VIB_STW_DISP_EXMI_SP2015, Pdus/ENSU_SFY]
    EPS_IN_PduGroup7: communication-direction=IN, communication-mode=KOM_FAHRBEREITSCHAFT_BEENDEN_ON, KOM_FAHRBEREITSCHAFT_HERSTELLEN_ON, KOM_FAHREN_ON, KOM_PRUEFEN_ANALYSE_DIAGNOSE_ON, KOM_STANDFUNKTIONEN_KUNDE_NICHT_IM_FZG_ON, KOM_WOHNEN_ON, LADEN_ON, i-signal-i-pdus=Pdus/DIAG_OBD_ENG
    EPS_IN_PduGroup8: communication-direction=IN, communication-mode=KOM_FAHRBEREITSCHAFT_BEENDEN_ON, KOM_FAHRBEREITSCHAFT_HERSTELLEN_ON, KOM_FAHREN_ON, KOM_PARKEN_BN_IO_ON, KOM_PRUEFEN_ANALYSE_DIAGNOSE_ON, KOM_STANDFUNKTIONEN_KUNDE_NICHT_IM_FZG_ON, KOM_WOHNEN_ON, i-signal-i-pdus=Pdus/ENERG_DGR_DRDY
    EPS_IN_PduGroup9: communication-direction=IN, communication-mode=KOM_FAHRBEREITSCHAFT_BEENDEN_ON, KOM_FAHRBEREITSCHAFT_HERSTELLEN_ON, KOM_FAHREN_ON, KOM_PRUEFEN_ANALYSE_DIAGNOSE_ON, KOM_STANDFUNKTIONEN_KUNDE_NICHT_IM_FZG_ON, KOM_WOHNEN_ON, ASSISTENZ_PARKEN_HIGH_ON, ENTERTAINMENTBETRIEB_ON, i-signal-i-pdus=Pdus/ERRM_BN_U
    EPS_OUT_PduGroup: communication-direction=OUT, communication-mode=KOM_FAHRBEREITSCHAFT_BEENDEN_ON, KOM_FAHRBEREITSCHAFT_HERSTELLEN_ON, KOM_FAHREN_ON, KOM_PARKEN_BN_IO_ON, KOM_PARKEN_BN_NIO_ON, KOM_PRUEFEN_ANALYSE_DIAGNOSE_ON, KOM_STANDFUNKTIONEN_KUNDE_NICHT_IM_FZG_ON, KOM_WOHNEN_ON, ASSISTENZ_PARKEN_HIGH_ON, ENTERTAINMENTBETRIEB_ON, i-signal-i-pdus=Pdus/ANFRAGE
    EPS_OUT_PduGroup2: communication-direction=OUT, communication-mode=KOM_FAHRBEREITSCHAFT_BEENDEN_ON, KOM_FAHRBEREITSCHAFT_HERSTELLEN_ON, KOM_FAHREN_ON, KOM_PRUEFEN_ANALYSE_DIAGNOSE_ON
      i-signal-i-pdus:
        Pdus/AVL_FORC_GRD
        Pdus/AVL_PO_EPS
        Pdus/AVL_STMOM_DV_ACT
        Pdus/DBG_EPS_BS_MOD_58_BYTE
        Pdus/DBG_EPS_MOD_EXT_120_BYTE
        Pdus/DISP_CC_EPS
        Pdus/DT_EST
        Pdus/ENGTORQ_EPS
        Pdus/RQ_STG_EFAN
        Pdus/ST_DIAG_OBD_3_DRDY
        Pdus/ST_EST
        Pdus/SU_EPS
    EPS_OUT_PduGroup3: communication-direction=OUT, communication-mode=KOM_FAHRBEREITSCHAFT_BEENDEN_ON, KOM_FAHRBEREITSCHAFT_HERSTELLEN_ON, KOM_FAHREN_ON, KOM_PARKEN_BN_IO_ON, KOM_PARKEN_BN_NIO_ON, KOM_PRUEFEN_ANALYSE_DIAGNOSE_ON, KOM_STANDFUNKTIONEN_KUNDE_NICHT_IM_FZG_ON, KOM_WOHNEN_ON, i-signal-i-pdus=Pdus/SECU_CHAL
package /BMW/SystemDescription/ModeDeclarationGroups/BasePartialNetworks
  9 x mode declaration group:
    PWFVehicleState: initial-mode=PWFVehicleState/KEINE_KOMMUNIKATION
      9 x mode:
        KEINE_KOMMUNIKATION
        KOM_FAHRBEREITSCHAFT_BEENDEN
        KOM_FAHRBEREITSCHAFT_HERSTELLEN
        KOM_FAHREN
        KOM_PARKEN_BN_IO
        KOM_PARKEN_BN_NIO
        KOM_PRUEFEN_ANALYSE_DIAGNOSE
        KOM_STANDFUNKTIONEN_KUNDE_NICHT_IM_FZG
        KOM_WOHNEN
    KOM_FAHRBEREITSCHAFT_BEENDEN: initial-mode=KOM_FAHRBEREITSCHAFT_BEENDEN_OFF
      mode KOM_FAHRBEREITSCHAFT_BEENDEN_OFF
      mode KOM_FAHRBEREITSCHAFT_BEENDEN_ON
    KOM_FAHRBEREITSCHAFT_HERSTELLEN: initial-mode=KOM_FAHRBEREITSCHAFT_HERSTELLEN_OFF
      mode KOM_FAHRBEREITSCHAFT_HERSTELLEN_OFF
      mode KOM_FAHRBEREITSCHAFT_HERSTELLEN_ON
    KOM_FAHREN: initial-mode=KOM_FAHREN_OFF
      mode KOM_FAHREN_OFF
      mode KOM_FAHREN_ON
    KOM_PARKEN_BN_IO: initial-mode=KOM_PARKEN_BN_IO_OFF
      mode KOM_PARKEN_BN_IO_OFF
      mode KOM_PARKEN_BN_IO_ON
    KOM_PARKEN_BN_NIO: initial-mode=KOM_PARKEN_BN_NIO_OFF
      mode KOM_PARKEN_BN_NIO_OFF
      mode KOM_PARKEN_BN_NIO_ON
    KOM_PRUEFEN_ANALYSE_DIAGNOSE: initial-mode=KOM_PRUEFEN_ANALYSE_DIAGNOSE_OFF
      mode KOM_PRUEFEN_ANALYSE_DIAGNOSE_OFF
      mode KOM_PRUEFEN_ANALYSE_DIAGNOSE_ON
    KOM_STANDFUNKTIONEN_KUNDE_NICHT_IM_FZG: initial-mode=KOM_STANDFUNKTIONEN_KUNDE_NICHT_IM_FZG_OFF
      mode KOM_STANDFUNKTIONEN_KUNDE_NICHT_IM_FZG_OFF
      mode KOM_STANDFUNKTIONEN_KUNDE_NICHT_IM_FZG_ON
    KOM_WOHNEN: initial-mode=KOM_WOHNEN_OFF
      mode KOM_WOHNEN_OFF
      mode KOM_WOHNEN_ON
package /BMW/SystemDescription/ModeDeclarationGroups/FunctionalPartialNetworks
  4 x mode declaration group:
    AssistenzParkenHigh: initial-mode=ASSISTENZ_PARKEN_HIGH_OFF
      mode ASSISTENZ_PARKEN_HIGH_OFF
      mode ASSISTENZ_PARKEN_HIGH_ON
    Entertainmentbetrieb: initial-mode=ENTERTAINMENTBETRIEB_OFF
      mode ENTERTAINMENTBETRIEB_OFF
      mode ENTERTAINMENTBETRIEB_ON
    Laden: initial-mode=LADEN_OFF
      mode LADEN_OFF
      mode LADEN_ON
    Licht: initial-mode=LICHT_OFF
      mode LICHT_OFF
      mode LICHT_ON
package /BMW/Boardnet/Clusters/CommunicationClusters
  flexray cluster A_FlexRay:
    baudrate=10000000
    protocol-name=FlexRay
    action-point-offset=2
    bit=1E-7
    cas-rx-low-max=79
    cold-start-attempts=8
    cycle=0.005
    cycle-count-max=63
    detect-nit-error=false
    dynamic-slot-idle-phase=1
    ignore-after-tx=0
    listen-noise=2
    macro-per-cycle=3636
    macrotick-duration=0.000001375
    max-without-clock-correction-fatal=2
    max-without-clock-correction-passive=2
    minislot-action-point-offset=2
    minislot-duration=5
    network-idle-time=7
    network-management-vector-length=0
    number-of-minislots=289
    number-of-static-slots=91
    offset-correction-start=3632
    payload-length-static=8
    safety-margin=100
    sample-clock-period=1.25E-8
    static-slot-duration=24
    symbol-window=0
    symbol-window-action-point-offset=2
    sync-frame-id-count-max=15
    transmission-start-sequence-duration=9
    wakeup-rx-idle=59
    wakeup-rx-low=50
    wakeup-rx-window=301
    wakeup-tx-active=60
    wakeup-tx-idle=180
    flexray physical channel A_FlexRay: comm-connectors=con_EPS_FibexID_0b7e5e09c061465d913e8968ece3cded, channel-name=CHANNEL-A  # A-FlexRay
      frame xcpstatic: from EPS, category=XCP_RUNTIME_CONFIGURED, frame-length=16, flexray-absolutely-scheduled-timing{communication-cycle=cycle-repetition={base-cycle=0, cycle-repetition=CYCLE-REPETITION-1}, slot-id=10}, allow-dynamic-l-sdu-length=false, payload-preamble-indicator=false  # XCP Bereich Statisch / XCP Frame Static | Dieser Frame dient als Platzhalter für die XCP-Konfiguration für FlexRay (s. LH FlexRay) und zur Pufferkonfiguration der FlexRay-Controller. Der statische XCP-Bereich wird auch durch das Projekt "Funktionstrace" mitbenutzt. Ansprechpartner ist Florian Kuttig oder Christian Pigorsch. / Dummyframe für Infrastruktur XCP
        general purpose i pdu dummy16bstatic: category=XCP, length=16  # Dummy-PDU 16 Byte static | Dummy-PDU ohne inhaltliche Verbindlichkeit mit 16 Byte für Infrastruktur (z.B. XCP).
      frame ERRM_BN_U: to EPS, category=APPLICATION, frame-length=2, flexray-absolutely-scheduled-timing{communication-cycle=cycle-repetition={base-cycle=0, cycle-repetition=CYCLE-REPETITION-1}, slot-id=104}, allow-dynamic-l-sdu-length=false, payload-preamble-indicator=false  # Fehlerspeicher Bordnetz Spannung
        pdu ERRM_BN_U: length=2, minimum-delay=0.01, transmission-mode-true-timing={cyclic-timing=time-period={tolerance=absolute-tolerance=1, value=5}, event-controlled-timing={number-of-repetitions=0, "Die Nachricht wird bei einer beliebigen Änderung des Signals "Steuerung Fehlerspeicher Bordnetzspannung" ereignisgesteuert versendet."}}, unused-bit-pattern=255  # Fehlerspeicher Bordnetz Spannung | Diese Botschaft beinhaltet das Signal Steuerung Fehlerspeicher Bordnetzspannung mit dem Ziel der Bereitstellung von Spannungsschwellen für das Fehlerspeicherhandling. Diese Botschaft wird von einigen Versionen der DME nicht verschickt. Es darf daher auf Empfängerseite keine Timeout-Fehlerspeichereinträge dazu geben. Die Empfänger müssen bei Timeout dieser Botschaft eine interne Ersatzwertbildung vornehmen.
          signal CTR_ERRM_BN_U: start 0, 6 bit, little-endian, base-type=uint8, invalid-value=value_63Dot0:63, compu {mask 33: 0=KeineUnterspannungNormalbetrieb (CTR_ERRM_BN_U_KeineUnterspannungNormalbetrieb) (Unterspannungsschwelle für Normalbetrieb nicht erreicht. / BNE original name: Keine Unterspannung Normalbetrieb), mask 33: 1=UnterspannungNormalbetrieb (CTR_ERRM_BN_U_UnterspannungNormalbetrieb) (Unterspannungsschwelle für Normalbetrieb unterschritten. / BNE original name: Unterspannung Normalbetrieb), mask 34: 0=KeineUnterspannungMSA_Start (CTR_ERRM_BN_U_KeineUnterspannungMSA_Start) (Unterspannungsschwelle für MSA-Start Festigkeit nicht erreicht. / BNE original name: Keine Unterspannung MSA-Start), mask 34: 2=UnterspannungMSA_Start (CTR_ERRM_BN_U_UnterspannungMSA_Start) (Unterspannungsschwelle für MSA-Start Festigkeit unterschritten. / BNE original name: Unterspannung MSA-Start), mask 36: 0=KeineUeberspannung (CTR_ERRM_BN_U_KeineUeberspannung) (Überspannungsschwelle nicht erreicht. / BNE original name: Keine Überspannung), mask 36: 4=Ueberspannung (CTR_ERRM_BN_U_Ueberspannung) (Überspannungsschwelle überschritten. / BNE original name: Überspannung), mask 63: 61=Funktionsschnittstelle_ist_nicht_verfuegbar (CTR_ERRM_BN_U_Funktionsschnittstelle_ist_nicht_verfuegbar) (Sendefunktion in Betrieb, Werte nicht verfügbar), mask 63: 62=Funktion_meldet_Fehler (CTR_ERRM_BN_U_Funktion_meldet_Fehler) (Sendefunktion in Betrieb, meldet Fehler), mask 63: 63=Signal_unbefuellt (CTR_ERRM_BN_U_Signal_unbefuellt) (Sendefunktion nicht in Betrieb)} "Steuerung_Fehlerspeicher_Bordnetz_Spannung / control_error-memory_Bordnetz_voltage", transfer-property=TRIGGERED-ON-CHANGE, to EPS  # Steuerung_Fehlerspeicher_Bordnetz_Spannung / control_error-memory_Bordnetz_voltage | LogicalInterface:BMW.INFRASTRUCTURE.LOWVOLTAGE.EnergyManagement[internal]@Infrastruktur; Das Signal Steuerung_Fehlerspeicher_Bordnetz_Spannung stellt Spannungsschwellen für das Fehlerspeicherhandling zur Verfügung.
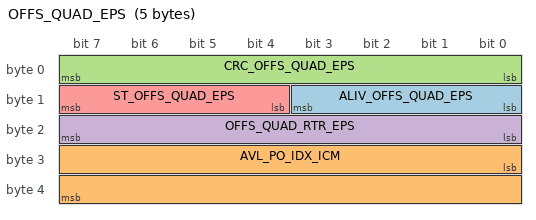
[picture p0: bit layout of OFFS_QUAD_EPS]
      frame OFFS_QUAD_EPS: to EPS, category=APPLICATION, frame-length=5, flexray-absolutely-scheduled-timing{communication-cycle=cycle-repetition={base-cycle=0, cycle-repetition=CYCLE-REPETITION-1}, slot-id=107}, allow-dynamic-l-sdu-length=false, payload-preamble-indicator=false  # Offset Quadrant EPS
        pdu OFFS_QUAD_EPS: length=5, minimum-delay=0.01, transmission-mode-true-timing={cyclic-timing=time-period={tolerance=absolute-tolerance=0.2, value=1}, event-controlled-timing={number-of-repetitions=0, "Wird bei Änderung des Signals ST_OFFS_QUAD_EPS 2-malig mit einem Wiederholzyklus von t = 10 ms versendet."}}, unused-bit-pattern=255  # Offset Quadrant EPS | Mittels Aufsetzalgorithmus ermittelter Offset des aktuellen Nullpunktes der EPS-Position (entspricht der Segmentmitte des Segments in dem sich der EPS-Rotor z.B. nach dem letzten Einbruch der Spannungsversorgung befand) zum absoluten Nullpunkt (Segmentmitte des Segments bei Geradeausfahrt). Die Nachricht wird beim Zustandswechsel vom ST_OFFS_QUAD_EPS sofort gesendet (ereignisgesteuert). Um sicher zu stellen dass die EPS die Daten empfängt, wird die Nachricht 2-malig gesendet mit einer Wiederholrate von 10ms. Dabei ist zu beachten, dass der funktionale Inhalt der Botschaft (gilt nicht für CRC und Alive) bei der Wiederholung identisch bleiben wird. Ausnahme: In DSC_2013 (MCV) und DSC_Modul (444, UKL) weicht der Implementierungsstand bzgl. der wiederholten Versendung von der hier definierten Spezifikation ab. Details sind im jeweiligen Projekt dokumentiert.
          signal ALIV_OFFS_QUAD_EPS: start 8, 4 bit, little-endian, base-type=uint8, invalid-value=value_15Dot0:15, compu-method=CompuMethodsForBoardnet/ALIV_COU_4, transfer-property=TRIGGERED-ON-CHANGE, to EPS  # Alive_Offset_Quadrant_EPS / alive_offset_quadrant_EPS | LogicalInterface:BMW.CHASSIS.STEERING.ElectricPowerSteering[internal]@Fahren;
          signal AVL_PO_IDX_ICM: start 24, 16 bit, little-endian, base-type=uint16, invalid-value=value_65535Dot0:65535, compu {phys=raw*0.0439453125-1439.956055 for raw 32767..1524029.5777777778}, range phys 0..65534, transfer-property=TRIGGERED-ON-CHANGE, to EPS  # Ist_Position_Index_ICM / actual-value_position_index_ICM | LogicalInterface:BMW.CHASSIS.STEERING.ElectricPowerSteering[internal]@Fahren; Rücksenden des von der EPS übertragenen Wertes von Ist_Position_Index_EPS, sofern mit Hilfe des Index-Signals aufgesetzt werden konnte. Dies soll bei einem weiteren Rotorsegmentwechsel, zwischen dem Empfang einer Indexflanke und Zurücksenden des vom Aufsetzalgorithmus ermittelten Offsetwertes, ermöglichen, diesen auf Seiten der EPS berücksichtigen und korrigieren zu können. Das Signal wird ohne Einheit übertragen. Die Einheit kann aus dem Signal "Einheit_Position_EPS" entnommen werden aus der Nachricht "Ist Position EPS": - Im F25/L7 ist das Signal als Zahnstangenhub zu interpretieren. Die Einheit ist somit 0.2mm. Hinweis: Aufgrund der derzeitigen bei der Nachrichtenkataloggenerierung durch die IT bedingte Rundung von Nachkommastellen, werden die Offset- und Quantisierungswerte nicht korrekt wieder gegeben. Folgende Angaben entsprechen den exakten Werten: Offset = -1439,9560546875 Quantisierung = 0,0439453125
          signal CRC_OFFS_QUAD_EPS: start 0, 8 bit, little-endian, base-type=uint8, compu-method=CompuMethodsForBoardnet/CRC8, data-constr=DataConstraints/CRC8, transfer-property=TRIGGERED-ON-CHANGE, to EPS  # CRC_Offset_Quadrant_EPS / CRC_offset_quadrant_EPS | LogicalInterface:BMW.CHASSIS.STEERING.ElectricPowerSteering[internal]@Fahren; Standardabsicherung Applikations-CRC Dieses Signal verwendet die Applikations-CRC-ID = 229 (Dez)
          signal OFFS_QUAD_RTR_EPS: start 16, 8 bit, little-endian, base-type=uint8, invalid-value=value_255Dot0:255, compu {phys=raw-127 for raw 127..381}, range phys 0..254, transfer-property=TRIGGERED-ON-CHANGE, to EPS  # Offset_Quadrant_Rotor_EPS / offset_quadrant_rotor_EPS | LogicalInterface:BMW.CHASSIS.STEERING.ElectricPowerSteering[internal]@Fahren; Mittels Aufsetzalgorithmus ermittelter Offset des aktuellen Nullpunktes der EPS-Position (entspricht der Segmentmitte des Segments in dem sich der EPS-Rotor z.B. nach dem letzten Einbruch der Spannungsversorgung befand) zum absoluten Nullpunkt (Segmentmitte des Segments bei Geradeausfahrt). Der Offset wird angegeben als Anzahl voller Umdrehungen des EPS-Rotors (entspr. Anzahl Segmente).
          signal ST_OFFS_QUAD_EPS: start 12, 4 bit, little-endian, base-type=uint8, invalid-value=value_15Dot0:15, compu {0=Algorithmus_Funktion_ImSleep_Modus (ST_OFFS_QUAD_PINA_EPS_Algorithmus_Funktion_ImSleep_Modus) (Die Funktion ist bereit aber zur Zeit nicht aktiv / BNE original name: Algorithmus (Funktion) im Sleep-Modus), 1=OffsetWirdErmittelt (ST_OFFS_QUAD_PINA_EPS_OffsetWirdErmittelt) (BNE original name: Offset wird ermittelt), 2=OffsetUebernehmenAufsetzenUeberIndex (ST_OFFS_QUAD_PINA_EPS_OffsetUebernehmenAufsetzenUeberIndex) (Kann nur gesendet werden wenn Qualifier_Ist_Position_EPS = Ersatzwert oder ab SP2013 (außer F15-F16, 444) "Signalwert ist gültig, Zustand/Status temporär" / BNE original name: Offset übernehmen, Aufsetzen über Index), 3=OffsetUebernehmenAufsetzenUeberModelvergleich (ST_OFFS_QUAD_PINA_EPS_OffsetUebernehmenAufsetzenUeberModelvergleich) (Kann nur gesendet werden wenn Qualifier_Ist_Position_EPS = Ersatzwert oder ab SP2013 (außer F15-F16, 444) "Signalwert ist gültig, Zustand/Status temporär" / BNE original name: Offset übernehmen, Aufsetzen über Modelvergleich), 4=OffsetUebernehmenAufsetzenUeberAnschlag_Anschlag (ST_OFFS_QUAD_PINA_EPS_OffsetUebernehmenAufsetzenUeberAnschlag_Anschlag) (Kann nur gesendet werden wenn Qualifier_Ist_Position_EPS = Ersatzwert oder ab SP2013 (außer F15-F16, 444) "Signalwert ist gültig, Zustand/Status temporär" / BNE original name: Offset übernehmen, Aufsetzen über Anschlag-Anschlag), 5=OffsetUebernehmenAufsetzenUeberSummenlenkwinkel_imAFS_Fall_ (ST_OFFS_QUAD_PINA_EPS_OffsetUebernehmenAufsetzenUeberSummenlenkwinkel_imAFS_Fall_) (Kann nur gesendet werden wenn Qualifier_Ist_Position_EPS = Ersatzwert oder ab SP2013 (außer F15-F16, 444) "Signalwert ist gültig, Zustand/Status temporär" Wird zurzeit nicht verwendet. / BNE original name: Offset übernehmen, Aufsetzen über Summenlenkwinkel (im AFS-Fall)), 6=OffsetInPruefung (ST_OFFS_QUAD_PINA_EPS_OffsetInPruefung) (Wird gesetzt nach Offset übernehmen (nicht nach Groboffset!) bzw. sofern die EPS sich selbst aufsetzen konnte und nach Offset korrigieren, während der Bestätigungsphase. / BNE original name: Offset in Prüfung), 7=OffsetKorrigieren (ST_OFFS_QUAD_PINA_EPS_OffsetKorrigieren) (Kann nur gesendet werden wenn Qualifier_Ist_Position_EPS = "Gültig" oder "Gültig und Abgesichert" / BNE original name: Offset korrigieren), 8=Initialisierung (ST_OFFS_QUAD_PINA_EPS_Initialisierung) (wird im aller ersten Rechenzyklus gesetzt (10ms)), 9=RestoffsetWirdErmittelt (ST_OFFS_QUAD_PINA_EPS_RestoffsetWirdErmittelt) (Wird gesetzt, nachdem im Zustand "Offset wird ermittelt" erstmals nur ein Groboffset bestimmt und an die EPS gesendet werden konnte. Wird erst ab SP2013 (außer F15-F16, 444) unterstützt. / BNE original name: Restoffset wird ermittelt), 11=OffsetUebernehmenGroboffsetUeberModell (ST_OFFS_QUAD_PINA_EPS_OffsetUebernehmenGroboffsetUeberModell) (Kann nur gesendet werden wenn Qualifier_Ist_Position_EPS = Ersatzwert Wird erst ab SP2013 (außer F15-F16, 444) unterstützt. / BNE original name: Offset übernehmen, Groboffset über Modell), 15=SignalUngueltig (ST_OFFS_QUAD_PINA_EPS_SignalUngueltig) (Kann Funktional nicht gesetzt werden / BNE original name: Signal ungültig)} "Status_Offset_Quadrant_Ritzelwinkel_EPS / status_offset_quadrant_pinion-angle_EPS", transfer-property=TRIGGERED-ON-CHANGE, to EPS  # Status_Offset_Quadrant_EPS / status_offset_quadrant_EPS | LogicalInterface:BMW.CHASSIS.STEERING.ElectricPowerSteering[internal]@Fahren; Mit dem Statuswert wird dem EPS-Steuergerät signalisiert, dass ein Offsetwert mithilfe des Aufsetzalgorithmus bestimmt werden konnte und zu übernehmen ist (= Offset übernehmen) bzw. dass der von der EPS aktuell verrechnete Offsetwert falsch ist und um den mitgelieferten Wert korrigiert werden muss (= Offset korrigieren). Ansonsten wird der Offset gerade ermittelt oder sofern dies bereits geschehen ist plausibilisiert und auf Richtigkeit überprüft (=Offset in Prüfung).
          mapping sigGroup_OFFS_QUAD_EPS: i-signal-group=sigGroup_OFFS_QUAD_EPS
      frame STEA_OFFS: to EPS, category=APPLICATION, frame-length=8, flexray-absolutely-scheduled-timing{communication-cycle=cycle-repetition={base-cycle=0, cycle-repetition=CYCLE-REPETITION-2}, slot-id=108}, allow-dynamic-l-sdu-length=false, payload-preamble-indicator=false  # Lenkwinkel Offset
        pdu STEA_OFFS: length=8, transmission-mode-true-timing=cyclic-timing=time-period={tolerance=absolute-tolerance=0.02, value=0.1}, unused-bit-pattern=255  # Lenkwinkel Offset | Offsetwerte zu den verschiedenen Lenkwinkeln. Die Werte werden mittels Langzeitabgleich gebildet.
          signal AVL_STEA_PNI_OFFS: start 36, 12 bit, little-endian, base-type=uint16, invalid-value=value_4095Dot0:4095, compu {phys=raw*0.021994-45 for raw 2046.0125488769665..188097.8947783001, 4093=Funktionsschnittstelle_ist_nicht_verfuegbar (AVL_STEA_PNI_OFFS_Funktionsschnittstelle_ist_nicht_verfuegbar) (Signal Tag - Schnittstelle ist nicht verfügbar), 4094=Funktion_meldet_Fehler (AVL_STEA_PNI_OFFS_Funktion_meldet_Fehler) (Signal Tag - Funktion meldet Fehler), 4095=Signal_unbefuellt (AVL_STEA_PNI_OFFS_Signal_unbefuellt) (Signal Tag - Signal ist unbefüllt)} "Ist_Lenkwinkel_Ritzel_Offset / actual-value_steering-angle_pinion_offset", range phys 0..4092.025 "Ist_Lenkwinkel_Ritzel_Offset / actual-value_steering-angle_pinion_offset", to EPS  # Ist_Lenkwinkel_Ritzel_Offset / actual-value_steering-angle_pinion_offset | LogicalInterface:BMW.CHASSIS.STEERING.ElectricPowerSteering[internal]@Fahren; Das Signal wird ohne Einheit übertragen. Die Einheit kann aus dem Signal "Einheit_Position_EPS" entnommen werden: - Signal kann als Ritzelwinkel interpretiert werden. Die Einheit ist Grad - Signal kann als Zahnstangenhub interpretiert werden. Die Einheit ist somit 0.2mm
      frame xcpstatic: from EPS, category=XCP_RUNTIME_CONFIGURED, frame-length=16, flexray-absolutely-scheduled-timing{communication-cycle=cycle-repetition={base-cycle=0, cycle-repetition=CYCLE-REPETITION-1}, slot-id=11}, allow-dynamic-l-sdu-length=false, payload-preamble-indicator=false  # XCP Bereich Statisch / XCP Frame Static | Dieser Frame dient als Platzhalter für die XCP-Konfiguration für FlexRay (s. LH FlexRay) und zur Pufferkonfiguration der FlexRay-Controller. Der statische XCP-Bereich wird auch durch das Projekt "Funktionstrace" mitbenutzt. Ansprechpartner ist Florian Kuttig oder Christian Pigorsch. / Dummyframe für Infrastruktur XCP
        carries pdu dummy16bstatic: packing-byte-order=little-endian, start-position=0
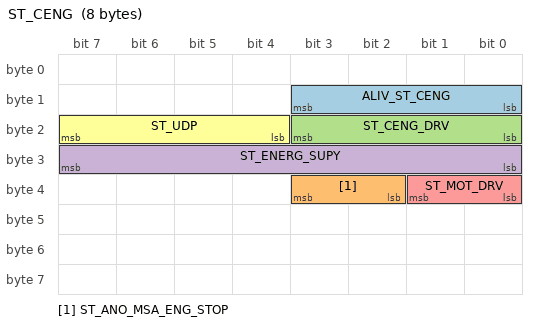
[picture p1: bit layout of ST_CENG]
      frame ST_CENG: to EPS, category=APPLICATION, frame-length=8, flexray-absolutely-scheduled-timing{communication-cycle=cycle-repetition={base-cycle=0, cycle-repetition=CYCLE-REPETITION-2}, slot-id=117}, allow-dynamic-l-sdu-length=false, payload-preamble-indicator=false  # Status Verbrennungsmotor
        pdu ST_CENG: length=8, minimum-delay=0.01, transmission-mode-true-timing={cyclic-timing=time-period={tolerance=absolute-tolerance=0.7, value=1}, event-controlled-timing=number-of-repetitions=0}, unused-bit-pattern=255  # Status Verbrennungsmotor
          signal ALIV_ST_CENG: start 8, 4 bit, little-endian, base-type=uint8, invalid-value=value_15Dot0:15, compu {identical}, range phys 0..14, transfer-property=TRIGGERED-ON-CHANGE, to EPS  # Alive_Status_Verbrennungsmotor / alive_status_combustion-engine | LogicalInterface:BMW.POWERTRAIN.ENGINE.DrivingReadinessEngineStart[internal]@Fahren; Standardabsicherung Alivezähler laut Definition per Lastenheft Allgemeine Bordnetzkommunikation
          signal ST_ANO_MSA_ENG_STOP: start 34, 2 bit, little-endian, base-type=uint8, invalid-value=value_3Dot0:3, compu {0=KeinAnkuendigung (ST_ANO_MSA_ENG_STOP_KeinAnkuendigung) (kein MSA-Motorstopp angekündigt oder aktiv / BNE original name: Kein Ankündigung), 1=AnkuendigungMSA_Motorstopp (ST_ANO_MSA_ENG_STOP_AnkuendigungMSA_Motorstopp) (MSA-Motorstopp angekündigt oder aktiv in Durchführung / BNE original name: Ankündigung MSA-Motorstopp), 3=SignalUngueltig (ST_ANO_MSA_ENG_STOP_SignalUngueltig) (BNE original name: Signal ungültig)} "Status_Ankündigung_MSA_Motor_Stop / status_announcement_MSA_engine_stop", transfer-property=TRIGGERED-ON-CHANGE, to EPS  # Status_Ankündigung_MSA_Motor_Stop / status_announcement_MSA_engine_stop | LogicalInterface:BMW.POWERTRAIN.ENGINE.DrivingReadinessEngineStart[external]@Fahren; In diesem Signal wird die Ankündigung des MSA-Motorstops kommuniziert.
          signal ST_CENG_DRV: start 16, 4 bit, little-endian, base-type=uint8, invalid-value=value_15Dot0:15, compu {0=MotorSteht (ST_CENG_DRV_MotorSteht) (Motorstillstand anhand interner Bedingungen erkannt (z.B. Kurbelwellendrehzahl < Schwelle für bestimmte Zeit) / BNE original name: Motor steht), 1=MotorStartet (ST_CENG_DRV_MotorStartet) (Startroutinen aktiv, Motor in Vorsteuerung / BNE original name: Motor startet), 2=MotorLaeuft (ST_CENG_DRV_MotorLaeuft) (Motor im geregelten Betrieb, Motorlauf ohne Startsystemeingriff gewährleistet / BNE original name: Motor läuft), 3=MotorImAuslauf (ST_CENG_DRV_MotorImAuslauf) (Anforderung zum Motorabstellen (z.B. über MSA-Anforderung, Anforderung Fahrbereitschaft beenden, etc.) / BNE original name: Motor im Auslauf), 13=Funktionsschnittstelle_ist_nicht_verfuegbar (ST_CENG_DRV_Funktionsschnittstelle_ist_nicht_verfuegbar) (DME in der Initialisierung (z.B. nach Reset)), 14=Reserviert (ST_CENG_DRV_Reserviert) (Hinweis: Reserviert für funktionale Kennung Signal-Tag.), 15=Signal_unbefuellt (ST_CENG_DRV_Signal_unbefuellt) (Sendefunktion nicht in Betrieb)} "Status_Verbrennungsmotor_Antrieb / status_combustion-engine_drive", transfer-property=TRIGGERED-ON-CHANGE, to EPS  # Status_Verbrennungsmotor_Antrieb / status_combustion-engine_drive | LogicalInterface:BMW.POWERTRAIN.ENGINE.DrivingReadinessEngineStart[external]@Fahren; In diesem Signal wird der Zusand des Antriebsverbrennungsmotors angegeben. Dieser Zustand gilt nicht für den REX-Verbrennungsmotors Motorzustand lässt keinen Rückschluss auf Kurbelwellendrehzahl zu. Aus der Reihenfolge der Codierung kann nicht auf gültige Zustandswechsel geschlossen werden.
          signal ST_ENERG_SUPY: start 24, 8 bit, little-endian, base-type=uint8, invalid-value=value_255Dot0:255, compu {mask 255: 0=KeinSpannungseinbruch (ST_ENERG_SUPY_KeinSpannungseinbruch) (BNE original name: Kein Spannungseinbruch), mask 255: 253=Reserviert (ST_ENERG_SUPY_Reserviert) (Hinweis: Reserviert für funktionale Kennung Signal-Tag), mask 255: 254=Reserviert_bne_D985F50C03774E8D88B7B0039518781F_254 (ST_ENERG_SUPY_Reserviert_bne_D985F50C03774E8D88B7B0039518781F_254) (Hinweis: Reserviert für funktionale Kennung Signal-Tag / BNE original name: Reserviert), mask 255: 255=Signal_unbefuellt (ST_ENERG_SUPY_Signal_unbefuellt) (Sendefunktion nicht in Betrieb), mask 129: 1=StartspannungseinbruchAufVersorgungszweig1 (ST_ENERG_SUPY_StartspannungseinbruchAufVersorgungszweig1) (Auf Versorgungszweig 1 ist bei MSA2.3 der Starter. Bei MSA2.5 kann beim Kaltstart Versorgungszweig 1 und Versorgungszweig 2 über ein Relais verbunden werden. / BNE original name: Startspannungseinbruch auf Versorgungszweig 1), mask 130: 2=StartspannungseinbruchAufVersorgungszweig2 (ST_ENERG_SUPY_StartspannungseinbruchAufVersorgungszweig2) (Auf Versorgungszweig 2 ist bei MSA2.5 der Starter. Bei den Hybriden ist die Zustarteinrichtung ebenfalls auf Versorgungszweig 2. / BNE original name: Startspannungseinbruch auf Versorgungszweig 2), mask 132: 4=Spannungsversorgung48Volt (ST_ENERG_SUPY_Spannungsversorgung48Volt) (BNE original name: Spannungsversorgung 48 Volt)} "Status_Energie_Versorgung / status_Energy_supply", transfer-property=TRIGGERED-ON-CHANGE, to EPS  # Status_Energie_Versorgung / status_Energy_supply | LogicalInterface:BMW.POWERTRAIN.ENGINE.DrivingReadinessEngineStart[external]@Fahren; Im diesem Signal wird angegeben welcher Energieversorgungszweig vom Spannungseinbruch im Signal Status_Spannungseinbruch betroffen ist. Die betroffenen Steuergeräte am jeweiligen Versorgungszweig können dadurch gezielt Maßnahmen für die Unterspannung ergreifen. Ist Status_Spannungseinbruch gleich 1101 (Schnittstelle ist nicht verfügbar) wird in diesem Signal 0000 0000b (Kein Spannungseinbruch) ausgegeben.
          signal ST_MOT_DRV: start 32, 2 bit, little-endian, base-type=uint8, invalid-value=value_3Dot0:3, compu {0=KeinE_MaschineVerfuegbar (ST_MOT_DRV_KeinE_MaschineVerfuegbar) (Keine Traktions-E-Maschine verfügbar, oder Traktions-E-Maschine(n) nicht bereit, oder elektrische Fahrbereitschaft nicht zulässig. / BNE original name: Kein E-Maschine verfügbar), 1=E_MaschineIstElektrischFahrbereitOderBereitsAktiv (ST_MOT_DRV_E_MaschineIstElektrischFahrbereitOderBereitsAktiv) (Hochvoltsystem ist aktiv, Traktions-E-Maschine(n) bereit und elektrische Fahrbereitschaft zulässig. / BNE original name: E-Maschine ist elektrisch fahrbereit oder bereits aktiv), 3=SignalUngueltig (ST_MOT_DRV_SignalUngueltig) (BNE original name: Signal ungültig)} "Status_E-Motor_Antrieb / status_motor_drive", transfer-property=TRIGGERED-ON-CHANGE, to EPS  # Status_E-Motor_Antrieb / status_motor_drive | LogicalInterface:BMW.POWERTRAIN.ENGINE.DrivingReadinessEngineStart[external]@Fahren; In diesem Signal wird der Zustand des Elektromotors angegeben. Status der Traktions-E-Maschine(n) lässt keinen Rückschluss auf die Hochvoltverfügbarkeit zu.
          signal ST_UDP: start 20, 4 bit, little-endian, base-type=uint8, invalid-value=value_15Dot0:15, compu {0=KeinSpannungseinbruch (ST_UDP_KeinSpannungseinbruch) (kein Spannungseinbruch angekündigt oder aktiv / BNE original name: Kein Spannungseinbruch), 1=StartspannungseinbruchBisMaximalSpannungsschwelle1 (ST_UDP_StartspannungseinbruchBisMaximalSpannungsschwelle1) (Spannungseinbruch bis Schwelle 1 aktiv (z.B. Ankündigung vor Einbruch, bei Ansteuerung Startsystem, Nachlauf nach Abwurf Startsystem bis Normalisierung des BN-Niveaus) Siehe GS95024-2-1 (Kap. 4.11.2.2) Warmstart / BNE original name: Startspannungseinbruch bis maximal Spannungsschwelle 1), 2=StartspannungseinbruchBisMaximalSpannungsschwelle2 (ST_UDP_StartspannungseinbruchBisMaximalSpannungsschwelle2) (Spannungseinbruch bis Schwelle 2 aktiv (z.B. Ankündigung vor Einbruch, bei Ansteuerung Startsystem, Nachlauf nach Abwurf Startsystem bis Normalisierung des BN-Niveaus) Siehe GS95024-2-1 (Kap. 4.11.2.1) Kaltstart / BNE original name: Startspannungseinbruch bis maximal Spannungsschwelle 2), 13=Funktionsschnittstelle_ist_nicht_verfuegbar (ST_UDP_Funktionsschnittstelle_ist_nicht_verfuegbar) (DME in der Initialisierung (z.B. nach Reset)), 14=Reserviert (ST_UDP_Reserviert) (Hinweis: Reserviert für funktionale Kennung Signal-Tag.), 15=Signal_unbefuellt (ST_UDP_Signal_unbefuellt) (Sendefunktion nicht in Betrieb)} "Status_Spannungseinbruch / status_voltage-drop", transfer-property=TRIGGERED-ON-CHANGE, to EPS  # Status_Spannungseinbruch / status_voltage-drop | LogicalInterface:BMW.POWERTRAIN.ENGINE.DrivingReadinessEngineStart[external]@Fahren; In diesem Signal wird der Startspannungseinbruch vor dem Start angekündigt (mindestens 70 ms vor dem Startspannungseinbruch) und behält den Zustand während des Startvorgangs bei. Die Entscheidung für einen Einbruch bis Spannungsschwelle 1 (Warmstart) bzw. Spannungsschwelle 2 (Kaltstart) wird anhand einer applizierbaren Motortemperaturschwelle getroffen. Der applizierte Wert entspricht der Temperaturschwelle von MSA. Codierung 0001 "Startspannungseinbruch bis maximal Spannungsschwelle 1" wird nur gesetzt, wenn zusätzlich kein MSA-Abschaltverhinderer durch SOC/SOH gesetzt ist. Der Spannungseinbruch basiert auf Temperaturabschätzung. Wird ein Einbruch auf Schwelle 1 oder 2 angekündigt, so erfolgt während des Starts bei geänderter Temperatur kein Wechsel auf die dann gültige Schwelle.
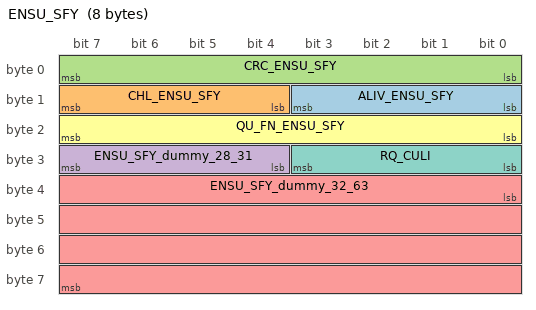
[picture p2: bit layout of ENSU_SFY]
      frame ENSU_SFY: to EPS, category=APPLICATION, frame-length=8, flexray-absolutely-scheduled-timing{communication-cycle=cycle-repetition={base-cycle=1, cycle-repetition=CYCLE-REPETITION-2}, slot-id=119}, allow-dynamic-l-sdu-length=false, payload-preamble-indicator=false  # Energieversorgung Sicherheit
        pdu ENSU_SFY: length=8, transmission-mode-true-timing=cyclic-timing=time-period={tolerance=absolute-tolerance=0.002, value=0.01}, unused-bit-pattern=255  # Energieversorgung Sicherheit | Die PDU enthält Informationen über den aktuellen Zustand der sicheren Energieversorgung sowie Kommandos um einen bestimmten Zustand der sicheren Energieversorgung einzustellen.
          signal ALIV_ENSU_SFY: start 8, 4 bit, little-endian, base-type=uint8, invalid-value=value_15Dot0:15, compu {identical}, range phys 0..14, to EPS  # Alive_Energieversorgung_Sicherheit / alive_energy-supply_safety | LogicalInterface:BMW.INFRASTRUCTURE.LOWVOLTAGE.EnergySupplySafe[internal]@Infrastruktur; Standardabsicherung Alivezähler laut Definition per Lastenheft Allgemeine Bordnetzkommunikation.
          signal CHL_ENSU_SFY: start 12, 4 bit, little-endian, base-type=uint8, invalid-value=value_15Dot0:15, compu {identical}, range phys 0..14, to EPS  # CHL_Energieversorgung_Sicherheit / CHL_energy-supply_safety | LogicalInterface:BMW.INFRASTRUCTURE.LOWVOLTAGE.EnergySupplySafe[internal]@Infrastruktur; Dieses Signal beinhaltet explizit den Wert der Erweiterungs-ID = 2 (dez) = 2 (hex) für den erweiterten Standardabsicherungs-Applikations-CRC und entspricht Bit 12-15 der Applikations-Data-ID (CRC-ID) des zughörigen CRC-Signals. Dieses Signal liegt im Bereich der für die Berechnung des CRC-Signales verwendet wird und muss empfängerseitig im Rahmen der CRC-Prüfung auf korrekte Befüllung geprüft werden. Nur wenn der Wert des Signales dem Sollwert entspricht ist und die Überprüfung des CRC-Signals positiv verläuft kann davon ausgegangen werden, dass die erwartete PDU fehlerfrei empfangen wurde. Das Signal kann den Wert 0 nicht annehmen um eine klare Differenzierung der 1A E2E-Protection (Autosar SWS 428) Anwendungsprofile 1A und 1C zu ermöglichen.
          signal CRC_ENSU_SFY: start 0, 8 bit, little-endian, base-type=uint8, compu-method=CompuMethodsForBoardnet/CRC8, data-constr=DataConstraints/CRC8, to EPS  # CRC_Energieversorgung_Sicherheit / CRC_energy-supply_safety | LogicalInterface:BMW.INFRASTRUCTURE.LOWVOLTAGE.EnergySupplySafe[internal]@Infrastruktur; Dieses Signal beinhaltet die CRC-Checksumme für die erweiterte Standardabsicherung mit Applikations-CRC nach Anwendungsprofil 1C E2E-Protection (Autosar SWS 428). Das Signal verwendet die Applikations-Data-ID (12 Bit) 628 (dez) = 274 (hex). Die Applikations-CRC-ID besteht aus zwei Teilen: 1.) Bit 0-7: 116 (dez) = 74 (hex). Dieser Wert wird nur als Startwert für die CRC8-Berechnung verwendet. (Vergleiche Anwendungsprofil 1A E2E-Protection (Autosar SWS 428)) 2.) Bit 8-11: 2 (dez) = 2 (hex). Dieser Wert wird NICHT für die CRC8-Berechnung verwendet sondern als explizit übertragene Erweiterungs-ID zur Unterscheidung der CRC-abgesicherten PDUs. Dieser Teil der Applikations-Data-ID geht also nicht in das CRC-Signal ein sondern wird im Wert des zugehörigen CHL-Signales abgebildet. Die Bits 8-11 der Appliktions-Data-ID entsprechen somit den Bits 12-15 der PDU.
          signal ENSU_SFY_dummy_28_31: start 28, 4 bit, little-endian, base-type=uint8, compu {identical}, range phys 0..15, to EPS
          signal ENSU_SFY_dummy_32_63: start 32, 32 bit, little-endian, base-type=uint32, compu {identical}, range phys 0..4294967295, to EPS
          signal QU_FN_ENSU_SFY: start 16, 8 bit, little-endian, base-type=uint8, invalid-value=value_255Dot0:255, compu {mask 240: 144=Sichere_Energieversorgung_aktiv (QU_FN_ENSU_SFY_Sichere_Energieversorgung_aktiv) (Zustand der sicheren Energieversorgung: Die sichere Energieversorgung ist aktiv, es liegt kein Fehler oder Vorwarnung vor.), mask 240: 176=Sichere_Energieversorgung_aktiv_Vorwarnung (QU_FN_ENSU_SFY_Sichere_Energieversorgung_aktiv_Vorwarnung) (Zustand der sicheren Energieversorgung: Die sichere Energieversorgung ist aktiv, es liegt eine Vorwarnung vor. Der Zustand kann wieder in _aktiv zurückwechseln oder in _nicht_verfügbar_Fehler wechseln.), mask 240: 96=Sichere_Energieversorgung_nicht_verfuegbar_Fehler (QU_FN_ENSU_SFY_Sichere_Energieversorgung_nicht_verfuegbar_Fehler) (Zustand der sicheren Energieversorgung: Die sichere Energieversorgung ist nicht verfügbar, weil ein Fehler vorliegt.), mask 15: 0=Sichere_Energieversorgung_Klasse_0 (QU_FN_ENSU_SFY_Sichere_Energieversorgung_Klasse_0) (Zusätzlich zum Zustand die Klasse der sicheren Energieversorgung: Es ist keine spezielle Ausprägung der sicheren Energieversorgung angefordert und umgesetzt. Die Klassen sind weder pauschal disjunkt noch pauschal überschneidend oder pauschal inkludierend.), mask 15: 1=Sichere_Energieversorgung_Klasse_1 (QU_FN_ENSU_SFY_Sichere_Energieversorgung_Klasse_1) (Zusätzlich zum Zustand die Klasse der sicheren Energieversorgung: Es ist eine spezielle Ausprägung der sicheren Energieversorgung angefordert und umgesetzt. Die Klassen sind weder pauschal disjunkt noch pauschal überschneidend oder pauschal inkludierend.), mask 15: 2=Sichere_Energieversorgung_Klasse_2 (QU_FN_ENSU_SFY_Sichere_Energieversorgung_Klasse_2) (Zusätzlich zum Zustand die Klasse der sicheren Energieversorgung: Es ist eine spezielle Ausprägung der sicheren Energieversorgung angefordert und umgesetzt. Die Klassen sind weder pauschal disjunkt noch pauschal überschneidend oder pauschal inkludierend.), mask 15: 3=Sichere_Energieversorgung_Klasse_3 (QU_FN_ENSU_SFY_Sichere_Energieversorgung_Klasse_3) (Zusätzlich zum Zustand die Klasse der sicheren Energieversorgung: Es ist eine spezielle Ausprägung der sicheren Energieversorgung angefordert und umgesetzt. Die Klassen sind weder pauschal disjunkt noch pauschal überschneidend oder pauschal inkludierend.), mask 15: 4=Sichere_Energieversorgung_Klasse_4 (QU_FN_ENSU_SFY_Sichere_Energieversorgung_Klasse_4) (Zusätzlich zum Zustand die Klasse der sicheren Energieversorgung: Es ist eine spezielle Ausprägung der sicheren Energieversorgung angefordert und umgesetzt. Die Klassen sind weder pauschal disjunkt noch pauschal überschneidend oder pauschal inkludierend.), mask 15: 5=Sichere_Energieversorgung_Klasse_5 (QU_FN_ENSU_SFY_Sichere_Energieversorgung_Klasse_5) (Zusätzlich zum Zustand die Klasse der sicheren Energieversorgung: Es ist eine spezielle Ausprägung der sicheren Energieversorgung angefordert und umgesetzt. Die Klassen sind weder pauschal disjunkt noch pauschal überschneidend oder pauschal inkludierend.), mask 255: 254=Funktion_meldet_Fehler (QU_FN_ENSU_SFY_Funktion_meldet_Fehler) (Sendefunktion in Betrieb, meldet Fehler), mask 255: 255=Signal_unbefuellt (QU_FN_ENSU_SFY_Signal_unbefuellt) (Sendefunktion nicht in Betrieb)} "Qualifier_Funktion_Energieversorgung_Sicherheit / Qualifier_function_energy-supply_safety", to EPS  # Qualifier_Funktion_Energieversorgung_Sicherheit / Qualifier_function_energy-supply_safety | LogicalInterface:BMW.INFRASTRUCTURE.LOWVOLTAGE.EnergySupplySafe[internal]@Infrastruktur; Funktions-Qualifier zur sicheren Energieversorgung.
          signal RQ_CULI: start 24, 4 bit, little-endian, base-type=uint8, invalid-value=value_15Dot0:15, compu-method=RQ_CULI_SFY, to EPS  # Anforderung_Strombegrenzung / request_current-limitation | LogicalInterface:BMW.INFRASTRUCTURE.LOWVOLTAGE.EnergySupplySafe[internal]@Infrastruktur; Das Signal kommandiert einen bestimmten Grad der Leistungseinschränkung an die Empfänger. Diese Leistungseinschränkung ist jeweils vereinbart und umfasst typischerweise einen maximalen Stromverbrauch, einen maximalen Stromgradienten und eine Integrität nach ASIL.
          mapping sigGroup_ENSU_SFY: i-signal-group=sigGroup_ENSU_SFY
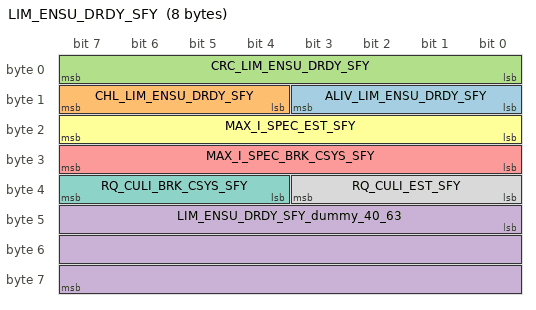
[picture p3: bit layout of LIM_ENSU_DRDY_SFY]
      frame LIM_ENSU_DRDY_SFY: to EPS, category=APPLICATION, frame-length=8, flexray-absolutely-scheduled-timing{communication-cycle=cycle-repetition={base-cycle=0, cycle-repetition=CYCLE-REPETITION-2}, slot-id=120}, allow-dynamic-l-sdu-length=false, payload-preamble-indicator=false  # Begrenzung Energieversorgung Fahrdynamik Sicherheit
        pdu LIM_ENSU_DRDY_SFY: length=8, transmission-mode-true-timing=cyclic-timing=time-period={tolerance=absolute-tolerance=0.002, value=0.01}, unused-bit-pattern=255  # Begrenzung Energieversorgung Fahrdynamik Sicherheit | Überträgt Strombegrenzungen bei Sicherheitsanforderung eines sicheren Energiebordnetzes an die Fahrdynamik-Aktuatoren.
          signal ALIV_LIM_ENSU_DRDY_SFY: start 8, 4 bit, little-endian, base-type=uint8, invalid-value=value_15Dot0:15, compu {identical}, range phys 0..14, to EPS  # Alive_Begrenzung_Energieversorgung_Fahrdynamik_Sicherheit / alive_limit_energy-supply_driving-dynamics_safety | LogicalInterface:BMW.POWERTRAIN.GENERATOR.EnergySupplySafe[internal]@Fahren; Standardabsicherung Alivezähler laut Definition per Lastenheft Allgemeine Bordnetzkommunikation.
          signal CHL_LIM_ENSU_DRDY_SFY: start 12, 4 bit, little-endian, base-type=uint8, invalid-value=value_15Dot0:15, compu {identical}, range phys 0..14, to EPS  # CHL_Begrenzung_Energieversorgung_Fahrdynamik_Sicherheit / CHL_limit_energy-supply_driving-dynamics_safety | LogicalInterface:BMW.POWERTRAIN.GENERATOR.EnergySupplySafe[internal]@Fahren; Dieses Signal beinhaltet explizit den Wert der Erweiterungs-ID =1 (dez) = 1 (hex) für die erweiterte CRC-Absicherung gemäß Autosar_SWS_E2ELibrary Profil 1C. Es enthält die Bits 12-15 der Applikations-Data-ID (CRC-ID) des zughörigen CRC-Signals. Dieses Signal liegt im Bereich der Daten die in die Berechnung des CRC-Signales eingehen und muss empfängerseitig im Rahmen der CRC-Prüfung auf korrekte Befüllung geprüft werden. Nur wenn der Wert des Signales dem Sollwert entspricht ist und die Überprüfung des CRC-Signals positiv verläuft kann davon ausgegangen werden, dass die erwartete PDU fehlerfrei empfangen wurde.
          signal CRC_LIM_ENSU_DRDY_SFY: start 0, 8 bit, little-endian, base-type=uint8, compu-method=CompuMethodsForBoardnet/CRC8, data-constr=DataConstraints/CRC8, to EPS  # CRC_Begrenzung_Energieversorgung_Fahrdynamik_Sicherheit / CRC_limit_energy-supply_driving-dynamics_safety | LogicalInterface:BMW.POWERTRAIN.GENERATOR.EnergySupplySafe[internal]@Fahren; Dieses Signal beinhaltet die CRC-Checksumme für die erweiterte Standardabsicherung mit Applikations-CRC nach Anwendungsprofil 1C E2E-Protection (Autosar SWS 428). Dem Signal ist die Applikations-Data-ID (12 Bit) 372 (dez) = 174 (hex) zugeordnet. Die ID wird verwendet zur Konfiguration der Absicherung gemäß Autosar_SWS_E2ELibrary Profil 1C. Erläuterung: Die Applikations-CRC-ID besteht aus zwei Teilen die wie folgt interpretiert werden können: 1. Bit 0-7: 116 (dez) = 74 (hex). Dieser Wert wird als Startwert für die CRC8-Berechnung verwendet. (Entspricht der DataID von Anwendungsprofil 1A Autosar_SWS_E2ELibrary) 2. Bit 8-11: 1 (dez) = 1 (hex). Mit diesem Wert wird das CHL-Signal (Bits 12-15) bedatet. Dieses dient der Unterscheidung von CRC-abgesicherten PDUs, deren Low-Byte der CRC-ID sich nicht unterscheidet. Das CHL-Signal ist Teil der CRC-abgesicherten Daten und die Überprüfung ob es den korrekten Wert enthält ist Teil der E2E-Absicherung.
          signal LIM_ENSU_DRDY_SFY_dummy_40_63: start 40, 24 bit, little-endian, base-type=uint32, compu {identical}, range phys 0..16777215, to EPS
          signal MAX_I_SPEC_BRK_CSYS_SFY: start 24, 8 bit, little-endian, base-type=uint8, invalid-value=value_255Dot0:255, compu-method=MAX_I_SPEC_SFY, data-constr=MAX_I_SPEC_SFY, to EPS  # Maximal_Strom_Vorgabe_Bremse_Regelsystem_Sicherheit / maximum_current_specification_brake_control-system_safety | LogicalInterface:BMW.POWERTRAIN.GENERATOR.EnergySupplySafe[internal]@Fahren; In diesem Signal wird der maximal dem Bremsregelsystem zur Verfügung stehende Strom kommuniziert.
          signal MAX_I_SPEC_EST_SFY: start 16, 8 bit, little-endian, base-type=uint8, invalid-value=value_255Dot0:255, compu-method=MAX_I_SPEC_SFY, data-constr=MAX_I_SPEC_SFY, to EPS  # Maximal_Strom_Vorgabe_Elektrische-Lenkung_Sicherheit / maximum_current_specification_electrical-steering_safety | LogicalInterface:BMW.POWERTRAIN.GENERATOR.EnergySupplySafe[internal]@Fahren; In diesem Signal wird der maximal der elektrischen Lenkung zur Verfügung stehende Strom kommuniziert.
          signal RQ_CULI_BRK_CSYS_SFY: start 36, 4 bit, little-endian, base-type=uint8, invalid-value=value_15Dot0:15, compu-method=RQ_CULI_SFY, to EPS  # Anforderung_Strombegrenzung_Bremse_Regelsystem_Sicherheit / request_current-limitation_brake_control-system_safety | LogicalInterface:BMW.POWERTRAIN.GENERATOR.EnergySupplySafe[internal]@Fahren; In diesem Signal wird dem Bremsregelsystem übermittelt, ob und in welchem Umfang Anforderungen an eine Strombegrenzung des Bremsregelsystems bestehen.
          signal RQ_CULI_EST_SFY: start 32, 4 bit, little-endian, base-type=uint8, invalid-value=value_15Dot0:15, compu-method=RQ_CULI_SFY, to EPS  # Anforderung_Strombegrenzung_Elektrische-Lenkung_Sicherheit / request_current-limitation_electrical-steering_safety | LogicalInterface:BMW.POWERTRAIN.GENERATOR.EnergySupplySafe[internal]@Fahren; In diesem Signal wird der Elektrischen Lenkung übermittelt, ob und in welchem Umfang Anforderungen an eine Strombegrenzung der elektrischen Lenkung bestehen.
          mapping sigGroup_LIM_ENSU_DRDY_SFY: i-signal-group=sigGroup_LIM_ENSU_DRDY_SFY
      frame xcpstatic: from EPS, category=XCP_RUNTIME_CONFIGURED, frame-length=16, flexray-absolutely-scheduled-timing{communication-cycle=cycle-repetition={base-cycle=0, cycle-repetition=CYCLE-REPETITION-1}, slot-id=12}, allow-dynamic-l-sdu-length=false, payload-preamble-indicator=false  # XCP Bereich Statisch / XCP Frame Static | Dieser Frame dient als Platzhalter für die XCP-Konfiguration für FlexRay (s. LH FlexRay) und zur Pufferkonfiguration der FlexRay-Controller. Der statische XCP-Bereich wird auch durch das Projekt "Funktionstrace" mitbenutzt. Ansprechpartner ist Florian Kuttig oder Christian Pigorsch. / Dummyframe für Infrastruktur XCP
        carries pdu dummy16bstatic: packing-byte-order=little-endian, start-position=0
